VERSION "Vinfast Initial LGC"

NS_ :

BS_:

BU_: CHARGER_S VCU CHARGER_C HMI MCU REFLASH BMS1 BMS0 CLU

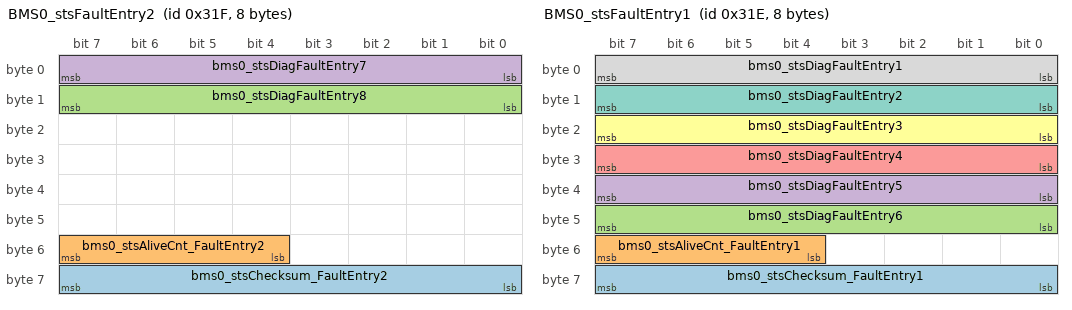
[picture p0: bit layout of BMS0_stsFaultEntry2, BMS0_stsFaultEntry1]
BO_ 799 BMS0_stsFaultEntry2: 8 BMS0
 SG_ bms0_stsChecksum_FaultEntry2 : 56|8@1+ (1,0) [0|255] ""  VCU
 SG_ bms0_stsAliveCnt_FaultEntry2 : 52|4@1+ (1,0) [0|15] ""  VCU
 SG_ bms0_stsDiagFaultEntry8 : 8|8@1+ (1,0) [0|255] ""  VCU
 SG_ bms0_stsDiagFaultEntry7 : 0|8@1+ (1,0) [0|255] ""  VCU

BO_ 798 BMS0_stsFaultEntry1: 8 BMS0
 SG_ bms0_stsChecksum_FaultEntry1 : 56|8@1+ (1,0) [0|255] ""  VCU
 SG_ bms0_stsAliveCnt_FaultEntry1 : 52|4@1+ (1,0) [0|15] ""  VCU
 SG_ bms0_stsDiagFaultEntry6 : 40|8@1+ (1,0) [0|255] ""  VCU
 SG_ bms0_stsDiagFaultEntry5 : 32|8@1+ (1,0) [0|255] ""  VCU
 SG_ bms0_stsDiagFaultEntry4 : 24|8@1+ (1,0) [0|255] ""  VCU
 SG_ bms0_stsDiagFaultEntry3 : 16|8@1+ (1,0) [0|255] ""  VCU
 SG_ bms0_stsDiagFaultEntry2 : 8|8@1+ (1,0) [0|255] ""  VCU
 SG_ bms0_stsDiagFaultEntry1 : 0|8@1+ (1,0) [0|255] ""  VCU

BO_ 780 VCU_TestMessageDiag: 8 VCU
 SG_ vfVCU_TestCmdChecksumOnOff_32F : 63|1@1+ (1,0) [0|1] "-"  BMS1,BMS0
 SG_ vfVCU_TestCmdChecksumOnOff_32E : 62|1@1+ (1,0) [0|1] "-"  BMS1,BMS0
 SG_ vfVCU_TestCmdChecksumOnOff_32A : 61|1@1+ (1,0) [0|1] "-"  BMS1,BMS0
 SG_ vfVCU_TestCmdChecksumOnOff_329 : 60|1@1+ (1,0) [0|1] "-"  BMS1,BMS0
 SG_ vfVCU_TestCmdChecksumOnOff_328 : 59|1@1+ (1,0) [0|1] "-"  BMS1,BMS0
 SG_ vfVCU_TestCmdChecksumOnOff_326 : 58|1@1+ (1,0) [0|1] "-"  BMS1,BMS0
 SG_ vfVCU_TestCmdChecksumOnOff_324 : 57|1@1+ (1,0) [0|1] "-"  BMS1,BMS0
 SG_ vfVCU_TestCmdChecksumOnOff_323 : 56|1@1+ (1,0) [0|1] "-"  BMS1,BMS0
 SG_ vfVCU_TestCmdChecksumOnOff_322 : 55|1@1+ (1,0) [0|1] "-"  BMS1,BMS0
 SG_ vfVCU_TestCmdChecksumOnOff_321 : 54|1@1+ (1,0) [0|1] "-"  BMS1,BMS0
 SG_ vfVCU_TestCmdChecksumOnOff_320 : 53|1@1+ (1,0) [0|1] "-"  BMS1,BMS0
 SG_ vfVCU_TestCmdChecksumOnOff_31F : 52|1@1+ (1,0) [0|1] "-"  BMS1,BMS0
 SG_ vfVCU_TestCmdChecksumOnOff_31E : 51|1@1+ (1,0) [0|1] "-"  BMS1,BMS0
 SG_ vfVCU_TestCmdChecksumOnOff_31A : 50|1@1+ (1,0) [0|1] "-"  BMS1,BMS0
 SG_ vfVCU_TestCmdChecksumOnOff_319 : 49|1@1+ (1,0) [0|1] "-"  BMS1,BMS0
 SG_ vfVCU_TestCmdChecksumOnOff_318 : 48|1@1+ (1,0) [0|1] "-"  BMS1,BMS0
 SG_ vfVCU_TestCmdChecksumOnOff_316 : 47|1@1+ (1,0) [0|1] "-"  BMS1,BMS0
 SG_ vfVCU_TestCmdChecksumOnOff_314 : 46|1@1+ (1,0) [0|1] "-"  BMS1,BMS0
 SG_ vfVCU_TestCmdChecksumOnOff_313 : 45|1@1+ (1,0) [0|1] "-"  BMS1,BMS0
 SG_ vfVCU_TestCmdChecksumOnOff_312 : 44|1@1+ (1,0) [0|1] "-"  BMS1,BMS0
 SG_ vfVCU_TestCmdChecksumOnOff_311 : 43|1@1+ (1,0) [0|1] "-"  BMS1,BMS0
 SG_ vfVCU_TestCmdChecksumOnOff_310 : 42|1@1+ (1,0) [0|1] "-"  BMS1,BMS0
 SG_ vfVCU_TestCmdAliveCntOnOff_32F : 39|1@1+ (1,0) [0|1] "-"  BMS1,BMS0
 SG_ vfVCU_TestCmdAliveCntOnOff_32E : 38|1@1+ (1,0) [0|1] "-"  BMS1,BMS0
 SG_ vfVCU_TestCmdAliveCntOnOff_32A : 37|1@1+ (1,0) [0|1] "-"  BMS1,BMS0
 SG_ vfVCU_TestCmdAliveCntOnOff_329 : 36|1@1+ (1,0) [0|1] "-"  BMS1,BMS0
 SG_ vfVCU_TestCmdAliveCntOnOff_328 : 35|1@1+ (1,0) [0|1] "-"  BMS1,BMS0
 SG_ vfVCU_TestCmdAliveCntOnOff_326 : 34|1@1+ (1,0) [0|1] "-"  BMS1,BMS0
 SG_ vfVCU_TestCmdAliveCntOnOff_324 : 33|1@1+ (1,0) [0|1] "-"  BMS1,BMS0
 SG_ vfVCU_TestCmdAliveCntOnOff_323 : 32|1@1+ (1,0) [0|1] "-"  BMS1,BMS0
 SG_ vfVCU_TestCmdAliveCntOnOff_322 : 31|1@1+ (1,0) [0|1] "-"  BMS1,BMS0
 SG_ vfVCU_TestCmdAliveCntOnOff_321 : 30|1@1+ (1,0) [0|1] "-"  BMS1,BMS0
 SG_ vfVCU_TestCmdAliveCntOnOff_320 : 29|1@1+ (1,0) [0|1] "-"  BMS1,BMS0
 SG_ vfVCU_TestCmdAliveCntOnOff_31F : 28|1@1+ (1,0) [0|1] "-"  BMS1,BMS0
 SG_ vfVCU_TestCmdAliveCntOnOff_31E : 27|1@1+ (1,0) [0|1] "-"  BMS1,BMS0
 SG_ vfVCU_TestCmdAliveCntOnOff_31A : 26|1@1+ (1,0) [0|1] "-"  BMS1,BMS0
 SG_ vfVCU_TestCmdAliveCntOnOff_319 : 25|1@1+ (1,0) [0|1] "-"  BMS1,BMS0
 SG_ vfVCU_TestCmdAliveCntOnOff_318 : 24|1@1+ (1,0) [0|1] "-"  BMS1,BMS0
 SG_ vfVCU_TestCmdAliveCntOnOff_316 : 23|1@1+ (1,0) [0|1] "-"  BMS1,BMS0
 SG_ vfVCU_TestCmdAliveCntOnOff_314 : 22|1@1+ (1,0) [0|1] "-"  BMS1,BMS0
 SG_ vfVCU_TestCmdAliveCntOnOff_313 : 21|1@1+ (1,0) [0|1] "-"  BMS1,BMS0
 SG_ vfVCU_TestCmdAliveCntOnOff_312 : 20|1@1+ (1,0) [0|1] "-"  BMS1,BMS0
 SG_ vfVCU_TestCmdAliveCntOnOff_311 : 19|1@1+ (1,0) [0|1] "-"  BMS1,BMS0
 SG_ vfVCU_TestCmdAliveCntOnOff_310 : 18|1@1+ (1,0) [0|1] "-"  BMS1,BMS0

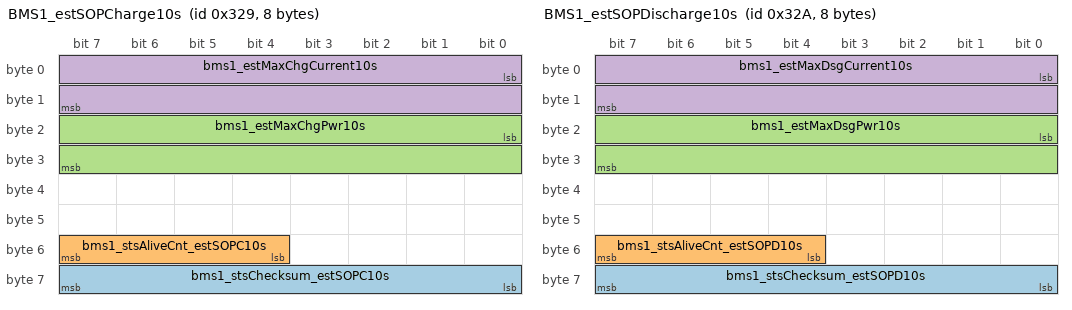
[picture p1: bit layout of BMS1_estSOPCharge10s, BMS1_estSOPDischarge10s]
BO_ 809 BMS1_estSOPCharge10s: 8 BMS1
 SG_ bms1_stsChecksum_estSOPC10s : 56|8@1+ (1,0) [0|255] ""  VCU
 SG_ bms1_stsAliveCnt_estSOPC10s : 52|4@1+ (1,0) [0|15] ""  VCU
 SG_ bms1_estMaxChgPwr10s : 16|16@1- (1,0) [-32767|32767] "W"  VCU
 SG_ bms1_estMaxChgCurrent10s : 0|16@1- (0.02,0) [-655|655] "A"  VCU

BO_ 810 BMS1_estSOPDischarge10s: 8 BMS1
 SG_ bms1_stsChecksum_estSOPD10s : 56|8@1+ (1,0) [0|255] ""  VCU
 SG_ bms1_stsAliveCnt_estSOPD10s : 52|4@1+ (1,0) [0|15] ""  VCU
 SG_ bms1_estMaxDsgPwr10s : 16|16@1- (1,0) [-32767|32767] "W"  VCU
 SG_ bms1_estMaxDsgCurrent10s : 0|16@1- (0.02,0) [-655|655] "A"  VCU

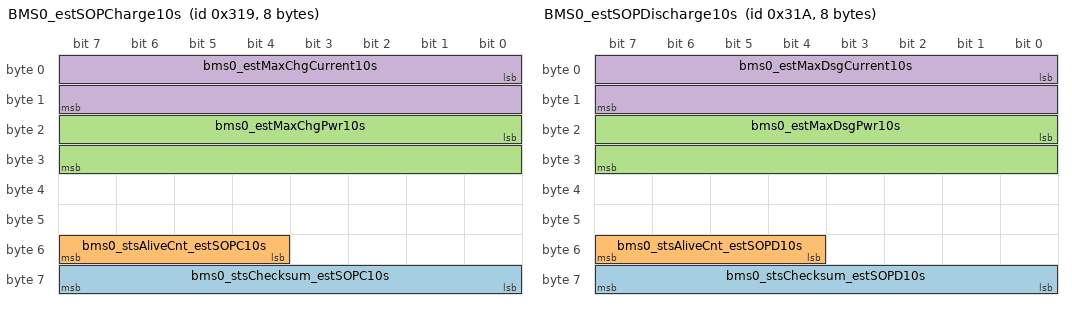
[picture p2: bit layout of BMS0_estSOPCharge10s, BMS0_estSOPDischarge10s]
BO_ 793 BMS0_estSOPCharge10s: 8 BMS0
 SG_ bms0_stsChecksum_estSOPC10s : 56|8@1+ (1,0) [0|255] ""  VCU
 SG_ bms0_stsAliveCnt_estSOPC10s : 52|4@1+ (1,0) [0|15] ""  VCU
 SG_ bms0_estMaxChgPwr10s : 16|16@1- (1,0) [-32767|32767] "W"  VCU
 SG_ bms0_estMaxChgCurrent10s : 0|16@1- (0.02,0) [-655|655] "A"  VCU

BO_ 794 BMS0_estSOPDischarge10s: 8 BMS0
 SG_ bms0_stsChecksum_estSOPD10s : 56|8@1+ (1,0) [0|255] ""  VCU
 SG_ bms0_stsAliveCnt_estSOPD10s : 52|4@1+ (1,0) [0|15] ""  VCU
 SG_ bms0_estMaxDsgPwr10s : 16|16@1- (1,0) [-32767|32767] "W"  VCU
 SG_ bms0_estMaxDsgCurrent10s : 0|16@1- (0.02,0) [-655|655] "A"  VCU

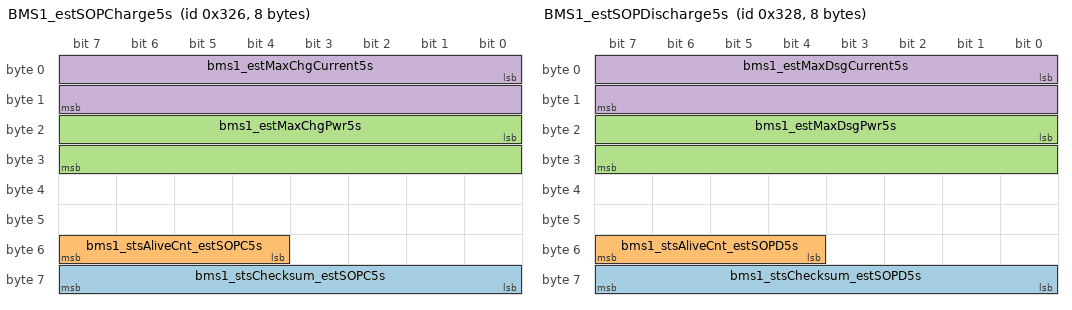
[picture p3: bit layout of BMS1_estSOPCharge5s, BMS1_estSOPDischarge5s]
BO_ 806 BMS1_estSOPCharge5s: 8 BMS1
 SG_ bms1_stsChecksum_estSOPC5s : 56|8@1+ (1,0) [0|255] ""  VCU
 SG_ bms1_stsAliveCnt_estSOPC5s : 52|4@1+ (1,0) [0|15] ""  VCU
 SG_ bms1_estMaxChgPwr5s : 16|16@1- (1,0) [-32767|32767] "W"  VCU
 SG_ bms1_estMaxChgCurrent5s : 0|16@1- (0.02,0) [-655|655] "A"  VCU

BO_ 808 BMS1_estSOPDischarge5s: 8 BMS1
 SG_ bms1_stsChecksum_estSOPD5s : 56|8@1+ (1,0) [0|255] ""  VCU
 SG_ bms1_stsAliveCnt_estSOPD5s : 52|4@1+ (1,0) [0|15] ""  VCU
 SG_ bms1_estMaxDsgPwr5s : 16|16@1- (1,0) [-32767|32767] "W"  VCU
 SG_ bms1_estMaxDsgCurrent5s : 0|16@1- (0.02,0) [-655|655] "A"  VCU

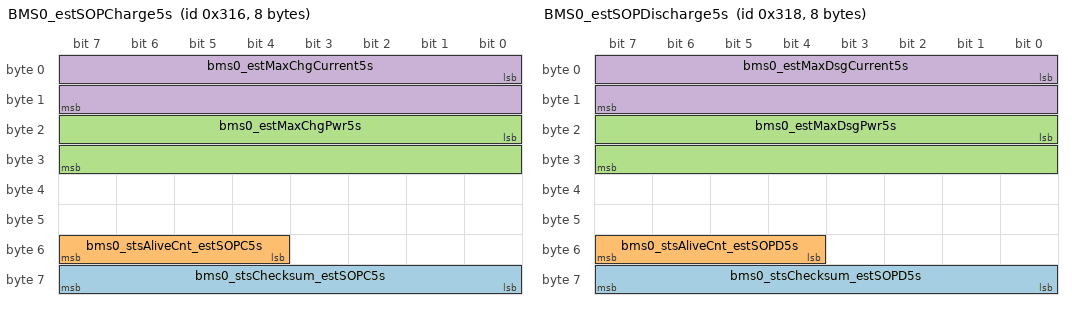
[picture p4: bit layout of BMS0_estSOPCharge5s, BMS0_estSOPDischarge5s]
BO_ 790 BMS0_estSOPCharge5s: 8 BMS0
 SG_ bms0_stsChecksum_estSOPC5s : 56|8@1+ (1,0) [0|255] ""  VCU
 SG_ bms0_stsAliveCnt_estSOPC5s : 52|4@1+ (1,0) [0|15] ""  VCU
 SG_ bms0_estMaxChgPwr5s : 16|16@1- (1,0) [-32767|32767] "W"  VCU
 SG_ bms0_estMaxChgCurrent5s : 0|16@1- (0.02,0) [-655|655] "A"  VCU

BO_ 792 BMS0_estSOPDischarge5s: 8 BMS0
 SG_ bms0_stsChecksum_estSOPD5s : 56|8@1+ (1,0) [0|255] ""  VCU
 SG_ bms0_stsAliveCnt_estSOPD5s : 52|4@1+ (1,0) [0|15] ""  VCU
 SG_ bms0_estMaxDsgPwr5s : 16|16@1- (1,0) [-32767|32767] "W"  VCU
 SG_ bms0_estMaxDsgCurrent5s : 0|16@1- (0.02,0) [-655|655] "A"  VCU

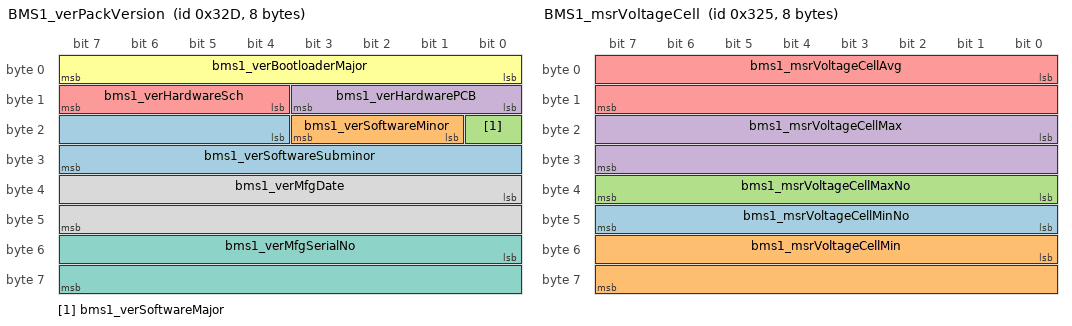
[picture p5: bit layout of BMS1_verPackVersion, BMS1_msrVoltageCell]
BO_ 813 BMS1_verPackVersion: 8 BMS1
 SG_ bms1_verSoftwareSubminor : 20|12@1+ (1,0) [0|4095] ""  BMS0,VCU
 SG_ bms1_verSoftwareMinor : 17|3@1+ (1,0) [0|7] ""  BMS0,VCU
 SG_ bms1_verSoftwareMajor : 16|1@1+ (1,0) [0|1] ""  BMS0,VCU
 SG_ bms1_verHardwarePCB : 8|4@1+ (1,0) [0|15] ""  BMS0,VCU
 SG_ bms1_verHardwareSch : 12|4@1+ (1,0) [0|15] ""  BMS0,VCU
 SG_ bms1_verBootloaderMajor : 0|8@1+ (1,0) [0|15] ""  BMS0,VCU
 SG_ bms1_verMfgSerialNo : 48|16@1+ (1,0) [0|65535] ""  BMS0,VCU
 SG_ bms1_verMfgDate : 32|16@1+ (1,0) [0|65535] ""  BMS0,VCU

BO_ 811 BMS1_stsAccumMileage: 8 BMS1
 SG_ bms1_stsAccumMileage : 0|32@1+ (1,0) [0|4294967295] "km"  VCU

BO_ 805 BMS1_msrVoltageCell: 8 BMS1
 SG_ bms1_msrVoltageCellMinNo : 40|8@1+ (1,0) [0|255] "Bank"  VCU
 SG_ bms1_msrVoltageCellMin : 48|16@1+ (0.0001,0) [0|6.5535] "V"  VCU
 SG_ bms1_msrVoltageCellMaxNo : 32|8@1+ (1,0) [0|255] "Bank"  VCU
 SG_ bms1_msrVoltageCellMax : 16|16@1+ (0.0001,0) [0|6.5535] "V"  VCU
 SG_ bms1_msrVoltageCellAvg : 0|16@1+ (0.0001,0) [0|6.5535] "V"  VCU

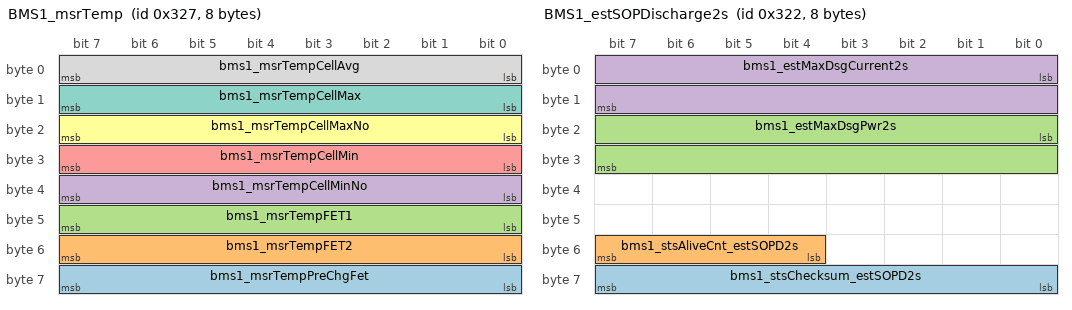
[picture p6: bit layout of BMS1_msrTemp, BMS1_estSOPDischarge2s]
BO_ 807 BMS1_msrTemp: 8 BMS1
 SG_ bms1_msrTempPreChgFet : 56|8@1- (1,0) [-127|127] "℃"  VCU
 SG_ bms1_msrTempFET2 : 48|8@1- (1,0) [-127|127] "℃"  VCU
 SG_ bms1_msrTempFET1 : 40|8@1- (1,0) [-128|127] "℃"  VCU
 SG_ bms1_msrTempCellMinNo : 32|8@1+ (1,0) [0|255] "Th"  VCU
 SG_ bms1_msrTempCellMin : 24|8@1- (1,0) [-127|127] "℃"  VCU
 SG_ bms1_msrTempCellMaxNo : 16|8@1+ (1,0) [0|255] "Th"  VCU
 SG_ bms1_msrTempCellMax : 8|8@1- (1,0) [-127|127] "℃"  VCU
 SG_ bms1_msrTempCellAvg : 0|8@1- (1,0) [-127|127] "℃"  VCU

BO_ 802 BMS1_estSOPDischarge2s: 8 BMS1
 SG_ bms1_stsChecksum_estSOPD2s : 56|8@1+ (1,0) [0|255] ""  VCU
 SG_ bms1_stsAliveCnt_estSOPD2s : 52|4@1+ (1,0) [0|15] ""  VCU
 SG_ bms1_estMaxDsgPwr2s : 16|16@1- (1,0) [-32767|32767] "W"  VCU
 SG_ bms1_estMaxDsgCurrent2s : 0|16@1- (0.02,0) [-655|655] "A"  VCU

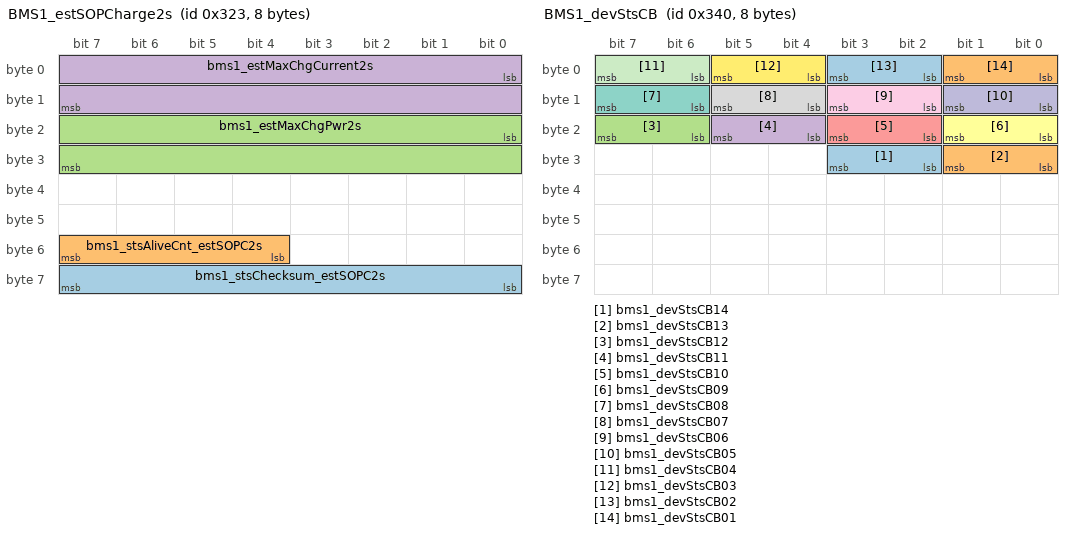
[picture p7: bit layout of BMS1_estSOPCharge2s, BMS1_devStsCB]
BO_ 803 BMS1_estSOPCharge2s: 8 BMS1
 SG_ bms1_stsChecksum_estSOPC2s : 56|8@1+ (1,0) [0|255] ""  VCU
 SG_ bms1_stsAliveCnt_estSOPC2s : 52|4@1+ (1,0) [0|15] ""  VCU
 SG_ bms1_estMaxChgPwr2s : 16|16@1- (1,0) [-32767|32767] "W"  VCU
 SG_ bms1_estMaxChgCurrent2s : 0|16@1- (0.02,0) [-655|655] "A"  VCU

BO_ 832 BMS1_devStsCB: 8 BMS1
 SG_ bms1_devStsCB14 : 26|2@1+ (1,0) [0|3] ""  VCU
 SG_ bms1_devStsCB13 : 24|2@1+ (1,0) [0|3] ""  VCU
 SG_ bms1_devStsCB12 : 22|2@1+ (1,0) [0|3] ""  VCU
 SG_ bms1_devStsCB11 : 20|2@1+ (1,0) [0|3] ""  VCU
 SG_ bms1_devStsCB10 : 18|2@1+ (1,0) [0|3] ""  VCU
 SG_ bms1_devStsCB09 : 16|2@1+ (1,0) [0|3] ""  VCU
 SG_ bms1_devStsCB08 : 14|2@1+ (1,0) [0|3] ""  VCU
 SG_ bms1_devStsCB07 : 12|2@1+ (1,0) [0|3] ""  VCU
 SG_ bms1_devStsCB06 : 10|2@1+ (1,0) [0|3] ""  VCU
 SG_ bms1_devStsCB05 : 8|2@1+ (1,0) [0|3] ""  VCU
 SG_ bms1_devStsCB04 : 6|2@1+ (1,0) [0|3] ""  VCU
 SG_ bms1_devStsCB03 : 4|2@1+ (1,0) [0|3] ""  VCU
 SG_ bms1_devStsCB02 : 2|2@1+ (1,0) [0|3] ""  VCU
 SG_ bms1_devStsCB01 : 0|2@1+ (1,0) [0|3] ""  VCU

BO_ 838 BMS1_devMsrTemp: 8 BMS1
 SG_ bms1_devCbOnCnt : 24|8@1+ (1,0) [0|255] "" Vector__XXX
 SG_ bms1_devTopCellOffset : 16|8@1+ (1,0) [0|255] "mV" Vector__XXX
 SG_ bms1_devVoltageCellDiff : 8|8@1+ (1,0) [0|255] "mV" Vector__XXX
 SG_ bms1_devMsrTempCB1 : 0|8@1- (1,0) [-127|127] "℃"  VCU

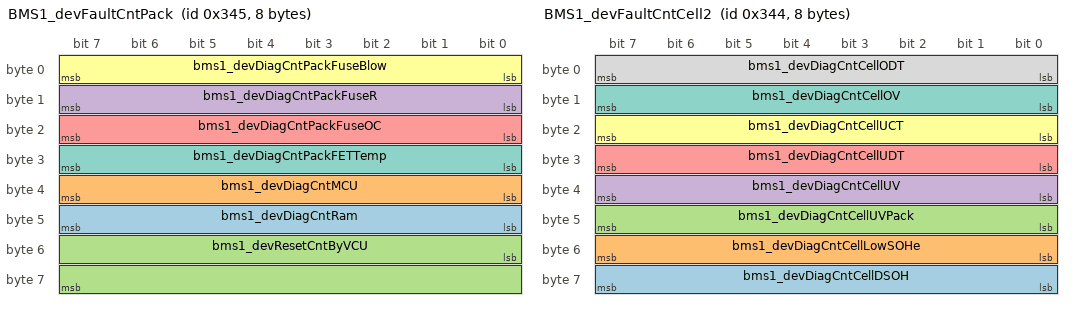
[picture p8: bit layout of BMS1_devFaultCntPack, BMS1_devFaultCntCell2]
BO_ 837 BMS1_devFaultCntPack: 8 BMS1
 SG_ bms1_devDiagCntRam : 40|8@1+ (1,0) [0|255] "" Vector__XXX
 SG_ bms1_devDiagCntMCU : 32|8@1+ (1,0) [0|255] "" Vector__XXX
 SG_ bms1_devResetCntByVCU : 48|16@1+ (1,0) [0|65535] "" Vector__XXX
 SG_ bms1_devDiagCntPackFuseR : 8|8@1+ (1,0) [0|255] ""  VCU
 SG_ bms1_devDiagCntPackFuseOC : 16|8@1+ (1,0) [0|255] ""  VCU
 SG_ bms1_devDiagCntPackFuseBlow : 0|8@1+ (1,0) [0|255] ""  VCU
 SG_ bms1_devDiagCntPackFETTemp : 24|8@1+ (1,0) [0|255] ""  VCU

BO_ 836 BMS1_devFaultCntCell2: 8 BMS1
 SG_ bms1_devDiagCntCellDSOH : 56|8@1+ (1,0) [0|255] "" Vector__XXX
 SG_ bms1_devDiagCntCellLowSOHe : 48|8@1+ (1,0) [0|255] "" Vector__XXX
 SG_ bms1_devDiagCntCellUVPack : 40|8@1+ (1,0) [0|255] ""  VCU
 SG_ bms1_devDiagCntCellUV : 32|8@1+ (1,0) [0|255] ""  VCU
 SG_ bms1_devDiagCntCellUDT : 24|8@1+ (1,0) [0|255] ""  VCU
 SG_ bms1_devDiagCntCellUCT : 16|8@1+ (1,0) [0|255] ""  VCU
 SG_ bms1_devDiagCntCellOV : 8|8@1+ (1,0) [0|255] ""  VCU
 SG_ bms1_devDiagCntCellODT : 0|8@1+ (1,0) [0|255] ""  VCU

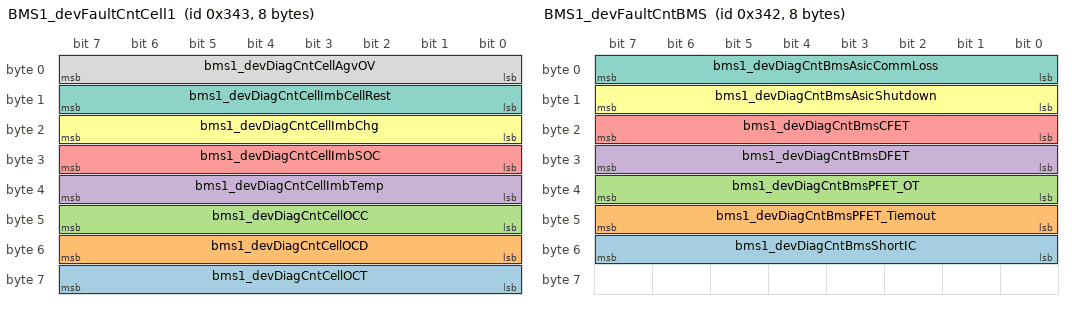
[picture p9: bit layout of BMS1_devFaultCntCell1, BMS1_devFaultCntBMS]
BO_ 835 BMS1_devFaultCntCell1: 8 BMS1
 SG_ bms1_devDiagCntCellOCT : 56|8@1+ (1,0) [0|255] ""  VCU
 SG_ bms1_devDiagCntCellOCD : 48|8@1+ (1,0) [0|255] ""  VCU
 SG_ bms1_devDiagCntCellOCC : 40|8@1+ (1,0) [0|255] ""  VCU
 SG_ bms1_devDiagCntCellImbTemp : 32|8@1+ (1,0) [0|255] ""  VCU
 SG_ bms1_devDiagCntCellImbSOC : 24|8@1+ (1,0) [0|255] ""  VCU
 SG_ bms1_devDiagCntCellImbChg : 16|8@1+ (1,0) [0|255] ""  VCU
 SG_ bms1_devDiagCntCellImbCellRest : 8|8@1+ (1,0) [0|255] ""  VCU
 SG_ bms1_devDiagCntCellAgvOV : 0|8@1+ (1,0) [0|255] ""  VCU

BO_ 834 BMS1_devFaultCntBMS: 8 BMS1
 SG_ bms1_devDiagCntBmsShortIC : 48|8@1+ (1,0) [0|255] "" Vector__XXX
 SG_ bms1_devDiagCntBmsPFET_Tiemout : 40|8@1+ (1,0) [0|255] ""  VCU
 SG_ bms1_devDiagCntBmsPFET_OT : 32|8@1+ (1,0) [0|255] ""  VCU
 SG_ bms1_devDiagCntBmsDFET : 24|8@1+ (1,0) [0|255] ""  VCU
 SG_ bms1_devDiagCntBmsCFET : 16|8@1+ (1,0) [0|255] ""  VCU
 SG_ bms1_devDiagCntBmsAsicShutdown : 8|8@1+ (1,0) [0|255] ""  VCU
 SG_ bms1_devDiagCntBmsAsicCommLoss : 0|8@1+ (1,0) [0|255] ""  VCU

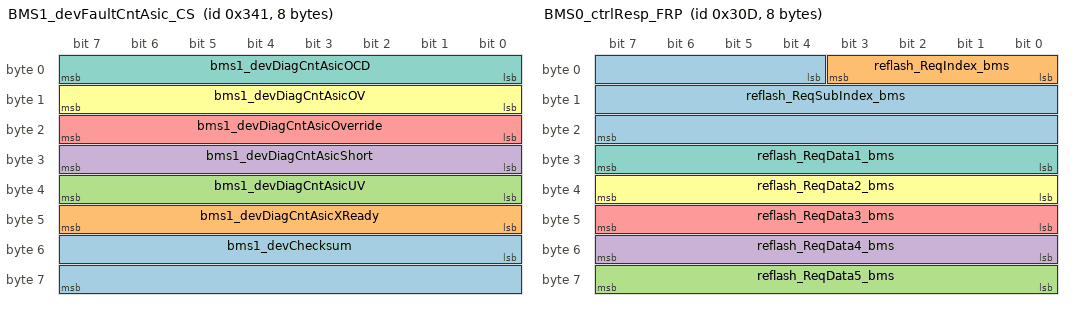
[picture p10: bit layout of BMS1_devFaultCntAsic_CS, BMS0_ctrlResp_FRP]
BO_ 833 BMS1_devFaultCntAsic_CS: 8 BMS1
 SG_ bms1_devChecksum : 48|16@1+ (1,0) [0|65535] "" Vector__XXX
 SG_ bms1_devDiagCntAsicXReady : 40|8@1+ (1,0) [0|255] ""  VCU
 SG_ bms1_devDiagCntAsicUV : 32|8@1+ (1,0) [0|255] ""  VCU
 SG_ bms1_devDiagCntAsicShort : 24|8@1+ (1,0) [0|255] ""  VCU
 SG_ bms1_devDiagCntAsicOverride : 16|8@1+ (1,0) [0|255] ""  VCU
 SG_ bms1_devDiagCntAsicOV : 8|8@1+ (1,0) [0|255] ""  VCU
 SG_ bms1_devDiagCntAsicOCD : 0|8@1+ (1,0) [0|255] ""  VCU

BO_ 843 BMS1_devCellVolt3: 8 BMS1
 SG_ bms1_devVoltageCell14 : 16|16@1+ (0.0001,0) [0|6.5535] "V"  VCU
 SG_ bms1_devVoltageCell13 : 0|16@1+ (0.0001,0) [0|6.5535] "V"  VCU

BO_ 842 BMS1_devCellVolt2: 8 BMS1
 SG_ bms1_devVoltageCell12 : 48|16@1+ (0.0001,0) [0|6.5535] "V"  VCU
 SG_ bms1_devVoltageCell11 : 32|16@1+ (0.0001,0) [0|6.5535] "V"  VCU
 SG_ bms1_devVoltageCell10 : 16|16@1+ (0.0001,0) [0|6.5535] "V"  VCU
 SG_ bms1_devVoltageCell09 : 0|16@1+ (0.0001,0) [0|6.5535] "V"  VCU

BO_ 841 BMS1_devCellVolt1: 8 BMS1
 SG_ bms1_devVoltageCell08 : 48|16@1+ (0.0001,0) [0|6.5535] "V"  VCU
 SG_ bms1_devVoltageCell07 : 32|16@1+ (0.0001,0) [0|6.5535] "V"  VCU
 SG_ bms1_devVoltageCell06 : 16|16@1+ (0.0001,0) [0|6.5535] "V"  VCU
 SG_ bms1_devVoltageCell05 : 0|16@1+ (0.0001,0) [0|6.5535] "V"  VCU

BO_ 840 BMS1_devCellVolt0: 8 BMS1
 SG_ bms1_devVoltageCell04 : 48|16@1+ (0.0001,0) [0|6.5535] "V"  VCU
 SG_ bms1_devVoltageCell03 : 32|16@1+ (0.0001,0) [0|6.5535] "V"  VCU
 SG_ bms1_devVoltageCell02 : 16|16@1+ (0.0001,0) [0|6.5535] "V"  VCU
 SG_ bms1_devVoltageCell01 : 0|16@1+ (0.0001,0) [0|6.5535] "V"  VCU

BO_ 827 BMS0_devCellVolt3: 8 BMS0
 SG_ bms0_devVoltageCell14 : 16|16@1+ (0.0001,0) [0|6.5535] "V"  VCU
 SG_ bms0_devVoltageCell13 : 0|16@1+ (0.0001,0) [0|6.5535] "V"  VCU

BO_ 826 BMS0_devCellVolt2: 8 BMS0
 SG_ bms0_devVoltageCell12 : 48|16@1+ (0.0001,0) [0|6.5535] "V"  VCU
 SG_ bms0_devVoltageCell11 : 32|16@1+ (0.0001,0) [0|6.5535] "V"  VCU
 SG_ bms0_devVoltageCell10 : 16|16@1+ (0.0001,0) [0|6.5535] "V"  VCU
 SG_ bms0_devVoltageCell09 : 0|16@1+ (0.0001,0) [0|6.5535] "V"  VCU

BO_ 824 BMS0_devCellVolt0: 8 BMS0
 SG_ bms0_devVoltageCell04 : 48|16@1+ (0.0001,0) [0|6.5535] "V"  VCU
 SG_ bms0_devVoltageCell03 : 32|16@1+ (0.0001,0) [0|6.5535] "V"  VCU
 SG_ bms0_devVoltageCell02 : 16|16@1+ (0.0001,0) [0|6.5535] "V"  VCU
 SG_ bms0_devVoltageCell01 : 0|16@1+ (0.0001,0) [0|6.5535] "V"  VCU

BO_ 825 BMS0_devCellVolt1: 8 BMS0
 SG_ bms0_devVoltageCell08 : 48|16@1+ (0.0001,0) [0|6.5535] "V"  VCU
 SG_ bms0_devVoltageCell07 : 32|16@1+ (0.0001,0) [0|6.5535] "V"  VCU
 SG_ bms0_devVoltageCell06 : 16|16@1+ (0.0001,0) [0|6.5535] "V"  VCU
 SG_ bms0_devVoltageCell05 : 0|16@1+ (0.0001,0) [0|6.5535] "V" Vector__XXX

BO_ 781 BMS0_ctrlResp_FRP: 8 BMS0
 SG_ reflash_ReqSubIndex_bms : 4|20@1+ (1,0) [0|1048575] ""  REFLASH
 SG_ reflash_ReqIndex_bms : 0|4@1+ (1,0) [0|15] ""  REFLASH
 SG_ reflash_ReqData5_bms : 56|8@1+ (1,0) [0|255] ""  REFLASH
 SG_ reflash_ReqData4_bms : 48|8@1+ (1,0) [0|255] ""  REFLASH
 SG_ reflash_ReqData3_bms : 40|8@1+ (1,0) [0|255] ""  REFLASH
 SG_ reflash_ReqData2_bms : 32|8@1+ (1,0) [0|255] ""  REFLASH
 SG_ reflash_ReqData1_bms : 24|8@1+ (1,0) [0|255] ""  REFLASH

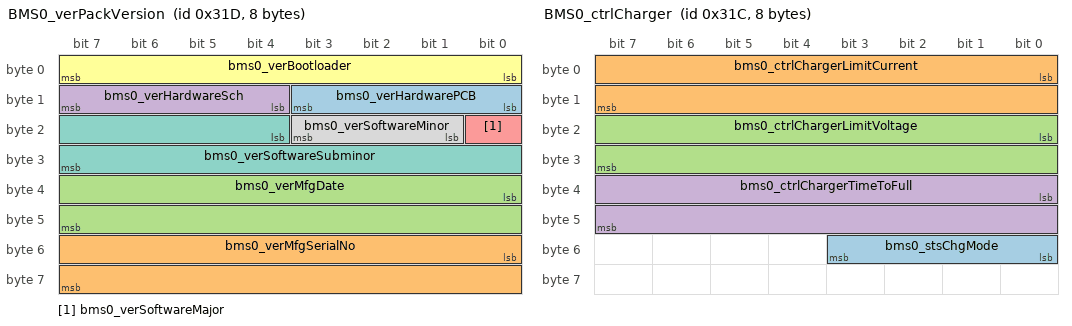
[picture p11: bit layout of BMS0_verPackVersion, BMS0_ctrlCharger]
BO_ 797 BMS0_verPackVersion: 8 BMS0
 SG_ bms0_verHardwarePCB : 8|4@1+ (1,0) [0|15] ""  VCU,BMS1
 SG_ bms0_verMfgSerialNo : 48|16@1+ (1,0) [0|65535] ""  BMS1,VCU
 SG_ bms0_verMfgDate : 32|16@1+ (1,0) [0|65535] ""  BMS1,VCU
 SG_ bms0_verHardwareSch : 12|4@1+ (1,0) [0|15] ""  BMS1,VCU
 SG_ bms0_verSoftwareMajor : 16|1@1+ (1,0) [0|1] ""  BMS1,VCU
 SG_ bms0_verBootloader : 0|8@1+ (1,0) [0|15] ""  BMS1,VCU
 SG_ bms0_verSoftwareSubminor : 20|12@1+ (1,0) [0|4095] ""  BMS1,VCU
 SG_ bms0_verSoftwareMinor : 17|3@1+ (1,0) [0|7] ""  BMS1,VCU

BO_ 796 BMS0_ctrlCharger: 8 BMS0
 SG_ bms0_stsChgMode : 48|4@1+ (1,0) [0|15] "" Vector__XXX
 SG_ bms0_ctrlChargerLimitCurrent : 0|16@1- (0.02,0) [-655|655] "A"  CHARGER_S,CHARGER_C,VCU
 SG_ bms0_ctrlChargerLimitVoltage : 16|16@1+ (0.002,0) [0|131.07] "V"  CHARGER_S,CHARGER_C,VCU
 SG_ bms0_ctrlChargerTimeToFull : 32|16@1+ (1,0) [0|65535] "min"  CHARGER_C,VCU

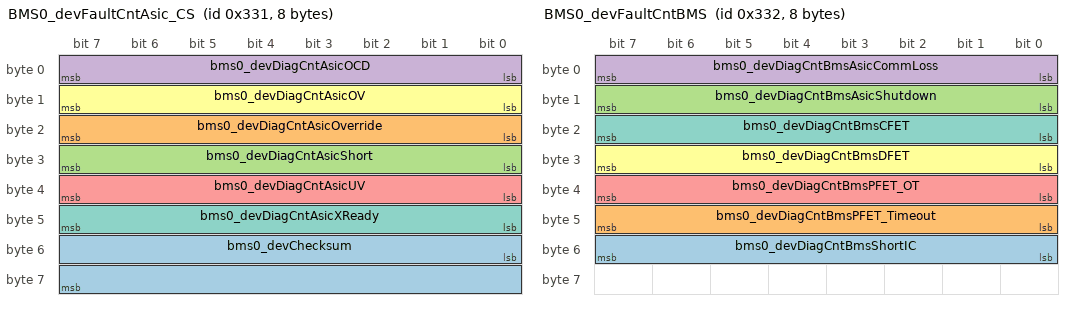
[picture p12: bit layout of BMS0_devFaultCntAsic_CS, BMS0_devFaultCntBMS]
BO_ 817 BMS0_devFaultCntAsic_CS: 8 BMS0
 SG_ bms0_devChecksum : 48|16@1+ (1,0) [0|65535] "" Vector__XXX
 SG_ bms0_devDiagCntAsicOverride : 16|8@1+ (1,0) [0|255] ""  VCU
 SG_ bms0_devDiagCntAsicShort : 24|8@1+ (1,0) [0|255] ""  VCU
 SG_ bms0_devDiagCntAsicOCD : 0|8@1+ (1,0) [0|255] ""  VCU
 SG_ bms0_devDiagCntAsicUV : 32|8@1+ (1,0) [0|255] ""  VCU
 SG_ bms0_devDiagCntAsicOV : 8|8@1+ (1,0) [0|255] ""  VCU
 SG_ bms0_devDiagCntAsicXReady : 40|8@1+ (1,0) [0|255] ""  VCU

BO_ 818 BMS0_devFaultCntBMS: 8 BMS0
 SG_ bms0_devDiagCntBmsShortIC : 48|8@1+ (1,0) [0|255] "" Vector__XXX
 SG_ bms0_devDiagCntBmsPFET_Timeout : 40|8@1+ (1,0) [0|255] ""  VCU
 SG_ bms0_devDiagCntBmsAsicShutdown : 8|8@1+ (1,0) [0|255] ""  VCU
 SG_ bms0_devDiagCntBmsAsicCommLoss : 0|8@1+ (1,0) [0|255] ""  VCU
 SG_ bms0_devDiagCntBmsPFET_OT : 32|8@1+ (1,0) [0|255] ""  VCU
 SG_ bms0_devDiagCntBmsDFET : 24|8@1+ (1,0) [0|255] ""  VCU
 SG_ bms0_devDiagCntBmsCFET : 16|8@1+ (1,0) [0|255] ""  VCU

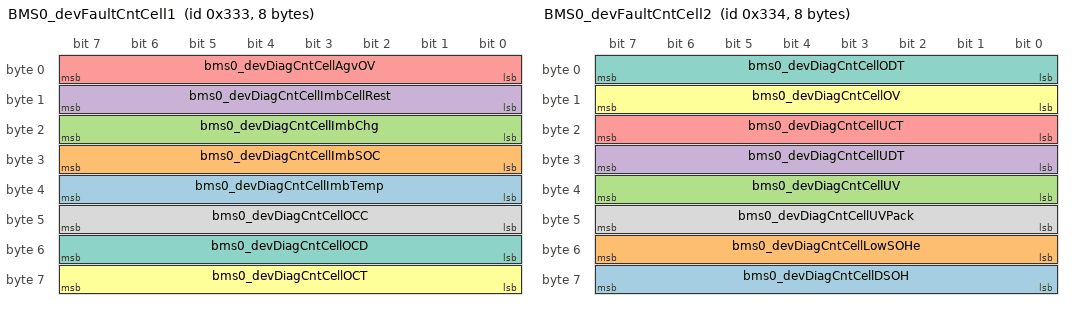
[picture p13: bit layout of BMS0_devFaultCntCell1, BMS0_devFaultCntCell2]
BO_ 819 BMS0_devFaultCntCell1: 8 BMS0
 SG_ bms0_devDiagCntCellImbTemp : 32|8@1+ (1,0) [0|255] ""  VCU
 SG_ bms0_devDiagCntCellImbSOC : 24|8@1+ (1,0) [0|255] ""  VCU
 SG_ bms0_devDiagCntCellImbChg : 16|8@1+ (1,0) [0|255] ""  VCU
 SG_ bms0_devDiagCntCellImbCellRest : 8|8@1+ (1,0) [0|255] ""  VCU
 SG_ bms0_devDiagCntCellAgvOV : 0|8@1+ (1,0) [0|255] ""  VCU
 SG_ bms0_devDiagCntCellOCT : 56|8@1+ (1,0) [0|255] ""  VCU
 SG_ bms0_devDiagCntCellOCD : 48|8@1+ (1,0) [0|255] ""  VCU
 SG_ bms0_devDiagCntCellOCC : 40|8@1+ (1,0) [0|255] ""  VCU

BO_ 820 BMS0_devFaultCntCell2: 8 BMS0
 SG_ bms0_devDiagCntCellDSOH : 56|8@1+ (1,0) [0|255] "" Vector__XXX
 SG_ bms0_devDiagCntCellLowSOHe : 48|8@1+ (1,0) [0|255] "" Vector__XXX
 SG_ bms0_devDiagCntCellUV : 32|8@1+ (1,0) [0|255] ""  VCU
 SG_ bms0_devDiagCntCellUDT : 24|8@1+ (1,0) [0|255] ""  VCU
 SG_ bms0_devDiagCntCellUCT : 16|8@1+ (1,0) [0|255] ""  VCU
 SG_ bms0_devDiagCntCellOV : 8|8@1+ (1,0) [0|255] ""  VCU
 SG_ bms0_devDiagCntCellODT : 0|8@1+ (1,0) [0|255] ""  VCU
 SG_ bms0_devDiagCntCellUVPack : 40|8@1+ (1,0) [0|255] ""  VCU

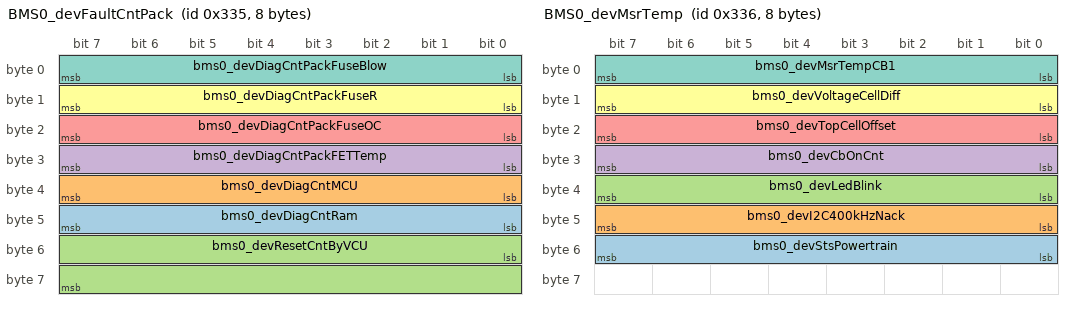
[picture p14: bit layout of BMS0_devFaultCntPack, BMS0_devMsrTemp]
BO_ 821 BMS0_devFaultCntPack: 8 BMS0
 SG_ bms0_devDiagCntRam : 40|8@1+ (1,0) [0|255] "" Vector__XXX
 SG_ bms0_devDiagCntMCU : 32|8@1+ (1,0) [0|255] "" Vector__XXX
 SG_ bms0_devResetCntByVCU : 48|16@1+ (1,0) [0|65535] "" Vector__XXX
 SG_ bms0_devDiagCntPackFETTemp : 24|8@1+ (1,0) [0|255] ""  VCU
 SG_ bms0_devDiagCntPackFuseOC : 16|8@1+ (1,0) [0|255] ""  VCU
 SG_ bms0_devDiagCntPackFuseR : 8|8@1+ (1,0) [0|255] ""  VCU
 SG_ bms0_devDiagCntPackFuseBlow : 0|8@1+ (1,0) [0|255] ""  VCU

BO_ 822 BMS0_devMsrTemp: 8 BMS0
 SG_ bms0_devStsPowertrain : 48|8@1+ (1,0) [0|255] "" Vector__XXX
 SG_ bms0_devI2C400kHzNack : 40|8@1+ (1,0) [0|255] "" Vector__XXX
 SG_ bms0_devLedBlink : 32|8@1+ (1,0) [0|255] "" Vector__XXX
 SG_ bms0_devCbOnCnt : 24|8@1+ (1,0) [0|255] "" Vector__XXX
 SG_ bms0_devTopCellOffset : 16|8@1+ (1,0) [0|255] "mV" Vector__XXX
 SG_ bms0_devVoltageCellDiff : 8|8@1+ (1,0) [0|255] "mV" Vector__XXX
 SG_ bms0_devMsrTempCB1 : 0|8@1- (1,0) [-127|127] "℃"  VCU

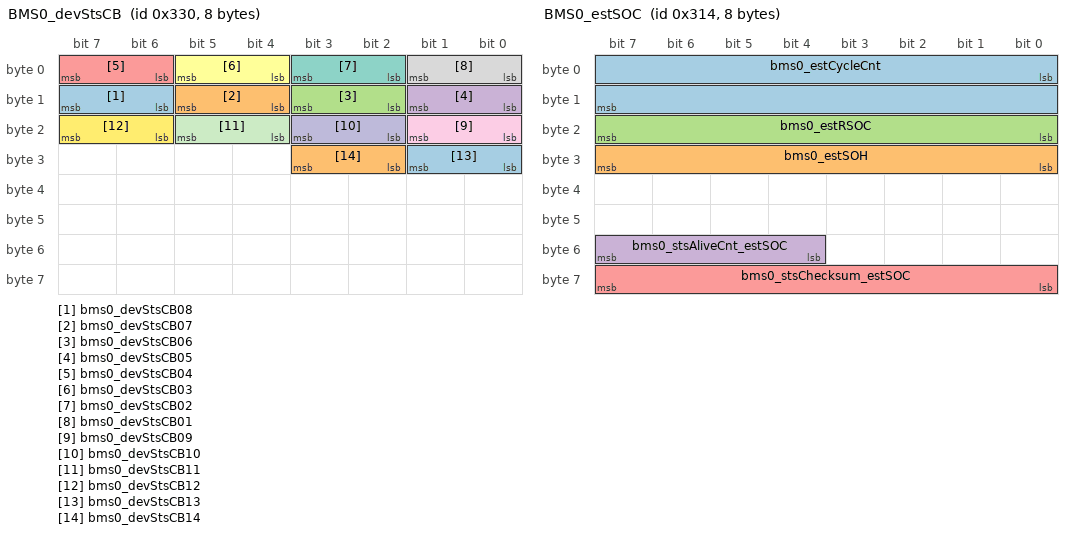
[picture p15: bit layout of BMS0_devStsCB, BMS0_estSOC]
BO_ 816 BMS0_devStsCB: 8 BMS0
 SG_ bms0_devStsCB08 : 14|2@1+ (1,0) [0|3] ""  VCU
 SG_ bms0_devStsCB07 : 12|2@1+ (1,0) [0|3] ""  VCU
 SG_ bms0_devStsCB06 : 10|2@1+ (1,0) [0|3] ""  VCU
 SG_ bms0_devStsCB05 : 8|2@1+ (1,0) [0|3] ""  VCU
 SG_ bms0_devStsCB04 : 6|2@1+ (1,0) [0|3] ""  VCU
 SG_ bms0_devStsCB03 : 4|2@1+ (1,0) [0|3] ""  VCU
 SG_ bms0_devStsCB02 : 2|2@1+ (1,0) [0|3] ""  VCU
 SG_ bms0_devStsCB01 : 0|2@1+ (1,0) [0|3] ""  VCU
 SG_ bms0_devStsCB09 : 16|2@1+ (1,0) [0|3] ""  VCU
 SG_ bms0_devStsCB10 : 18|2@1+ (1,0) [0|3] ""  VCU
 SG_ bms0_devStsCB11 : 20|2@1+ (1,0) [0|3] ""  VCU
 SG_ bms0_devStsCB12 : 22|2@1+ (1,0) [0|3] ""  VCU
 SG_ bms0_devStsCB13 : 24|2@1+ (1,0) [0|3] ""  VCU
 SG_ bms0_devStsCB14 : 26|2@1+ (1,0) [0|3] ""  VCU

BO_ 788 BMS0_estSOC: 8 BMS0
 SG_ bms0_estCycleCnt : 0|16@1+ (1,0) [0|65535] ""  CHARGER_C,VCU
 SG_ bms0_estSOH : 24|8@1+ (1,0) [0|255] "%"  CHARGER_S,CHARGER_C,VCU
 SG_ bms0_estRSOC : 16|8@1+ (1,0) [0|255] "%"  CHARGER_S,CHARGER_C,VCU
 SG_ bms0_stsAliveCnt_estSOC : 52|4@1+ (1,0) [0|15] ""  CHARGER_C,VCU
 SG_ bms0_stsChecksum_estSOC : 56|8@1+ (1,0) [0|255] ""  CHARGER_C,VCU

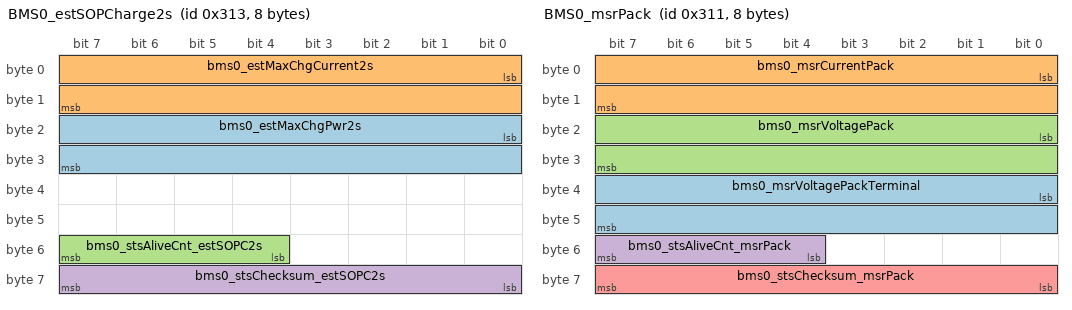
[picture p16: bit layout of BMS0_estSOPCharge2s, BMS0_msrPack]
BO_ 787 BMS0_estSOPCharge2s: 8 BMS0
 SG_ bms0_estMaxChgPwr2s : 16|16@1- (1,0) [-32767|32767] "W"  VCU
 SG_ bms0_estMaxChgCurrent2s : 0|16@1- (0.02,0) [-655|655] "A"  VCU
 SG_ bms0_stsAliveCnt_estSOPC2s : 52|4@1+ (1,0) [0|15] ""  VCU
 SG_ bms0_stsChecksum_estSOPC2s : 56|8@1+ (1,0) [0|255] ""  VCU

BO_ 785 BMS0_msrPack: 8 BMS0
 SG_ bms0_msrVoltagePackTerminal : 32|16@1+ (0.002,0) [0|131.07] "V"  CHARGER_S,CHARGER_C,VCU
 SG_ bms0_msrCurrentPack : 0|16@1- (0.02,0) [-655|655] "A"  CHARGER_S,CHARGER_C,VCU
 SG_ bms0_msrVoltagePack : 16|16@1+ (0.002,0) [0|131.07] "V"  CHARGER_S,CHARGER_C,VCU
 SG_ bms0_stsAliveCnt_msrPack : 52|4@1+ (1,0) [0|15] ""  CHARGER_C,VCU
 SG_ bms0_stsChecksum_msrPack : 56|8@1+ (1,0) [0|255] ""  CHARGER_C,VCU

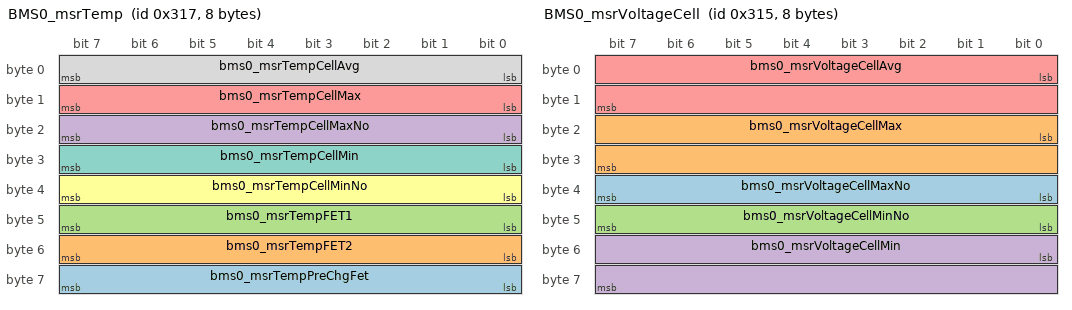
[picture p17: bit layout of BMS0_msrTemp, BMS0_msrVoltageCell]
BO_ 791 BMS0_msrTemp: 8 BMS0
 SG_ bms0_msrTempPreChgFet : 56|8@1- (1,0) [-127|127] "℃"  VCU
 SG_ bms0_msrTempFET2 : 48|8@1- (1,0) [-127|127] "℃"  VCU
 SG_ bms0_msrTempFET1 : 40|8@1- (1,0) [-128|127] "℃"  VCU
 SG_ bms0_msrTempCellMaxNo : 16|8@1+ (1,0) [0|255] "Th"  VCU
 SG_ bms0_msrTempCellMax : 8|8@1- (1,0) [-127|127] "℃"  VCU
 SG_ bms0_msrTempCellMinNo : 32|8@1+ (1,0) [0|255] "Th"  VCU
 SG_ bms0_msrTempCellMin : 24|8@1- (1,0) [-127|127] "℃"  VCU
 SG_ bms0_msrTempCellAvg : 0|8@1- (1,0) [-127|127] "℃"  VCU

BO_ 789 BMS0_msrVoltageCell: 8 BMS0
 SG_ bms0_msrVoltageCellMaxNo : 32|8@1+ (1,0) [0|255] "Bank"  VCU
 SG_ bms0_msrVoltageCellMax : 16|16@1+ (0.0001,0) [0|6.5535] "V"  VCU
 SG_ bms0_msrVoltageCellMinNo : 40|8@1+ (1,0) [0|255] "Bank"  VCU
 SG_ bms0_msrVoltageCellMin : 48|16@1+ (0.0001,0) [0|6.5535] "V"  VCU
 SG_ bms0_msrVoltageCellAvg : 0|16@1+ (0.0001,0) [0|6.5535] "V"  VCU

BO_ 795 BMS0_stsAccumMileage: 8 BMS0
 SG_ bms0_stsAccumMileage : 0|32@1+ (1,0) [0|4294967295] "km"  VCU

BO_ 786 BMS0_estSOPDischarge2s: 8 BMS0
 SG_ bms0_stsChecksum_estSOPD2s : 56|8@1+ (1,0) [0|255] ""  VCU
 SG_ bms0_stsAliveCnt_estSOPD2s : 52|4@1+ (1,0) [0|15] ""  VCU
 SG_ bms0_estMaxDsgCurrent2s : 0|16@1- (0.02,0) [-655|655] "A"  VCU
 SG_ bms0_estMaxDsgPwr2s : 16|16@1- (1,0) [-32767|32767] "W"  VCU

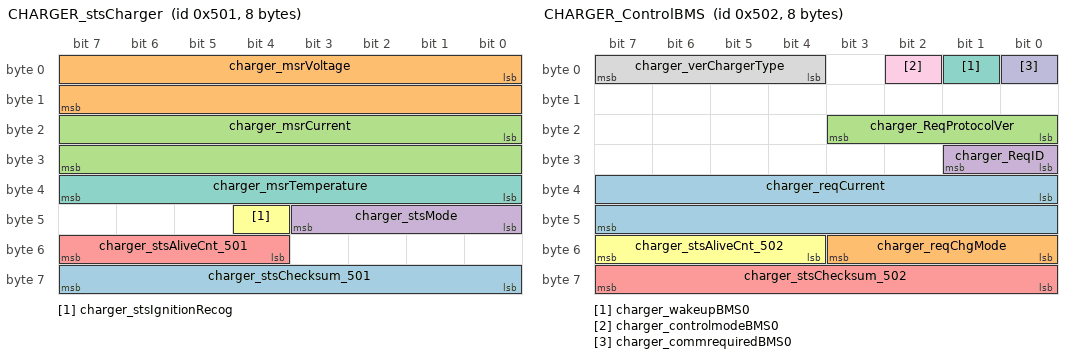
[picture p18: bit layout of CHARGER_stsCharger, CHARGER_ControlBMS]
BO_ 1281 CHARGER_stsCharger: 8 CHARGER_C
 SG_ charger_stsChecksum_501 : 56|8@1+ (1,0) [0|255] ""  BMS1,BMS0,VCU
 SG_ charger_msrVoltage : 0|16@1+ (0.002,0) [0|131.07] "V"  BMS1,BMS0,VCU
 SG_ charger_msrCurrent : 16|16@1- (0.02,0) [-655.36|655.34] "A"  BMS1,VCU,BMS0
 SG_ charger_stsMode : 40|4@1+ (1,0) [0|15] ""  BMS1,VCU,BMS0,HMI
 SG_ charger_stsAliveCnt_501 : 52|4@1+ (1,0) [0|15] ""  BMS1,VCU,BMS0
 SG_ charger_stsIgnitionRecog : 44|1@1+ (1,0) [0|1] ""  BMS1,VCU,BMS0
 SG_ charger_msrTemperature : 32|8@1- (1,0) [-128|127] "℃"  BMS1,VCU,BMS0

BO_ 1282 CHARGER_ControlBMS: 8 CHARGER_C
 SG_ charger_reqCurrent : 32|16@1- (0.02,0) [-655.36|655.34] "A" Vector__XXX
 SG_ charger_reqChgMode : 48|4@1+ (1,0) [0|15] "" Vector__XXX
 SG_ charger_ReqProtocolVer : 16|4@1+ (1,0) [0|15] "" Vector__XXX
 SG_ charger_ReqID : 24|2@1+ (1,0) [0|3] "" Vector__XXX
 SG_ charger_stsChecksum_502 : 56|8@1+ (1,0) [0|255] ""  BMS1,BMS0
 SG_ charger_stsAliveCnt_502 : 52|4@1+ (1,0) [0|15] ""  BMS1,BMS0
 SG_ charger_wakeupBMS0 : 1|1@1+ (1,0) [0|1] "-"  BMS1,BMS0
 SG_ charger_verChargerType : 4|4@1+ (1,0) [0|15] ""  BMS1,BMS0
 SG_ charger_controlmodeBMS0 : 2|1@1+ (1,0) [0|1] ""  BMS1,BMS0,HMI
 SG_ charger_commrequiredBMS0 : 0|1@1+ (1,0) [0|1] ""  BMS1,BMS0

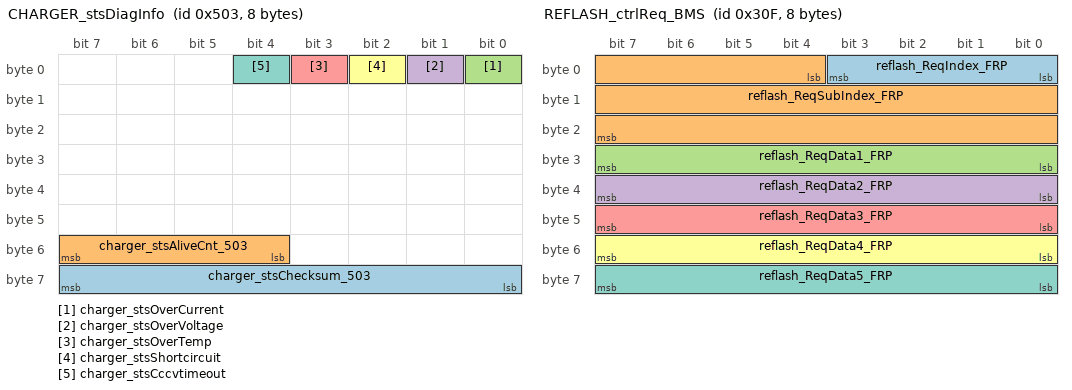
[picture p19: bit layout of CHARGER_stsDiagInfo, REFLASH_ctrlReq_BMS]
BO_ 1283 CHARGER_stsDiagInfo: 8 CHARGER_C
 SG_ charger_stsChecksum_503 : 56|8@1+ (1,0) [0|255] ""  BMS1,BMS0,VCU
 SG_ charger_stsAliveCnt_503 : 52|4@1+ (1,0) [0|15] ""  BMS1,BMS0,VCU
 SG_ charger_stsOverCurrent : 0|1@1+ (1,0) [0|1] ""  BMS1,BMS0,VCU,HMI
 SG_ charger_stsOverVoltage : 1|1@1+ (1,0) [0|1] ""  BMS1,BMS0,VCU,HMI
 SG_ charger_stsOverTemp : 3|1@1+ (1,0) [0|1] ""  BMS1,BMS0,VCU,HMI
 SG_ charger_stsShortcircuit : 2|1@1+ (1,0) [0|1] ""  BMS1,BMS0,VCU,HMI
 SG_ charger_stsCccvtimeout : 4|1@1+ (1,0) [0|1] ""  BMS1,VCU,BMS0,HMI

BO_ 783 REFLASH_ctrlReq_BMS: 8 REFLASH
 SG_ reflash_ReqIndex_FRP : 0|4@1+ (1,0) [0|15] ""  BMS0
 SG_ reflash_ReqSubIndex_FRP : 4|20@1+ (1,0) [0|1048575] ""  BMS0
 SG_ reflash_ReqData1_FRP : 24|8@1+ (1,0) [0|255] ""  BMS0
 SG_ reflash_ReqData2_FRP : 32|8@1+ (1,0) [0|255] ""  BMS0
 SG_ reflash_ReqData3_FRP : 40|8@1+ (1,0) [0|255] ""  BMS0
 SG_ reflash_ReqData4_FRP : 48|8@1+ (1,0) [0|255] ""  BMS0
 SG_ reflash_ReqData5_FRP : 56|8@1+ (1,0) [0|255] ""  BMS0

BO_ 784 BMS0_stsBMS: 8 BMS0
 SG_ bms0_stsAbnormalChargerCtrl : 48|1@1+ (1,0) [0|1] "" Vector__XXX
 SG_ bms0_stsLowSoheAlarm : 49|1@1+ (1,0) [0|1] "" Vector__XXX
 SG_ bms0_stsToogleRunning : 51|1@1+ (1,0) [0|1] "-"  VCU
 SG_ bms0_stsToogleMesaure : 50|1@1+ (1,0) [0|1] "-"  VCU
 SG_ bms0_DiagMsg_VCU_Status : 38|2@1+ (1,0) [0|3] ""  VCU
 SG_ bms0_DiagMsg_VCU_ODO : 36|2@1+ (1,0) [0|3] ""  VCU
 SG_ bms0_DiagMsg_VCU_Control : 34|2@1+ (1,0) [0|3] ""  VCU
 SG_ bms0_DiagMsg_Charger_Status : 32|2@1+ (1,0) [0|3] ""  CHARGER_S,CHARGER_C,VCU
 SG_ bms0_DiagMsg_Charger_Diag : 30|2@1+ (1,0) [0|3] ""  CHARGER_S,CHARGER_C,VCU
 SG_ bms0_DiagMsg_Charger_Control : 28|2@1+ (1,0) [0|3] ""  CHARGER_S,CHARGER_C,VCU
 SG_ bms0_stsBmsState : 4|4@1+ (1,0) [0|15] ""  CHARGER_S,CHARGER_C,BMS1,VCU
 SG_ bms0_stsChecksum_stsBMS : 56|8@1+ (1,0) [0|255] ""  CHARGER_C,VCU,BMS1
 SG_ bms0_stsAliveCnt_stsBMS : 52|4@1+ (1,0) [0|15] ""  CHARGER_C,VCU,BMS1
 SG_ bms0_stsPwrDFET : 12|2@1+ (1,0) [0|3] ""  CHARGER_S,CHARGER_C,VCU,BMS1
 SG_ bms0_stsPwrCFET : 10|2@1+ (1,0) [0|3] ""  CHARGER_S,CHARGER_C,VCU,BMS1
 SG_ bms0_stsPrechargeFET : 8|2@1+ (1,0) [0|3] ""  CHARGER_S,CHARGER_C,VCU,BMS1
 SG_ bms0_stsFullyCharged : 26|2@1+ (1,0) [0|3] ""  CHARGER_S,CHARGER_C,VCU,BMS1
 SG_ bms0_stsDiagInfo : 16|8@1+ (1,0) [0|255] ""  CHARGER_S,CHARGER_C,VCU,BMS1
 SG_ bms0_stsCurrentDirection : 14|2@1+ (1,0) [0|3] ""  CHARGER_S,CHARGER_C,VCU,BMS1
 SG_ bms0_stsIgnitionRecog : 24|2@1+ (1,0) [0|3] ""  CHARGER_S,CHARGER_C,VCU,BMS1
 SG_ bms0_stsBmsMode : 0|4@1+ (1,0) [0|15] ""  CHARGER_S,CHARGER_C,VCU,BMS1

BO_TX_BU_ 1281 : CHARGER_S,CHARGER_C;
BO_TX_BU_ 1283 : CHARGER_S,CHARGER_C;
CM_ BO_ 799 "FaultEntry ( 7~8 / 8 )";
CM_ SG_ 799 bms0_stsChecksum_FaultEntry2 "Checksum value for each message
CS = BITWISEXOR([0],[1])
CS = BITWISEXOR(CS,[2])
CS = BITWISEXOR(CS,[3])
CS = BITWISEXOR(CS,[4])
CS = BITWISEXOR(CS,[5])
CS = BITWISEXOR(CS,[6])
[7] = CS";
CM_ SG_ 799 bms0_stsAliveCnt_FaultEntry2 "Alive count valure to check stuck message
(Value will be increased as like 0->1->2->…->15->0->1->2… every single transmit.)";
CM_ SG_ 799 bms0_stsDiagFaultEntry8 "This signal will be presented diag. list ( 8/8 )";
CM_ SG_ 799 bms0_stsDiagFaultEntry7 "This signal will be presented diag. list ( 7/8 )";
CM_ BO_ 798 "FaultEntry ( 1~6 / 8 )";
CM_ SG_ 798 bms0_stsChecksum_FaultEntry1 "Checksum value for each message
CS = BITWISEXOR([0],[1])
CS = BITWISEXOR(CS,[2])
CS = BITWISEXOR(CS,[3])
CS = BITWISEXOR(CS,[4])
CS = BITWISEXOR(CS,[5])
CS = BITWISEXOR(CS,[6])
[7] = CS";
CM_ SG_ 798 bms0_stsAliveCnt_FaultEntry1 "Alive count valure to check stuck message
(Value will be increased as like 0->1->2->…->15->0->1->2… every single transmit.)";
CM_ SG_ 798 bms0_stsDiagFaultEntry6 "This signal will be presented diag. list ( 6/8 )";
CM_ SG_ 798 bms0_stsDiagFaultEntry5 "This signal will be presented diag. list ( 5/8 )";
CM_ SG_ 798 bms0_stsDiagFaultEntry4 "This signal will be presented diag. list ( 4/8 )";
CM_ SG_ 798 bms0_stsDiagFaultEntry3 "This signal will be presented diag. list ( 3/8 )";
CM_ SG_ 798 bms0_stsDiagFaultEntry2 "This signal will be presented diag. list ( 2/8 )";
CM_ SG_ 798 bms0_stsDiagFaultEntry1 "This signal will be presented diag. list ( 1/8 )";
CM_ BO_ 780 "Test Command";
CM_ SG_ 780 vfVCU_TestCmdChecksumOnOff_32F "Checksum On/Off Control : 0x32F";
CM_ SG_ 780 vfVCU_TestCmdChecksumOnOff_32E "Checksum On/Off Control : 0x32E";
CM_ SG_ 780 vfVCU_TestCmdChecksumOnOff_32A "Checksum On/Off Control : 0x32A";
CM_ SG_ 780 vfVCU_TestCmdChecksumOnOff_329 "Checksum On/Off Control : 0x329";
CM_ SG_ 780 vfVCU_TestCmdChecksumOnOff_328 "Checksum On/Off Control : 0x328";
CM_ SG_ 780 vfVCU_TestCmdChecksumOnOff_326 "Checksum On/Off Control : 0x326";
CM_ SG_ 780 vfVCU_TestCmdChecksumOnOff_324 "Checksum On/Off Control : 0x324";
CM_ SG_ 780 vfVCU_TestCmdChecksumOnOff_323 "Checksum On/Off Control : 0x323";
CM_ SG_ 780 vfVCU_TestCmdChecksumOnOff_322 "Checksum On/Off Control : 0x322";
CM_ SG_ 780 vfVCU_TestCmdChecksumOnOff_321 "Checksum On/Off Control : 0x321";
CM_ SG_ 780 vfVCU_TestCmdChecksumOnOff_320 "Checksum On/Off Control : 0x320";
CM_ SG_ 780 vfVCU_TestCmdChecksumOnOff_31F "Checksum On/Off Control : 0x31F";
CM_ SG_ 780 vfVCU_TestCmdChecksumOnOff_31E "Checksum On/Off Control : 0x31E";
CM_ SG_ 780 vfVCU_TestCmdChecksumOnOff_31A "Checksum On/Off Control : 0x31A";
CM_ SG_ 780 vfVCU_TestCmdChecksumOnOff_319 "Checksum On/Off Control : 0x319";
CM_ SG_ 780 vfVCU_TestCmdChecksumOnOff_318 "Checksum On/Off Control : 0x318";
CM_ SG_ 780 vfVCU_TestCmdChecksumOnOff_316 "Checksum On/Off Control : 0x316";
CM_ SG_ 780 vfVCU_TestCmdChecksumOnOff_314 "Checksum On/Off Control : 0x314";
CM_ SG_ 780 vfVCU_TestCmdChecksumOnOff_313 "Checksum On/Off Control : 0x313";
CM_ SG_ 780 vfVCU_TestCmdChecksumOnOff_312 "Checksum On/Off Control : 0x312";
CM_ SG_ 780 vfVCU_TestCmdChecksumOnOff_311 "Checksum On/Off Control : 0x311";
CM_ SG_ 780 vfVCU_TestCmdChecksumOnOff_310 "Checksum On/Off Control : 0x310";
CM_ SG_ 780 vfVCU_TestCmdAliveCntOnOff_32F "AliveCnt On/Off Control : 0x32F";
CM_ SG_ 780 vfVCU_TestCmdAliveCntOnOff_32E "AliveCnt On/Off Control : 0x32E";
CM_ SG_ 780 vfVCU_TestCmdAliveCntOnOff_32A "AliveCnt On/Off Control : 0x32A";
CM_ SG_ 780 vfVCU_TestCmdAliveCntOnOff_329 "AliveCnt On/Off Control : 0x329";
CM_ SG_ 780 vfVCU_TestCmdAliveCntOnOff_328 "AliveCnt On/Off Control : 0x328";
CM_ SG_ 780 vfVCU_TestCmdAliveCntOnOff_326 "AliveCnt On/Off Control : 0x326";
CM_ SG_ 780 vfVCU_TestCmdAliveCntOnOff_324 "AliveCnt On/Off Control : 0x324";
CM_ SG_ 780 vfVCU_TestCmdAliveCntOnOff_323 "AliveCnt On/Off Control : 0x323";
CM_ SG_ 780 vfVCU_TestCmdAliveCntOnOff_322 "AliveCnt On/Off Control : 0x322";
CM_ SG_ 780 vfVCU_TestCmdAliveCntOnOff_321 "AliveCnt On/Off Control : 0x321";
CM_ SG_ 780 vfVCU_TestCmdAliveCntOnOff_320 "AliveCnt On/Off Control : 0x320";
CM_ SG_ 780 vfVCU_TestCmdAliveCntOnOff_31F "AliveCnt On/Off Control : 0x31F";
CM_ SG_ 780 vfVCU_TestCmdAliveCntOnOff_31E "AliveCnt On/Off Control : 0x31E";
CM_ SG_ 780 vfVCU_TestCmdAliveCntOnOff_31A "AliveCnt On/Off Control : 0x31A";
CM_ SG_ 780 vfVCU_TestCmdAliveCntOnOff_319 "AliveCnt On/Off Control : 0x319";
CM_ SG_ 780 vfVCU_TestCmdAliveCntOnOff_318 "AliveCnt On/Off Control : 0x318";
CM_ SG_ 780 vfVCU_TestCmdAliveCntOnOff_316 "AliveCnt On/Off Control : 0x316";
CM_ SG_ 780 vfVCU_TestCmdAliveCntOnOff_314 "AliveCnt On/Off Control : 0x314";
CM_ SG_ 780 vfVCU_TestCmdAliveCntOnOff_313 "AliveCnt On/Off Control : 0x313";
CM_ SG_ 780 vfVCU_TestCmdAliveCntOnOff_312 "AliveCnt On/Off Control : 0x312";
CM_ SG_ 780 vfVCU_TestCmdAliveCntOnOff_311 "AliveCnt On/Off Control : 0x311";
CM_ SG_ 780 vfVCU_TestCmdAliveCntOnOff_310 "AliveCnt On/Off Control : 0x310";
CM_ BO_ 809 "This message can be used by the VCU to control power.";
CM_ SG_ 809 bms1_stsChecksum_estSOPC10s "Checksum value for each message
CS = BITWISEXOR([0],[1])
CS = BITWISEXOR(CS,[2])
CS = BITWISEXOR(CS,[3])
CS = BITWISEXOR(CS,[4])
CS = BITWISEXOR(CS,[5])
CS = BITWISEXOR(CS,[6])
[7] = CS";
CM_ SG_ 809 bms1_stsAliveCnt_estSOPC10s "Alive count valure to check stuck message
(Value will be increased as like 0->1->2->…->15->0->1->2… every single transmit.)";
CM_ SG_ 809 bms1_estMaxChgPwr10s "System Available max charging power value.";
CM_ SG_ 809 bms1_estMaxChgCurrent10s "System Available max charging current value.";
CM_ BO_ 810 "This message can be used by the VCU to control power.";
CM_ SG_ 810 bms1_stsChecksum_estSOPD10s "Checksum value for each message
CS = BITWISEXOR([0],[1])
CS = BITWISEXOR(CS,[2])
CS = BITWISEXOR(CS,[3])
CS = BITWISEXOR(CS,[4])
CS = BITWISEXOR(CS,[5])
CS = BITWISEXOR(CS,[6])
[7] = CS";
CM_ SG_ 810 bms1_stsAliveCnt_estSOPD10s "Alive count valure to check stuck message
(Value will be increased as like 0->1->2->…->15->0->1->2… every single transmit.)";
CM_ SG_ 810 bms1_estMaxDsgPwr10s "System Available max discharging power value.";
CM_ SG_ 810 bms1_estMaxDsgCurrent10s "System Available max discharging current value.";
CM_ BO_ 793 "This message can be used by the VCU to control power.";
CM_ SG_ 793 bms0_stsChecksum_estSOPC10s "Checksum value for each message
CS = BITWISEXOR([0],[1])
CS = BITWISEXOR(CS,[2])
CS = BITWISEXOR(CS,[3])
CS = BITWISEXOR(CS,[4])
CS = BITWISEXOR(CS,[5])
CS = BITWISEXOR(CS,[6])
[7] = CS";
CM_ SG_ 793 bms0_stsAliveCnt_estSOPC10s "Alive count valure to check stuck message
(Value will be increased as like 0->1->2->…->15->0->1->2… every single transmit.)";
CM_ SG_ 793 bms0_estMaxChgPwr10s "System Available max charging power value.";
CM_ SG_ 793 bms0_estMaxChgCurrent10s "System Available max charging current value.";
CM_ BO_ 794 "This message can be used by the VCU to control power.";
CM_ SG_ 794 bms0_stsChecksum_estSOPD10s "Checksum value for each message
CS = BITWISEXOR([0],[1])
CS = BITWISEXOR(CS,[2])
CS = BITWISEXOR(CS,[3])
CS = BITWISEXOR(CS,[4])
CS = BITWISEXOR(CS,[5])
CS = BITWISEXOR(CS,[6])
[7] = CS";
CM_ SG_ 794 bms0_stsAliveCnt_estSOPD10s "Alive count valure to check stuck message
(Value will be increased as like 0->1->2->…->15->0->1->2… every single transmit.)";
CM_ SG_ 794 bms0_estMaxDsgPwr10s "System Available max discharging power value.";
CM_ SG_ 794 bms0_estMaxDsgCurrent10s "System Available max discharging current value.";
CM_ BO_ 806 "This message can be used by the VCU to control power.";
CM_ SG_ 806 bms1_stsChecksum_estSOPC5s "Checksum value for each message
CS = BITWISEXOR([0],[1])
CS = BITWISEXOR(CS,[2])
CS = BITWISEXOR(CS,[3])
CS = BITWISEXOR(CS,[4])
CS = BITWISEXOR(CS,[5])
CS = BITWISEXOR(CS,[6])
[7] = CS";
CM_ SG_ 806 bms1_stsAliveCnt_estSOPC5s "Alive count valure to check stuck message
(Value will be increased as like 0->1->2->…->15->0->1->2… every single transmit.)";
CM_ SG_ 806 bms1_estMaxChgPwr5s "System Available max charging power value.";
CM_ SG_ 806 bms1_estMaxChgCurrent5s "System Available max charging current value.";
CM_ BO_ 808 "This message can be used by the VCU to control power.";
CM_ SG_ 808 bms1_stsChecksum_estSOPD5s "Checksum value for each message
CS = BITWISEXOR([0],[1])
CS = BITWISEXOR(CS,[2])
CS = BITWISEXOR(CS,[3])
CS = BITWISEXOR(CS,[4])
CS = BITWISEXOR(CS,[5])
CS = BITWISEXOR(CS,[6])
[7] = CS";
CM_ SG_ 808 bms1_stsAliveCnt_estSOPD5s "Alive count valure to check stuck message
(Value will be increased as like 0->1->2->…->15->0->1->2… every single transmit.)";
CM_ SG_ 808 bms1_estMaxDsgPwr5s "System Available max discharging power value.";
CM_ SG_ 808 bms1_estMaxDsgCurrent5s "System Available max discharging current value.";
CM_ BO_ 790 "This message can be used by the VCU to control power.";
CM_ SG_ 790 bms0_stsChecksum_estSOPC5s "Checksum value for each message
CS = BITWISEXOR([0],[1])
CS = BITWISEXOR(CS,[2])
CS = BITWISEXOR(CS,[3])
CS = BITWISEXOR(CS,[4])
CS = BITWISEXOR(CS,[5])
CS = BITWISEXOR(CS,[6])
[7] = CS";
CM_ SG_ 790 bms0_stsAliveCnt_estSOPC5s "Alive count valure to check stuck message
(Value will be increased as like 0->1->2->…->15->0->1->2… every single transmit.)";
CM_ SG_ 790 bms0_estMaxChgPwr5s "System Available max charging power value.";
CM_ SG_ 790 bms0_estMaxChgCurrent5s "System Available max charging current value.";
CM_ BO_ 792 "This message can be used by the VCU to control power.";
CM_ SG_ 792 bms0_stsChecksum_estSOPD5s "Checksum value for each message
CS = BITWISEXOR([0],[1])
CS = BITWISEXOR(CS,[2])
CS = BITWISEXOR(CS,[3])
CS = BITWISEXOR(CS,[4])
CS = BITWISEXOR(CS,[5])
CS = BITWISEXOR(CS,[6])
[7] = CS";
CM_ SG_ 792 bms0_stsAliveCnt_estSOPD5s "Alive count valure to check stuck message
(Value will be increased as like 0->1->2->…->15->0->1->2… every single transmit.)";
CM_ SG_ 792 bms0_estMaxDsgPwr5s "System Available max discharging power value.";
CM_ SG_ 792 bms0_estMaxDsgCurrent5s "System Available max discharging current value.";
CM_ BO_ 813 "Version of battery pack or product information";
CM_ SG_ 813 bms1_verSoftwareSubminor "Version - application_subminor";
CM_ SG_ 813 bms1_verSoftwareMinor "Version - application_minor";
CM_ SG_ 813 bms1_verSoftwareMajor "Version - application_major";
CM_ SG_ 813 bms1_verHardwarePCB "Version - BMS HW";
CM_ SG_ 813 bms1_verHardwareSch "Version - bootloader";
CM_ SG_ 813 bms1_verBootloaderMajor "Version - bootloader";
CM_ SG_ 813 bms1_verMfgSerialNo "manufacturering serial number per day";
CM_ SG_ 813 bms1_verMfgDate "Manufactuering Date";
CM_ BO_ 811 "Pack life time mileage data";
CM_ SG_ 811 bms1_stsAccumMileage "Pack life time mileage data (ODO data)";
CM_ BO_ 805 "Cell voltage.";
CM_ SG_ 805 bms1_msrVoltageCellMinNo "minimum cell voltage number";
CM_ SG_ 805 bms1_msrVoltageCellMin "minimum cell voltage.";
CM_ SG_ 805 bms1_msrVoltageCellMaxNo "maximum cell voltage number";
CM_ SG_ 805 bms1_msrVoltageCellMax "maximum cell voltage.";
CM_ SG_ 805 bms1_msrVoltageCellAvg "Average cell voltage.";
CM_ BO_ 807 "Cell temperature inside the battery pack.";
CM_ SG_ 807 bms1_msrTempPreChgFet "Temperature - Precharge FET";
CM_ SG_ 807 bms1_msrTempFET2 "Temperature - Power FET Temperature";
CM_ SG_ 807 bms1_msrTempFET1 "Temperature - Power FET Temperature";
CM_ SG_ 807 bms1_msrTempCellMinNo "Minimum Temperature Number - cell.";
CM_ SG_ 807 bms1_msrTempCellMin "Minimum Temperature - cell.";
CM_ SG_ 807 bms1_msrTempCellMaxNo "Maximum Temperature Number - cell.";
CM_ SG_ 807 bms1_msrTempCellMax "Maximum Temperature - cell.";
CM_ SG_ 807 bms1_msrTempCellAvg "Average Temperature - cell.";
CM_ BO_ 802 "This message can be used by the VCU to control power.";
CM_ SG_ 802 bms1_stsChecksum_estSOPD2s "Checksum value for each message
CS = BITWISEXOR([0],[1])
CS = BITWISEXOR(CS,[2])
CS = BITWISEXOR(CS,[3])
CS = BITWISEXOR(CS,[4])
CS = BITWISEXOR(CS,[5])
CS = BITWISEXOR(CS,[6])
[7] = CS";
CM_ SG_ 802 bms1_stsAliveCnt_estSOPD2s "Alive count valure to check stuck message
(Value will be increased as like 0->1->2->…->15->0->1->2… every single transmit.)";
CM_ SG_ 802 bms1_estMaxDsgPwr2s "System Available max discharging power value.";
CM_ SG_ 802 bms1_estMaxDsgCurrent2s "System Available max discharging current value.";
CM_ BO_ 803 "This message can be used by the VCU to control power.";
CM_ SG_ 803 bms1_stsChecksum_estSOPC2s "Checksum value for each message
CS = BITWISEXOR([0],[1])
CS = BITWISEXOR(CS,[2])
CS = BITWISEXOR(CS,[3])
CS = BITWISEXOR(CS,[4])
CS = BITWISEXOR(CS,[5])
CS = BITWISEXOR(CS,[6])
[7] = CS";
CM_ SG_ 803 bms1_stsAliveCnt_estSOPC2s "Alive count valure to check stuck message
(Value will be increased as like 0->1->2->…->15->0->1->2… every single transmit.)";
CM_ SG_ 803 bms1_estMaxChgPwr2s "System Available max charging power value.";
CM_ SG_ 803 bms1_estMaxChgCurrent2s "System Available max charging current value.";
CM_ BO_ 832 "Operating state of the cell balancing circuit of the battery pack.";
CM_ SG_ 832 bms1_devStsCB14 "Status of cell balancing circuit.";
CM_ SG_ 832 bms1_devStsCB13 "Status of cell balancing circuit.";
CM_ SG_ 832 bms1_devStsCB12 "Status of cell balancing circuit.";
CM_ SG_ 832 bms1_devStsCB11 "Status of cell balancing circuit.";
CM_ SG_ 832 bms1_devStsCB10 "Status of cell balancing circuit.";
CM_ SG_ 832 bms1_devStsCB09 "Status of cell balancing circuit.";
CM_ SG_ 832 bms1_devStsCB08 "Status of cell balancing circuit.";
CM_ SG_ 832 bms1_devStsCB07 "Status of cell balancing circuit.";
CM_ SG_ 832 bms1_devStsCB06 "Status of cell balancing circuit.";
CM_ SG_ 832 bms1_devStsCB05 "Status of cell balancing circuit.";
CM_ SG_ 832 bms1_devStsCB04 "Status of cell balancing circuit.";
CM_ SG_ 832 bms1_devStsCB03 "Status of cell balancing circuit.";
CM_ SG_ 832 bms1_devStsCB02 "Status of cell balancing circuit.";
CM_ SG_ 832 bms1_devStsCB01 "Status of cell balancing circuit.";
CM_ BO_ 838 "Temperature of the components in the battery pack.";
CM_ SG_ 838 bms1_devCbOnCnt "cell voltage.";
CM_ SG_ 838 bms1_devTopCellOffset "cell voltage.";
CM_ SG_ 838 bms1_devVoltageCellDiff "cell voltage.";
CM_ SG_ 838 bms1_devMsrTempCB1 "Temperature - cell balancing circuit.";
CM_ BO_ 837 "Diagnostic information of the Pack.";
CM_ SG_ 837 bms1_devDiagCntRam "DiagRamCnt";
CM_ SG_ 837 bms1_devDiagCntMCU "DiagMcu Cnt";
CM_ SG_ 837 bms1_devResetCntByVCU "ResetCntByVCU - VCU_Status(vfVCU_ResetBMS1)";
CM_ SG_ 837 bms1_devDiagCntPackFuseR "Diagnosis - Pack Fuse Resistance Current Occurred Count";
CM_ SG_ 837 bms1_devDiagCntPackFuseOC "Diagnosis - Pack Fuse Over Current Occurred Count. If count reach to maximum value, it is sustained, no overflow.";
CM_ SG_ 837 bms1_devDiagCntPackFuseBlow "Diagnosis - Pack Fuse Blow Occurred Count. If count reach to maximum value, it is sustained, no overflow.";
CM_ SG_ 837 bms1_devDiagCntPackFETTemp "Diagnosis - Pack FET Temperature(Over) Occurred Count. If count reach to maximum value, it is sustained, no overflow.";
CM_ BO_ 836 "Diagnostic information of the Cell.";
CM_ SG_ 836 bms1_devDiagCntCellUVPack "Diagnosis - Under voltage Pack Fault Count. If count reach to maximum value, it is sustained, no overflow.";
CM_ SG_ 836 bms1_devDiagCntCellUV "Diagnosis - Under voltage Cell Fault Count. If count reach to maximum value, it is sustained, no overflow.";
CM_ SG_ 836 bms1_devDiagCntCellUDT "Diagnosis - Under temperature in discharging Fault Count. If count reach to maximum value, it is sustained, no overflow.";
CM_ SG_ 836 bms1_devDiagCntCellUCT "Diagnosis - Under temperature in charging Fault Count. If count reach to maximum value, it is sustained, no overflow.";
CM_ SG_ 836 bms1_devDiagCntCellOV "Diagnosis - Over voltage Cell Fault Count. If count reach to maximum value, it is sustained, no overflow.";
CM_ SG_ 836 bms1_devDiagCntCellODT "Diagnosis - Over temperature in discharging Fault Count. If count reach to maximum value, it is sustained, no overflow.";
CM_ BO_ 835 "Diagnostic information of the Cell.";
CM_ SG_ 835 bms1_devDiagCntCellOCT "Diagnosis - Over temperature in charging Fault Count. If count reaches maximum value, it is sustained, no overflow.";
CM_ SG_ 835 bms1_devDiagCntCellOCD "Diagnosis - Over discharge current Fault Count. If count reach to maximum value, it is sustained, no overflow.";
CM_ SG_ 835 bms1_devDiagCntCellOCC "Diagnosis - Over charge current Fault Count. If count reach to maximum value, it is sustained, no overflow.";
CM_ SG_ 835 bms1_devDiagCntCellImbTemp "Diagnosis - Cell Temperature imbalance Fault Count. If count reach to maximum value, it is sustained, no overflow.";
CM_ SG_ 835 bms1_devDiagCntCellImbSOC "Diagnosis - Cell SOC imbalance Fault Count. If count reach to maximum value, it is sustained, no overflow. ";
CM_ SG_ 835 bms1_devDiagCntCellImbChg "Diagnosis - Cell voltage imbalance in Charging Fault Count. If count reach to maximum value, it is sustained, no overflow.";
CM_ SG_ 835 bms1_devDiagCntCellImbCellRest "Diagnosis - Cell voltage imbalance in Rest Fault Count. If count reach to maximum value, it is sustained, no overflow.";
CM_ SG_ 835 bms1_devDiagCntCellAgvOV "Diagnosis - Over voltage Pack Fault Count. If count reach to maximum value, it is sustained, no overflow.";
CM_ BO_ 834 "Diagnostic information of the BMS.";
CM_ SG_ 834 bms1_devDiagCntBmsShortIC "Diagnosis - BMS ShortIC Occurred Count. If count reach to maximum value, it is sustained, no overflow.";
CM_ SG_ 834 bms1_devDiagCntBmsPFET_Tiemout "Diagnosis - BMS PFET2 Occurred Count. If count reach to maximum value, it is sustained, no overflow.";
CM_ SG_ 834 bms1_devDiagCntBmsPFET_OT "Diagnosis - BMS PFET Occurred Count. If count reach to maximum value, it is sustained, no overflow.";
CM_ SG_ 834 bms1_devDiagCntBmsDFET "Diagnosis - BMS DFET Occurred Count. If count reach to maximum value, it is sustained, no overflow.";
CM_ SG_ 834 bms1_devDiagCntBmsCFET "Diagnosis - BMS CFET  Occurred Count. If count reach to maximum value, it is sustained, no overflow.";
CM_ SG_ 834 bms1_devDiagCntBmsAsicShutdown "Diagnosis - BMS ASIC Shutdown Occurred Count. If count reach to maximum value, it is sustained, no overflow.";
CM_ SG_ 834 bms1_devDiagCntBmsAsicCommLoss "Diagnosis - BMS ASIC Comm Occurred Count. If count reach to maximum value, it is sustained, no overflow.
(otherwise, this counter will be clear when BMS communicate with Asic well.)";
CM_ BO_ 833 "Diagnostic information of the Aisc.";
CM_ SG_ 833 bms1_devChecksum "File Checksum";
CM_ SG_ 833 bms1_devDiagCntAsicXReady "Diagnosis - Asic Device X Ready Occurred Count";
CM_ SG_ 833 bms1_devDiagCntAsicUV "Diagnosis - Asic Under Voltage Occurred Count. If count reach to maximum value, it is sustained, no overflow.";
CM_ SG_ 833 bms1_devDiagCntAsicShort "Diagnosis - Asic Short Current Occured Count. If count reach to maximum value, it is sustained, no overflow.";
CM_ SG_ 833 bms1_devDiagCntAsicOverride "Diagnosis - Asic Over Ride Occurred Count. If count reach to maximum value, it is sustained, no overflow.";
CM_ SG_ 833 bms1_devDiagCntAsicOV "Diagnosis - Asic Over Voltage Occurred Count. If count reach to maximum value, it is sustained, no overflow.";
CM_ SG_ 833 bms1_devDiagCntAsicOCD "Diagnosis - Asic Discharge Over Current Occurred Count. If count reach to maximum value, it is sustained, no overflow.";
CM_ BO_ 843 "Cell voltage inside the battery pack.";
CM_ SG_ 843 bms1_devVoltageCell14 "maximum cell voltage.";
CM_ SG_ 843 bms1_devVoltageCell13 "maximum cell voltage.";
CM_ BO_ 842 "Cell voltage inside the battery pack.";
CM_ SG_ 842 bms1_devVoltageCell12 "maximum cell voltage.";
CM_ SG_ 842 bms1_devVoltageCell11 "maximum cell voltage.";
CM_ SG_ 842 bms1_devVoltageCell10 "maximum cell voltage.";
CM_ SG_ 842 bms1_devVoltageCell09 "maximum cell voltage.";
CM_ BO_ 841 "Cell voltage inside the battery pack.";
CM_ SG_ 841 bms1_devVoltageCell08 "maximum cell voltage.";
CM_ SG_ 841 bms1_devVoltageCell07 "maximum cell voltage.";
CM_ SG_ 841 bms1_devVoltageCell06 "maximum cell voltage.";
CM_ SG_ 841 bms1_devVoltageCell05 "maximum cell voltage.";
CM_ BO_ 840 "Cell temperature inside the battery pack.";
CM_ SG_ 840 bms1_devVoltageCell04 "maximum cell voltage.";
CM_ SG_ 840 bms1_devVoltageCell03 "maximum cell voltage.";
CM_ SG_ 840 bms1_devVoltageCell02 "maximum cell voltage.";
CM_ SG_ 840 bms1_devVoltageCell01 "maximum cell voltage.";
CM_ BO_ 827 "Cell temperature inside the battery pack.";
CM_ SG_ 827 bms0_devVoltageCell14 "cell voltage.";
CM_ SG_ 827 bms0_devVoltageCell13 "cell voltage.";
CM_ BO_ 826 "Cell temperature inside the battery pack.";
CM_ SG_ 826 bms0_devVoltageCell12 "cell voltage.";
CM_ SG_ 826 bms0_devVoltageCell11 "cell voltage.";
CM_ SG_ 826 bms0_devVoltageCell10 "cell voltage.";
CM_ SG_ 826 bms0_devVoltageCell09 "cell voltage.";
CM_ BO_ 824 "Cell voltage inside the battery pack.";
CM_ SG_ 824 bms0_devVoltageCell04 "cell voltage.";
CM_ SG_ 824 bms0_devVoltageCell03 "cell voltage.";
CM_ SG_ 824 bms0_devVoltageCell02 "cell voltage.";
CM_ SG_ 824 bms0_devVoltageCell01 "cell voltage.";
CM_ BO_ 825 "Cell voltage inside the battery pack.";
CM_ SG_ 825 bms0_devVoltageCell08 "cell voltage.";
CM_ SG_ 825 bms0_devVoltageCell07 "cell voltage.";
CM_ SG_ 825 bms0_devVoltageCell06 "cell voltage.";
CM_ SG_ 825 bms0_devVoltageCell05 "cell voltage.";
CM_ BO_ 781 "This tool can be communicated with BMS0 only.";
CM_ SG_ 781 reflash_ReqSubIndex_bms "Boot and Manufactuer Signal of LGC BMS";
CM_ SG_ 781 reflash_ReqIndex_bms "Boot and Manufactuer Signal of LGC BMS";
CM_ SG_ 781 reflash_ReqData5_bms "Boot and Manufactuer Signal of LGC BMS";
CM_ SG_ 781 reflash_ReqData4_bms "Boot and Manufactuer Signal of LGC BMS";
CM_ SG_ 781 reflash_ReqData3_bms "Boot and Manufactuer Signal of LGC BMS";
CM_ SG_ 781 reflash_ReqData2_bms "Boot and Manufactuer Signal of LGC BMS";
CM_ SG_ 781 reflash_ReqData1_bms "Boot and Manufactuer Signal of LGC BMS";
CM_ BO_ 797 "Version of battery pack or product information";
CM_ SG_ 797 bms0_verHardwarePCB "Version - bootloader";
CM_ SG_ 797 bms0_verMfgSerialNo "manufacturering serial number per day";
CM_ SG_ 797 bms0_verMfgDate "Manufactuering Date";
CM_ SG_ 797 bms0_verHardwareSch "Version - BMS HW";
CM_ SG_ 797 bms0_verSoftwareMajor "Version - application_major";
CM_ SG_ 797 bms0_verBootloader "Version - bootloader";
CM_ SG_ 797 bms0_verSoftwareSubminor "Version - application_subminor";
CM_ SG_ 797 bms0_verSoftwareMinor "Version - application_minor";
CM_ BO_ 796 "Status of Chariging status";
CM_ SG_ 796 bms0_ctrlChargerLimitCurrent "Current limitation value for charging (in case of fault, this value will be zero)";
CM_ SG_ 796 bms0_ctrlChargerLimitVoltage "Voltage limitation value for charging (in case of fault, this value will be zero)";
CM_ SG_ 796 bms0_ctrlChargerTimeToFull "Remaining Charging Time";
CM_ BO_ 817 "Diagnostic information of the Aisc.";
CM_ SG_ 817 bms0_devChecksum "File Checksum";
CM_ SG_ 817 bms0_devDiagCntAsicOverride "Diagnosis - Asic Over Ride Occurred Count. If count reach to maximum value, it is sustained, no overflow.";
CM_ SG_ 817 bms0_devDiagCntAsicShort "Diagnosis - Asic Short Current Occured Count. If count reach to maximum value, it is sustained, no overflow.";
CM_ SG_ 817 bms0_devDiagCntAsicOCD "Diagnosis - Asic Discharge Over Current Occurred Count. If count reach to maximum value, it is sustained, no overflow.";
CM_ SG_ 817 bms0_devDiagCntAsicUV "Diagnosis - Asic Under Voltage Occurred Count. If count reach to maximum value, it is sustained, no overflow.";
CM_ SG_ 817 bms0_devDiagCntAsicOV "Diagnosis - Asic Over Voltage Occurred Count. If count reach to maximum value, it is sustained, no overflow.";
CM_ SG_ 817 bms0_devDiagCntAsicXReady "Diagnosis - Asic Device X Ready Occurred Count";
CM_ BO_ 818 "Diagnostic information of the BMS.";
CM_ SG_ 818 bms0_devDiagCntBmsShortIC "Diagnosis - BMS ShortIC Occurred Count. If count reach to maximum value, it is sustained, no overflow.";
CM_ SG_ 818 bms0_devDiagCntBmsPFET_Timeout "Diagnosis - BMS PFET2 Occurred Count. If count reach to maximum value, it is sustained, no overflow.";
CM_ SG_ 818 bms0_devDiagCntBmsAsicShutdown "Diagnosis - BMS ASIC Shutdown Occurred Count. If count reach to maximum value, it is sustained, no overflow.";
CM_ SG_ 818 bms0_devDiagCntBmsAsicCommLoss "Diagnosis - BMS ASIC Comm Occurred Count. If count reach to maximum value, it is sustained, no overflow.
(otherwise, this counter will be clear when BMS communicate with Asic well.)";
CM_ SG_ 818 bms0_devDiagCntBmsPFET_OT "Diagnosis - BMS PFET Occurred Count. If count reach to maximum value, it is sustained, no overflow.";
CM_ SG_ 818 bms0_devDiagCntBmsDFET "Diagnosis - BMS DFET Occurred Count. If count reach to maximum value, it is sustained, no overflow.";
CM_ SG_ 818 bms0_devDiagCntBmsCFET "Diagnosis - BMS CFET  Occurred Count. If count reach to maximum value, it is sustained, no overflow.";
CM_ BO_ 819 "Diagnostic information of the Cell.";
CM_ SG_ 819 bms0_devDiagCntCellImbTemp "Diagnosis - Cell Temperature imbalance Fault Count. If count reach to maximum value, it is sustained, no overflow.";
CM_ SG_ 819 bms0_devDiagCntCellImbSOC "Diagnosis - Cell SOC imbalance Fault Count. If count reach to maximum value, it is sustained, no overflow. ";
CM_ SG_ 819 bms0_devDiagCntCellImbChg "Diagnosis - Cell voltage imbalance in Charging Fault Count. If count reach to maximum value, it is sustained, no overflow.";
CM_ SG_ 819 bms0_devDiagCntCellImbCellRest "Diagnosis - Cell voltage imbalance in Rest Fault Count. If count reach to maximum value, it is sustained, no overflow.";
CM_ SG_ 819 bms0_devDiagCntCellAgvOV "Diagnosis - Over voltage Pack Fault Count. If count reach to maximum value, it is sustained, no overflow.";
CM_ SG_ 819 bms0_devDiagCntCellOCT "Diagnosis - Over temperature in charging Fault Count. If count reaches maximum value, it is sustained, no overflow.";
CM_ SG_ 819 bms0_devDiagCntCellOCD "Diagnosis - Over discharge current Fault Count. If count reach to maximum value, it is sustained, no overflow.";
CM_ SG_ 819 bms0_devDiagCntCellOCC "Diagnosis - Over charge current Fault Count. If count reach to maximum value, it is sustained, no overflow.";
CM_ BO_ 820 "Diagnostic information of the Cell.";
CM_ SG_ 820 bms0_devDiagCntCellUV "Diagnosis - Under voltage Cell Fault Count. If count reach to maximum value, it is sustained, no overflow.";
CM_ SG_ 820 bms0_devDiagCntCellUDT "Diagnosis - Under temperature in discharging Fault Count. If count reach to maximum value, it is sustained, no overflow.";
CM_ SG_ 820 bms0_devDiagCntCellUCT "Diagnosis - Under temperature in charging Fault Count. If count reach to maximum value, it is sustained, no overflow.";
CM_ SG_ 820 bms0_devDiagCntCellOV "Diagnosis - Over voltage Cell Fault Count. If count reach to maximum value, it is sustained, no overflow.";
CM_ SG_ 820 bms0_devDiagCntCellODT "Diagnosis - Over temperature in discharging Fault Count. If count reach to maximum value, it is sustained, no overflow.";
CM_ SG_ 820 bms0_devDiagCntCellUVPack "Diagnosis - Under voltage Pack Fault Count. If count reach to maximum value, it is sustained, no overflow.";
CM_ BO_ 821 "Diagnostic information of the Pack.";
CM_ SG_ 821 bms0_devDiagCntRam "DiagRamCnt";
CM_ SG_ 821 bms0_devDiagCntMCU "DiagMcu Cnt";
CM_ SG_ 821 bms0_devResetCntByVCU "ResetCntByVCU - VCU_Status(vfVCU_ResetBMS0)";
CM_ SG_ 821 bms0_devDiagCntPackFETTemp "Diagnosis - Pack FET Temperature(Over) Occurred Count. If count reach to maximum value, it is sustained, no overflow.";
CM_ SG_ 821 bms0_devDiagCntPackFuseOC "Diagnosis - Pack Fuse Over Current Occurred Count. If count reach to maximum value, it is sustained, no overflow.";
CM_ SG_ 821 bms0_devDiagCntPackFuseR "Diagnosis - Pack Fuse Resistance Current Occurred Count";
CM_ SG_ 821 bms0_devDiagCntPackFuseBlow "Diagnosis - Pack Fuse Blow Occurred Count. If count reach to maximum value, it is sustained, no overflow.";
CM_ BO_ 822 "Temperature of the components in the battery pack.";
CM_ SG_ 822 bms0_devStsPowertrain "cell voltage.";
CM_ SG_ 822 bms0_devI2C400kHzNack "Status of cell balancing circuit.";
CM_ SG_ 822 bms0_devLedBlink "LED status";
CM_ SG_ 822 bms0_devCbOnCnt "cell voltage.";
CM_ SG_ 822 bms0_devTopCellOffset "cell voltage.";
CM_ SG_ 822 bms0_devVoltageCellDiff "cell voltage.";
CM_ SG_ 822 bms0_devMsrTempCB1 "Temperature - cell balancing circuit.";
CM_ BO_ 816 "Operating state of the cell balancing circuit of the battery pack.";
CM_ SG_ 816 bms0_devStsCB08 "Status of cell balancing circuit.";
CM_ SG_ 816 bms0_devStsCB07 "Status of cell balancing circuit.";
CM_ SG_ 816 bms0_devStsCB06 "Status of cell balancing circuit.";
CM_ SG_ 816 bms0_devStsCB05 "Status of cell balancing circuit.";
CM_ SG_ 816 bms0_devStsCB04 "Status of cell balancing circuit.";
CM_ SG_ 816 bms0_devStsCB03 "Status of cell balancing circuit.";
CM_ SG_ 816 bms0_devStsCB02 "Status of cell balancing circuit.";
CM_ SG_ 816 bms0_devStsCB01 "Status of cell balancing circuit.";
CM_ SG_ 816 bms0_devStsCB09 "Status of cell balancing circuit.";
CM_ SG_ 816 bms0_devStsCB10 "Status of cell balancing circuit.";
CM_ SG_ 816 bms0_devStsCB11 "Status of cell balancing circuit.";
CM_ SG_ 816 bms0_devStsCB12 "Status of cell balancing circuit.";
CM_ SG_ 816 bms0_devStsCB13 "Status of cell balancing circuit.";
CM_ SG_ 816 bms0_devStsCB14 "Status of cell balancing circuit.";
CM_ BO_ 788 "SOH, RSOC, Cycle count, ... of battery pack.";
CM_ SG_ 788 bms0_estCycleCnt "Cycle Count";
CM_ SG_ 788 bms0_estSOH "State of health.";
CM_ SG_ 788 bms0_estRSOC "Relative State Of Charge.";
CM_ SG_ 788 bms0_stsAliveCnt_estSOC "Alive count valure to check stuck message";
CM_ SG_ 788 bms0_stsChecksum_estSOC "Checksum value for each message
CS = BITWISEXOR([0],[1])
CS = BITWISEXOR(CS,[2])
CS = BITWISEXOR(CS,[3])
CS = BITWISEXOR(CS,[4])
CS = BITWISEXOR(CS,[5])
CS = BITWISEXOR(CS,[6])
[7] = CS";
CM_ BO_ 787 "This message can be used by the VCU to control power.";
CM_ SG_ 787 bms0_estMaxChgPwr2s "System Available max charging power value.";
CM_ SG_ 787 bms0_estMaxChgCurrent2s "System Available max charging current value.";
CM_ SG_ 787 bms0_stsAliveCnt_estSOPC2s "Alive count valure to check stuck message
(Value will be increased as like 0->1->2->…->15->0->1->2… every single transmit.)";
CM_ SG_ 787 bms0_stsChecksum_estSOPC2s "Checksum value for each message
CS = BITWISEXOR([0],[1])
CS = BITWISEXOR(CS,[2])
CS = BITWISEXOR(CS,[3])
CS = BITWISEXOR(CS,[4])
CS = BITWISEXOR(CS,[5])
CS = BITWISEXOR(CS,[6])
[7] = CS";
CM_ BO_ 785 "Status of battery pack.";
CM_ SG_ 785 bms0_msrVoltagePackTerminal "voltage of battery terminal (p+,p-)";
CM_ SG_ 785 bms0_msrCurrentPack "Measuring pack current,  charging is positive, discharging is negative.";
CM_ SG_ 785 bms0_msrVoltagePack "Sum of all series cell voltage.";
CM_ SG_ 785 bms0_stsAliveCnt_msrPack "Alive count valure to check stuck message
(Value will be increased as like 0->1->2->…->15->0->1->2… every single transmit.)";
CM_ SG_ 785 bms0_stsChecksum_msrPack "Checksum value for each message
CS = BITWISEXOR([0],[1])
CS = BITWISEXOR(CS,[2])
CS = BITWISEXOR(CS,[3])
CS = BITWISEXOR(CS,[4])
CS = BITWISEXOR(CS,[5])
CS = BITWISEXOR(CS,[6])
[7] = CS";
CM_ BO_ 791 "Cell temperature inside the battery pack.";
CM_ SG_ 791 bms0_msrTempPreChgFet "Temperature - Precharge FET";
CM_ SG_ 791 bms0_msrTempFET2 "Temperature - Power FET Temperature";
CM_ SG_ 791 bms0_msrTempFET1 "Temperature - Power FET Temperature";
CM_ SG_ 791 bms0_msrTempCellMaxNo "Maximum Temperature Number - cell.";
CM_ SG_ 791 bms0_msrTempCellMax "Maximum Temperature - cell.";
CM_ SG_ 791 bms0_msrTempCellMinNo "Minimum Temperature Number - cell.";
CM_ SG_ 791 bms0_msrTempCellMin "Minimum Temperature - cell.";
CM_ SG_ 791 bms0_msrTempCellAvg "Average Temperature - cell.";
CM_ BO_ 789 "Cell voltage.";
CM_ SG_ 789 bms0_msrVoltageCellMaxNo "maximum cell voltage number";
CM_ SG_ 789 bms0_msrVoltageCellMax "maximum cell voltage.";
CM_ SG_ 789 bms0_msrVoltageCellMinNo "minimum cell voltage number";
CM_ SG_ 789 bms0_msrVoltageCellMin "minimum cell voltage.";
CM_ SG_ 789 bms0_msrVoltageCellAvg "Average cell voltage.";
CM_ BO_ 795 "Pack life time mileage data";
CM_ SG_ 795 bms0_stsAccumMileage "Pack life time mileage data (ODO data)";
CM_ BO_ 786 "This message can be used by the VCU to control power.";
CM_ SG_ 786 bms0_stsChecksum_estSOPD2s "Checksum value for each message
CS = BITWISEXOR([0],[1])
CS = BITWISEXOR(CS,[2])
CS = BITWISEXOR(CS,[3])
CS = BITWISEXOR(CS,[4])
CS = BITWISEXOR(CS,[5])
CS = BITWISEXOR(CS,[6])
[7] = CS";
CM_ SG_ 786 bms0_stsAliveCnt_estSOPD2s "Alive count valure to check stuck message
(Value will be increased as like 0->1->2->…->15->0->1->2… every single transmit.)";
CM_ SG_ 786 bms0_estMaxDsgCurrent2s "System Available max discharging current value.";
CM_ SG_ 786 bms0_estMaxDsgPwr2s "System Available max discharging power value.";
CM_ BO_ 1281 "This message can be used to dock type charger. (NOT for the vehicle charger)";
CM_ SG_ 1281 charger_stsChecksum_501 "Checksum value for each message
CS = BITWISEXOR([0],[1])
CS = BITWISEXOR(CS,[2])
CS = BITWISEXOR(CS,[3])
CS = BITWISEXOR(CS,[4])
CS = BITWISEXOR(CS,[5])
CS = BITWISEXOR(CS,[6])
[7] = CS";
CM_ SG_ 1281 charger_stsAliveCnt_501 "Alive count valure to check stuck message
(Value will be increased as like 0->1->2->…->15->0->1->2… every single transmit.)";
CM_ BO_ 1282 "This message can be used to dock type charger. (NOT for the vehicle charger)";
CM_ SG_ 1282 charger_stsChecksum_502 "Checksum value for each message
CS = BITWISEXOR([0],[1])
CS = BITWISEXOR(CS,[2])
CS = BITWISEXOR(CS,[3])
CS = BITWISEXOR(CS,[4])
CS = BITWISEXOR(CS,[5])
CS = BITWISEXOR(CS,[6])
[7] = CS";
CM_ SG_ 1282 charger_stsAliveCnt_502 "Alive count valure to check stuck message
(Value will be increased as like 0->1->2->…->15->0->1->2… every single transmit.)";
CM_ SG_ 1282 charger_wakeupBMS0 "BMS0 wake up";
CM_ SG_ 1282 charger_verChargerType "Define charger type:";
CM_ SG_ 1282 charger_commrequiredBMS0 "This signal will be used chaging dock. (NOT for the vehicle charger)";
CM_ BO_ 1283 "This message can be used to dock type charger. (NOT for the vehicle charger)";
CM_ SG_ 1283 charger_stsChecksum_503 "Checksum value for each message
CS = BITWISEXOR([0],[1])
CS = BITWISEXOR(CS,[2])
CS = BITWISEXOR(CS,[3])
CS = BITWISEXOR(CS,[4])
CS = BITWISEXOR(CS,[5])
CS = BITWISEXOR(CS,[6])
[7] = CS";
CM_ SG_ 1283 charger_stsAliveCnt_503 "Alive count valure to check stuck message
(Value will be increased as like 0->1->2->…->15->0->1->2… every single transmit.)";
CM_ BO_ 783 "This tool can be communicated with BMS0 only.";
CM_ SG_ 783 reflash_ReqIndex_FRP "Boot and Manufactuer Signal of LGC BMS";
CM_ SG_ 783 reflash_ReqSubIndex_FRP "Boot and Manufactuer Signal of LGC BMS";
CM_ SG_ 783 reflash_ReqData1_FRP "Boot and Manufactuer Signal of LGC BMS";
CM_ SG_ 783 reflash_ReqData2_FRP "Boot and Manufactuer Signal of LGC BMS";
CM_ SG_ 783 reflash_ReqData3_FRP "Boot and Manufactuer Signal of LGC BMS";
CM_ SG_ 783 reflash_ReqData4_FRP "Boot and Manufactuer Signal of LGC BMS";
CM_ SG_ 783 reflash_ReqData5_FRP "Boot and Manufactuer Signal of LGC BMS";
CM_ BO_ 784 "Status of BMS.";
CM_ SG_ 784 bms0_stsAbnormalChargerCtrl "abnormal Charger current. > (limitcurrent * 1.1)";
CM_ SG_ 784 bms0_stsLowSoheAlarm "low SOH Alarm";
CM_ SG_ 784 bms0_stsToogleRunning "BMS Running toggle";
CM_ SG_ 784 bms0_stsToogleMesaure "BMS Running toggle";
CM_ SG_ 784 bms0_DiagMsg_VCU_Status "Message Diag.";
CM_ SG_ 784 bms0_DiagMsg_VCU_ODO "Message Diag.";
CM_ SG_ 784 bms0_DiagMsg_VCU_Control "Message Diag.";
CM_ SG_ 784 bms0_DiagMsg_Charger_Status "Message Diag.";
CM_ SG_ 784 bms0_DiagMsg_Charger_Diag "Message Diag.";
CM_ SG_ 784 bms0_DiagMsg_Charger_Control "Message Diag.";
CM_ SG_ 784 bms0_stsBmsState "Present state of the battery pack";
CM_ SG_ 784 bms0_stsChecksum_stsBMS "Checksum value for each message
CS = BITWISEXOR([0],[1])
CS = BITWISEXOR(CS,[2])
CS = BITWISEXOR(CS,[3])
CS = BITWISEXOR(CS,[4])
CS = BITWISEXOR(CS,[5])
CS = BITWISEXOR(CS,[6])
[7] = CS";
CM_ SG_ 784 bms0_stsAliveCnt_stsBMS "Alive count valure to check stuck message
(Value will be increased as like 0->1->2->…->15->0->1->2… every single transmit.)";
CM_ SG_ 784 bms0_stsPwrDFET "control status of D-FET";
CM_ SG_ 784 bms0_stsPwrCFET "control status of C-FET";
CM_ SG_ 784 bms0_stsPrechargeFET "control status of Precharge-FET";
CM_ SG_ 784 bms0_stsFullyCharged "Fully charged status. ";
CM_ SG_ 784 bms0_stsDiagInfo "This signal will be presented all diag. items status.";
CM_ SG_ 784 bms0_stsCurrentDirection "Current(Amps) Direction";
CM_ SG_ 784 bms0_stsIgnitionRecog "Status that BMS recognizes ignition pin";
CM_ SG_ 784 bms0_stsBmsMode "Present mode of the battery pack";
BA_DEF_ BO_  "cycleMilliSecs100" INT 0 100;
BA_DEF_ BO_  "GenMsgCycleTime" INT 0 65000;
BA_DEF_ BO_  "GenMsgSendType" ENUM  "Fixed Periodic","Enabled Periodic","NoMsgSendType","Event";
BA_DEF_ BO_  "targetGw" ENUM  "BPG","BGW","IVI","SDCM","ALL";
BA_DEF_ BO_  "transmitMsgRateEthernetMs" ENUM  "10","100","1000";
BA_DEF_ SG_  "GenSigStartValue" INT 0 0;
BA_DEF_ SG_  "SNARequired" ENUM  "Required","NotRequired";
BA_DEF_DEF_  "cycleMilliSecs100" 100;
BA_DEF_DEF_  "GenMsgCycleTime" 0;
BA_DEF_DEF_  "GenMsgSendType" "NoMsgSendType";
BA_DEF_DEF_  "targetGw" "ALL";
BA_DEF_DEF_  "transmitMsgRateEthernetMs" "1000";
BA_DEF_DEF_  "GenSigStartValue" 0;
BA_DEF_DEF_  "SNARequired" "Required";
BA_ "GenMsgCycleTime" BO_ 799 100;
BA_ "GenMsgSendType" BO_ 799 0;
BA_ "GenMsgCycleTime" BO_ 798 100;
BA_ "GenMsgSendType" BO_ 798 0;
BA_ "GenMsgSendType" BO_ 780 0;
BA_ "GenMsgCycleTime" BO_ 780 100;
BA_ "GenMsgSendType" BO_ 809 0;
BA_ "GenMsgCycleTime" BO_ 809 150;
BA_ "GenMsgSendType" BO_ 810 0;
BA_ "GenMsgCycleTime" BO_ 810 150;
BA_ "GenMsgSendType" BO_ 793 0;
BA_ "GenMsgCycleTime" BO_ 793 150;
BA_ "GenMsgSendType" BO_ 794 0;
BA_ "GenMsgCycleTime" BO_ 794 150;
BA_ "GenMsgSendType" BO_ 806 0;
BA_ "GenMsgCycleTime" BO_ 806 150;
BA_ "GenMsgSendType" BO_ 808 0;
BA_ "GenMsgCycleTime" BO_ 808 150;
BA_ "GenMsgSendType" BO_ 790 0;
BA_ "GenMsgCycleTime" BO_ 790 150;
BA_ "GenMsgSendType" BO_ 792 0;
BA_ "GenMsgCycleTime" BO_ 792 150;
BA_ "GenMsgCycleTime" BO_ 813 1000;
BA_ "GenMsgSendType" BO_ 813 0;
BA_ "GenMsgCycleTime" BO_ 811 5000;
BA_ "GenMsgSendType" BO_ 811 0;
BA_ "GenMsgCycleTime" BO_ 805 500;
BA_ "GenMsgSendType" BO_ 805 0;
BA_ "GenMsgCycleTime" BO_ 807 1000;
BA_ "GenMsgSendType" BO_ 807 0;
BA_ "GenMsgCycleTime" BO_ 802 150;
BA_ "GenMsgSendType" BO_ 802 0;
BA_ "GenMsgCycleTime" BO_ 803 150;
BA_ "GenMsgSendType" BO_ 803 0;
BA_ "GenMsgCycleTime" BO_ 832 1000;
BA_ "GenMsgSendType" BO_ 832 0;
BA_ "GenMsgCycleTime" BO_ 838 1000;
BA_ "GenMsgSendType" BO_ 838 0;
BA_ "GenMsgCycleTime" BO_ 837 1000;
BA_ "GenMsgSendType" BO_ 837 0;
BA_ "GenMsgCycleTime" BO_ 836 1000;
BA_ "GenMsgSendType" BO_ 836 0;
BA_ "GenMsgCycleTime" BO_ 835 1000;
BA_ "GenMsgSendType" BO_ 835 0;
BA_ "GenMsgCycleTime" BO_ 834 1000;
BA_ "GenMsgSendType" BO_ 834 0;
BA_ "GenMsgCycleTime" BO_ 833 1000;
BA_ "GenMsgSendType" BO_ 833 0;
BA_ "GenMsgCycleTime" BO_ 843 1000;
BA_ "GenMsgSendType" BO_ 843 0;
BA_ "GenMsgCycleTime" BO_ 842 1000;
BA_ "GenMsgSendType" BO_ 842 0;
BA_ "GenMsgCycleTime" BO_ 841 1000;
BA_ "GenMsgSendType" BO_ 841 0;
BA_ "GenMsgCycleTime" BO_ 840 1000;
BA_ "GenMsgSendType" BO_ 840 0;
BA_ "GenMsgSendType" BO_ 827 0;
BA_ "GenMsgCycleTime" BO_ 827 1000;
BA_ "GenMsgSendType" BO_ 826 0;
BA_ "GenMsgCycleTime" BO_ 826 1000;
BA_ "GenMsgSendType" BO_ 824 0;
BA_ "GenMsgCycleTime" BO_ 824 1000;
BA_ "GenMsgSendType" BO_ 825 0;
BA_ "GenMsgCycleTime" BO_ 825 1000;
BA_ "GenMsgSendType" BO_ 781 3;
BA_ "GenMsgSendType" BO_ 797 0;
BA_ "GenMsgCycleTime" BO_ 797 1000;
BA_ "GenMsgSendType" BO_ 796 0;
BA_ "GenMsgCycleTime" BO_ 796 1000;
BA_ "GenMsgSendType" BO_ 817 0;
BA_ "GenMsgCycleTime" BO_ 817 1000;
BA_ "GenMsgSendType" BO_ 818 0;
BA_ "GenMsgCycleTime" BO_ 818 1000;
BA_ "GenMsgSendType" BO_ 819 0;
BA_ "GenMsgCycleTime" BO_ 819 1000;
BA_ "GenMsgSendType" BO_ 820 0;
BA_ "GenMsgCycleTime" BO_ 820 1000;
BA_ "GenMsgSendType" BO_ 821 0;
BA_ "GenMsgCycleTime" BO_ 821 1000;
BA_ "GenMsgSendType" BO_ 822 0;
BA_ "GenMsgCycleTime" BO_ 822 1000;
BA_ "GenMsgSendType" BO_ 816 0;
BA_ "GenMsgCycleTime" BO_ 816 1000;
BA_ "GenMsgSendType" BO_ 788 0;
BA_ "GenMsgCycleTime" BO_ 788 100;
BA_ "GenMsgSendType" BO_ 787 0;
BA_ "GenMsgCycleTime" BO_ 787 150;
BA_ "GenMsgSendType" BO_ 785 0;
BA_ "GenMsgCycleTime" BO_ 785 150;
BA_ "GenMsgSendType" BO_ 791 0;
BA_ "GenMsgCycleTime" BO_ 791 1000;
BA_ "GenMsgSendType" BO_ 789 0;
BA_ "GenMsgCycleTime" BO_ 789 500;
BA_ "GenMsgSendType" BO_ 795 0;
BA_ "GenMsgCycleTime" BO_ 795 5000;
BA_ "GenMsgCycleTime" BO_ 786 150;
BA_ "GenMsgSendType" BO_ 786 0;
BA_ "GenMsgSendType" BO_ 1281 0;
BA_ "GenMsgCycleTime" BO_ 1281 500;
BA_ "GenMsgSendType" BO_ 1282 0;
BA_ "GenMsgCycleTime" BO_ 1282 150;
BA_ "GenMsgSendType" BO_ 1283 0;
BA_ "GenMsgCycleTime" BO_ 1283 500;
BA_ "GenMsgSendType" BO_ 783 3;
BA_ "GenMsgSendType" BO_ 784 0;
BA_ "GenMsgCycleTime" BO_ 784 10;
VAL_ 799 bms0_stsDiagFaultEntry8 136 "Diag Cell - Low SOHe_FAILURE" 135 "Diag Cell - Low SOHe_FAULT" 134 "Diag Cell - Low SOHe_WARN2" 133 "Diag Cell - Low SOHe_WARN1" 132 "Diag ASIC - OVERRIDE_FAILURE" 131 "Diag ASIC - OVERRIDE_FAULT" 130 "Diag ASIC - OVERRIDE_WARN2" 129 "Diag ASIC - OVERRIDE_WARN1" 128 "Diag ASIC - XREADY_FAILURE" 127 "Diag ASIC - XREADY_FAULT" 126 "Diag ASIC - XREADY_WARN2" 125 "Diag ASIC - XREADY_WARN1" 124 "SNA" 123 "SNA" 122 "SNA" 121 "SNA" 120 "Diag ASIC - SCD_FAILURE" 119 "Diag ASIC - SCD_FAULT" 118 "Diag ASIC - SCD_WARN2" 117 "Diag ASIC - SCD_WARN1" 116 "SNA" 115 "SNA" 114 "SNA" 113 "SNA" 112 "Diag ASIC - ODC_FAILURE" 111 "Diag ASIC - ODC_FAULT" 110 "Diag ASIC - ODC_WARN2" 109 "Diag ASIC - ODC_WARN1" 108 "Diag ASIC - UV_FAILURE" 107 "Diag ASIC - UV_FAULT" 106 "Diag ASIC - UV_WARN2" 105 "Diag ASIC - UV_WARN1" 104 "Diag ASIC - OV_FAILURE" 103 "Diag ASIC - OV_FAULT" 102 "Diag ASIC - OV_WARN2" 101 "Diag ASIC - OV_WARN1" 100 "Diag Pack - FETsOT_FAILURE" 99 "Diag Pack - FETsOT_FAULT" 98 "Diag Pack - FETsOT_WARN2" 97 "Diag Pack - FETsOT_WARN1" 96 "Diag Pack - FUSEOC_FAILURE" 95 "Diag Pack - FUSEOC_FAULT" 94 "Diag Pack - FUSEOC_WARN2" 93 "Diag Pack - FUSEOC_WARN1" 92 "Diag Pack - FUSEBLOW_FAILURE" 91 "Diag Pack - FUSEBLOW_FAULT" 90 "Diag Pack - FUSEBLOW_WARN2" 89 "Diag Pack - FUSEBLOW_WARN1" 88 "Diag Pack - FUSEROHM_FAILURE" 87 "Diag Pack - FUSEROHM_FAULT" 86 "Diag Pack - FUSEROHM_WARN2" 85 "Diag Pack - FUSEROHM_WARN1" 84 "Diag BMS- ASIC_LOC_FAILURE" 83 "Diag BMS- ASIC_LOC_FAULT" 82 "Diag BMS- ASIC_LOC_WARN2" 81 "Diag BMS- ASIC_LOC_WARN1" 80 "Diag BMS- ASIC_SHUTDOWN_FAILURE" 79 "Diag BMS- ASIC_SHUTDOWN_FAULT" 78 "Diag BMS- ASIC_SHUTDOWN_WARN2" 77 "Diag BMS- ASIC_SHUTDOWN_WARN1" 76 "Diag BMS- PFET_TIMEOUT_FAILURE" 75 "Diag BMS- PFET_TIMEOUT_FAULT" 74 "Diag BMS- PFET_TIMEOUT_WARN2" 73 "Diag BMS- PFET_TIMEOUT_WARN1" 72 "Diag BMS- PFET_OT_FAILURE" 71 "Diag BMS- PFET_OT_FAULT" 70 "Diag BMS- PFET_OT_WARN2" 69 "Diag BMS- PFET_OT_WARN1" 68 "Diag BMS- CFET_FAILURE" 67 "Diag BMS- CFET_FAULT" 66 "Diag BMS- CFET_WARN2" 65 "Diag BMS- CFET_WARN1" 64 "Diag BMS- DFET_FAILURE" 63 "Diag BMS- DFET_FAULT" 62 "Diag BMS- DFET_WARN2" 61 "Diag BMS- DFET_WARN1" 60 "Diag BMS- SHORT IC" 59 "Diag BMS- OVIC_FAULT" 58 "Diag BMS- OVIC_WARN2" 57 "Diag BMS- OVIC_WARN1" 56 "Diag Cell - SOC-IM_FAILURE" 55 "Diag Cell - SOC-IM_FAULT" 54 "Diag Cell - SOC-IM_WARN2" 53 "Diag Cell - SOC-IM_WARN1" 52 "Diag Cell - TIM_FAILURE" 51 "Diag Cell - TIM_FAULT" 50 "Diag Cell - TIM_WARN2" 49 "Diag Cell - TIM_WARN1" 48 "Diag Cell - CIM-REST_FAILURE" 47 "Diag Cell - CIM-REST_FAULT" 46 "Diag Cell - CIM-REST_WARN2" 45 "Diag Cell - CIM-REST_WARN1" 44 "Diag Cell - CIM-CHG_FAILURE" 43 "Diag Cell - CIM-CHG_FAULT" 42 "Diag Cell - CIM-CHG_WARN2" 41 "Diag Cell - CIM-CHG_WARN1" 40 "Diag Cell - UDTP_FAILURE" 39 "Diag Cell - UDTP_FAULT" 38 "Diag Cell - UDTP_WARN2" 37 "Diag Cell - UDTP_WARN1" 36 "Diag Cell - UCTP_FAILURE" 35 "Diag Cell - UCTP_FAULT" 34 "Diag Cell - UCTP_WARN2" 33 "Diag Cell - UCTP_WARN1" 32 "Diag Cell - ODTP_FAILURE" 31 "Diag Cell - ODTP_FAULT" 30 "Diag Cell - ODTP_WARN2" 29 "Diag Cell - ODTP_WARN1" 28 "Diag Cell - OCTP_FAILURE" 27 "Diag Cell - OCTP_FAULT" 26 "Diag Cell - OCTP_WARN2" 25 "Diag Cell - OCTP_WARN1" 24 "Diag Cell - ODCP_FAILURE" 23 "Diag Cell - ODCP_FAULT" 22 "Diag Cell - ODCP_WARN2" 21 "Diag Cell - ODCP_WARN1" 20 "Diag Cell - OCCP_FAILURE" 19 "Diag Cell - OCCP_FAULT" 18 "Diag Cell - OCCP_WARN2" 17 "Diag Cell - OCCP_WARN1" 16 "Diag Cell - UVP_PACK_FAILURE" 15 "Diag Cell - UVP_PACK_FAULT" 14 "Diag Cell - UVP_PACK_WARN2" 13 "Diag Cell - UVP_PACK_WARN1" 12 "Diag Cell - OVP_PACK_FAILURE" 11 "Diag Cell - OVP_PACK_FAULT" 10 "Diag Cell - OVP_PACK_WARN2" 9 "Diag Cell - OVP_PACK_WARN1" 8 "Diag Cell - UVP_FAILURE" 7 "Diag Cell - UVP_FAULT" 6 "Diag Cell - UVP_WARN2" 5 "Diag Cell - UVP_WARN1" 4 "Diag Cell - OVP_FAILURE" 3 "Diag Cell - OVP_FAULT" 2 "Diag Cell - OVP_WARN2" 1 "Diag Cell - OVP_WARN1" 0 "NORMAL" ;
VAL_ 799 bms0_stsDiagFaultEntry7 136 "Diag Cell - Low SOHe_FAILURE" 135 "Diag Cell - Low SOHe_FAULT" 134 "Diag Cell - Low SOHe_WARN2" 133 "Diag Cell - Low SOHe_WARN1" 132 "Diag ASIC - OVERRIDE_FAILURE" 131 "Diag ASIC - OVERRIDE_FAULT" 130 "Diag ASIC - OVERRIDE_WARN2" 129 "Diag ASIC - OVERRIDE_WARN1" 128 "Diag ASIC - XREADY_FAILURE" 127 "Diag ASIC - XREADY_FAULT" 126 "Diag ASIC - XREADY_WARN2" 125 "Diag ASIC - XREADY_WARN1" 124 "SNA" 123 "SNA" 122 "SNA" 121 "SNA" 120 "Diag ASIC - SCD_FAILURE" 119 "Diag ASIC - SCD_FAULT" 118 "Diag ASIC - SCD_WARN2" 117 "Diag ASIC - SCD_WARN1" 116 "SNA" 115 "SNA" 114 "SNA" 113 "SNA" 112 "Diag ASIC - ODC_FAILURE" 111 "Diag ASIC - ODC_FAULT" 110 "Diag ASIC - ODC_WARN2" 109 "Diag ASIC - ODC_WARN1" 108 "Diag ASIC - UV_FAILURE" 107 "Diag ASIC - UV_FAULT" 106 "Diag ASIC - UV_WARN2" 105 "Diag ASIC - UV_WARN1" 104 "Diag ASIC - OV_FAILURE" 103 "Diag ASIC - OV_FAULT" 102 "Diag ASIC - OV_WARN2" 101 "Diag ASIC - OV_WARN1" 100 "Diag Pack - FETsOT_FAILURE" 99 "Diag Pack - FETsOT_FAULT" 98 "Diag Pack - FETsOT_WARN2" 97 "Diag Pack - FETsOT_WARN1" 96 "Diag Pack - FUSEOC_FAILURE" 95 "Diag Pack - FUSEOC_FAULT" 94 "Diag Pack - FUSEOC_WARN2" 93 "Diag Pack - FUSEOC_WARN1" 92 "Diag Pack - FUSEBLOW_FAILURE" 91 "Diag Pack - FUSEBLOW_FAULT" 90 "Diag Pack - FUSEBLOW_WARN2" 89 "Diag Pack - FUSEBLOW_WARN1" 88 "Diag Pack - FUSEROHM_FAILURE" 87 "Diag Pack - FUSEROHM_FAULT" 86 "Diag Pack - FUSEROHM_WARN2" 85 "Diag Pack - FUSEROHM_WARN1" 84 "Diag BMS- ASIC_LOC_FAILURE" 83 "Diag BMS- ASIC_LOC_FAULT" 82 "Diag BMS- ASIC_LOC_WARN2" 81 "Diag BMS- ASIC_LOC_WARN1" 80 "Diag BMS- ASIC_SHUTDOWN_FAILURE" 79 "Diag BMS- ASIC_SHUTDOWN_FAULT" 78 "Diag BMS- ASIC_SHUTDOWN_WARN2" 77 "Diag BMS- ASIC_SHUTDOWN_WARN1" 76 "Diag BMS- PFET_TIMEOUT_FAILURE" 75 "Diag BMS- PFET_TIMEOUT_FAULT" 74 "Diag BMS- PFET_TIMEOUT_WARN2" 73 "Diag BMS- PFET_TIMEOUT_WARN1" 72 "Diag BMS- PFET_OT_FAILURE" 71 "Diag BMS- PFET_OT_FAULT" 70 "Diag BMS- PFET_OT_WARN2" 69 "Diag BMS- PFET_OT_WARN1" 68 "Diag BMS- CFET_FAILURE" 67 "Diag BMS- CFET_FAULT" 66 "Diag BMS- CFET_WARN2" 65 "Diag BMS- CFET_WARN1" 64 "Diag BMS- DFET_FAILURE" 63 "Diag BMS- DFET_FAULT" 62 "Diag BMS- DFET_WARN2" 61 "Diag BMS- DFET_WARN1" 60 "Diag BMS- SHORT IC" 59 "Diag BMS- OVIC_FAULT" 58 "Diag BMS- OVIC_WARN2" 57 "Diag BMS- OVIC_WARN1" 56 "Diag Cell - SOC-IM_FAILURE" 55 "Diag Cell - SOC-IM_FAULT" 54 "Diag Cell - SOC-IM_WARN2" 53 "Diag Cell - SOC-IM_WARN1" 52 "Diag Cell - TIM_FAILURE" 51 "Diag Cell - TIM_FAULT" 50 "Diag Cell - TIM_WARN2" 49 "Diag Cell - TIM_WARN1" 48 "Diag Cell - CIM-REST_FAILURE" 47 "Diag Cell - CIM-REST_FAULT" 46 "Diag Cell - CIM-REST_WARN2" 45 "Diag Cell - CIM-REST_WARN1" 44 "Diag Cell - CIM-CHG_FAILURE" 43 "Diag Cell - CIM-CHG_FAULT" 42 "Diag Cell - CIM-CHG_WARN2" 41 "Diag Cell - CIM-CHG_WARN1" 40 "Diag Cell - UDTP_FAILURE" 39 "Diag Cell - UDTP_FAULT" 38 "Diag Cell - UDTP_WARN2" 37 "Diag Cell - UDTP_WARN1" 36 "Diag Cell - UCTP_FAILURE" 35 "Diag Cell - UCTP_FAULT" 34 "Diag Cell - UCTP_WARN2" 33 "Diag Cell - UCTP_WARN1" 32 "Diag Cell - ODTP_FAILURE" 31 "Diag Cell - ODTP_FAULT" 30 "Diag Cell - ODTP_WARN2" 29 "Diag Cell - ODTP_WARN1" 28 "Diag Cell - OCTP_FAILURE" 27 "Diag Cell - OCTP_FAULT" 26 "Diag Cell - OCTP_WARN2" 25 "Diag Cell - OCTP_WARN1" 24 "Diag Cell - ODCP_FAILURE" 23 "Diag Cell - ODCP_FAULT" 22 "Diag Cell - ODCP_WARN2" 21 "Diag Cell - ODCP_WARN1" 20 "Diag Cell - OCCP_FAILURE" 19 "Diag Cell - OCCP_FAULT" 18 "Diag Cell - OCCP_WARN2" 17 "Diag Cell - OCCP_WARN1" 16 "Diag Cell - UVP_PACK_FAILURE" 15 "Diag Cell - UVP_PACK_FAULT" 14 "Diag Cell - UVP_PACK_WARN2" 13 "Diag Cell - UVP_PACK_WARN1" 12 "Diag Cell - OVP_PACK_FAILURE" 11 "Diag Cell - OVP_PACK_FAULT" 10 "Diag Cell - OVP_PACK_WARN2" 9 "Diag Cell - OVP_PACK_WARN1" 8 "Diag Cell - UVP_FAILURE" 7 "Diag Cell - UVP_FAULT" 6 "Diag Cell - UVP_WARN2" 5 "Diag Cell - UVP_WARN1" 4 "Diag Cell - OVP_FAILURE" 3 "Diag Cell - OVP_FAULT" 2 "Diag Cell - OVP_WARN2" 1 "Diag Cell - OVP_WARN1" 0 "NORMAL" ;
VAL_ 798 bms0_stsDiagFaultEntry6 136 "Diag Cell - Low SOHe_FAILURE" 135 "Diag Cell - Low SOHe_FAULT" 134 "Diag Cell - Low SOHe_WARN2" 133 "Diag Cell - Low SOHe_WARN1" 132 "Diag ASIC - OVERRIDE_FAILURE" 131 "Diag ASIC - OVERRIDE_FAULT" 130 "Diag ASIC - OVERRIDE_WARN2" 129 "Diag ASIC - OVERRIDE_WARN1" 128 "Diag ASIC - XREADY_FAILURE" 127 "Diag ASIC - XREADY_FAULT" 126 "Diag ASIC - XREADY_WARN2" 125 "Diag ASIC - XREADY_WARN1" 124 "SNA" 123 "SNA" 122 "SNA" 121 "SNA" 120 "Diag ASIC - SCD_FAILURE" 119 "Diag ASIC - SCD_FAULT" 118 "Diag ASIC - SCD_WARN2" 117 "Diag ASIC - SCD_WARN1" 116 "SNA" 115 "SNA" 114 "SNA" 113 "SNA" 112 "Diag ASIC - ODC_FAILURE" 111 "Diag ASIC - ODC_FAULT" 110 "Diag ASIC - ODC_WARN2" 109 "Diag ASIC - ODC_WARN1" 108 "Diag ASIC - UV_FAILURE" 107 "Diag ASIC - UV_FAULT" 106 "Diag ASIC - UV_WARN2" 105 "Diag ASIC - UV_WARN1" 104 "Diag ASIC - OV_FAILURE" 103 "Diag ASIC - OV_FAULT" 102 "Diag ASIC - OV_WARN2" 101 "Diag ASIC - OV_WARN1" 100 "Diag Pack - FETsOT_FAILURE" 99 "Diag Pack - FETsOT_FAULT" 98 "Diag Pack - FETsOT_WARN2" 97 "Diag Pack - FETsOT_WARN1" 96 "Diag Pack - FUSEOC_FAILURE" 95 "Diag Pack - FUSEOC_FAULT" 94 "Diag Pack - FUSEOC_WARN2" 93 "Diag Pack - FUSEOC_WARN1" 92 "Diag Pack - FUSEBLOW_FAILURE" 91 "Diag Pack - FUSEBLOW_FAULT" 90 "Diag Pack - FUSEBLOW_WARN2" 89 "Diag Pack - FUSEBLOW_WARN1" 88 "Diag Pack - FUSEROHM_FAILURE" 87 "Diag Pack - FUSEROHM_FAULT" 86 "Diag Pack - FUSEROHM_WARN2" 85 "Diag Pack - FUSEROHM_WARN1" 84 "Diag BMS- ASIC_LOC_FAILURE" 83 "Diag BMS- ASIC_LOC_FAULT" 82 "Diag BMS- ASIC_LOC_WARN2" 81 "Diag BMS- ASIC_LOC_WARN1" 80 "Diag BMS- ASIC_SHUTDOWN_FAILURE" 79 "Diag BMS- ASIC_SHUTDOWN_FAULT" 78 "Diag BMS- ASIC_SHUTDOWN_WARN2" 77 "Diag BMS- ASIC_SHUTDOWN_WARN1" 76 "Diag BMS- PFET_TIMEOUT_FAILURE" 75 "Diag BMS- PFET_TIMEOUT_FAULT" 74 "Diag BMS- PFET_TIMEOUT_WARN2" 73 "Diag BMS- PFET_TIMEOUT_WARN1" 72 "Diag BMS- PFET_OT_FAILURE" 71 "Diag BMS- PFET_OT_FAULT" 70 "Diag BMS- PFET_OT_WARN2" 69 "Diag BMS- PFET_OT_WARN1" 68 "Diag BMS- CFET_FAILURE" 67 "Diag BMS- CFET_FAULT" 66 "Diag BMS- CFET_WARN2" 65 "Diag BMS- CFET_WARN1" 64 "Diag BMS- DFET_FAILURE" 63 "Diag BMS- DFET_FAULT" 62 "Diag BMS- DFET_WARN2" 61 "Diag BMS- DFET_WARN1" 60 "Diag BMS- SHORT IC" 59 "Diag BMS- OVIC_FAULT" 58 "Diag BMS- OVIC_WARN2" 57 "Diag BMS- OVIC_WARN1" 56 "Diag Cell - SOC-IM_FAILURE" 55 "Diag Cell - SOC-IM_FAULT" 54 "Diag Cell - SOC-IM_WARN2" 53 "Diag Cell - SOC-IM_WARN1" 52 "Diag Cell - TIM_FAILURE" 51 "Diag Cell - TIM_FAULT" 50 "Diag Cell - TIM_WARN2" 49 "Diag Cell - TIM_WARN1" 48 "Diag Cell - CIM-REST_FAILURE" 47 "Diag Cell - CIM-REST_FAULT" 46 "Diag Cell - CIM-REST_WARN2" 45 "Diag Cell - CIM-REST_WARN1" 44 "Diag Cell - CIM-CHG_FAILURE" 43 "Diag Cell - CIM-CHG_FAULT" 42 "Diag Cell - CIM-CHG_WARN2" 41 "Diag Cell - CIM-CHG_WARN1" 40 "Diag Cell - UDTP_FAILURE" 39 "Diag Cell - UDTP_FAULT" 38 "Diag Cell - UDTP_WARN2" 37 "Diag Cell - UDTP_WARN1" 36 "Diag Cell - UCTP_FAILURE" 35 "Diag Cell - UCTP_FAULT" 34 "Diag Cell - UCTP_WARN2" 33 "Diag Cell - UCTP_WARN1" 32 "Diag Cell - ODTP_FAILURE" 31 "Diag Cell - ODTP_FAULT" 30 "Diag Cell - ODTP_WARN2" 29 "Diag Cell - ODTP_WARN1" 28 "Diag Cell - OCTP_FAILURE" 27 "Diag Cell - OCTP_FAULT" 26 "Diag Cell - OCTP_WARN2" 25 "Diag Cell - OCTP_WARN1" 24 "Diag Cell - ODCP_FAILURE" 23 "Diag Cell - ODCP_FAULT" 22 "Diag Cell - ODCP_WARN2" 21 "Diag Cell - ODCP_WARN1" 20 "Diag Cell - OCCP_FAILURE" 19 "Diag Cell - OCCP_FAULT" 18 "Diag Cell - OCCP_WARN2" 17 "Diag Cell - OCCP_WARN1" 16 "Diag Cell - UVP_PACK_FAILURE" 15 "Diag Cell - UVP_PACK_FAULT" 14 "Diag Cell - UVP_PACK_WARN2" 13 "Diag Cell - UVP_PACK_WARN1" 12 "Diag Cell - OVP_PACK_FAILURE" 11 "Diag Cell - OVP_PACK_FAULT" 10 "Diag Cell - OVP_PACK_WARN2" 9 "Diag Cell - OVP_PACK_WARN1" 8 "Diag Cell - UVP_FAILURE" 7 "Diag Cell - UVP_FAULT" 6 "Diag Cell - UVP_WARN2" 5 "Diag Cell - UVP_WARN1" 4 "Diag Cell - OVP_FAILURE" 3 "Diag Cell - OVP_FAULT" 2 "Diag Cell - OVP_WARN2" 1 "Diag Cell - OVP_WARN1" 0 "NORMAL" ;
VAL_ 798 bms0_stsDiagFaultEntry5 136 "Diag Cell - Low SOHe_FAILURE" 135 "Diag Cell - Low SOHe_FAULT" 134 "Diag Cell - Low SOHe_WARN2" 133 "Diag Cell - Low SOHe_WARN1" 132 "Diag ASIC - OVERRIDE_FAILURE" 131 "Diag ASIC - OVERRIDE_FAULT" 130 "Diag ASIC - OVERRIDE_WARN2" 129 "Diag ASIC - OVERRIDE_WARN1" 128 "Diag ASIC - XREADY_FAILURE" 127 "Diag ASIC - XREADY_FAULT" 126 "Diag ASIC - XREADY_WARN2" 125 "Diag ASIC - XREADY_WARN1" 124 "SNA" 123 "SNA" 122 "SNA" 121 "SNA" 120 "Diag ASIC - SCD_FAILURE" 119 "Diag ASIC - SCD_FAULT" 118 "Diag ASIC - SCD_WARN2" 117 "Diag ASIC - SCD_WARN1" 116 "SNA" 115 "SNA" 114 "SNA" 113 "SNA" 112 "Diag ASIC - ODC_FAILURE" 111 "Diag ASIC - ODC_FAULT" 110 "Diag ASIC - ODC_WARN2" 109 "Diag ASIC - ODC_WARN1" 108 "Diag ASIC - UV_FAILURE" 107 "Diag ASIC - UV_FAULT" 106 "Diag ASIC - UV_WARN2" 105 "Diag ASIC - UV_WARN1" 104 "Diag ASIC - OV_FAILURE" 103 "Diag ASIC - OV_FAULT" 102 "Diag ASIC - OV_WARN2" 101 "Diag ASIC - OV_WARN1" 100 "Diag Pack - FETsOT_FAILURE" 99 "Diag Pack - FETsOT_FAULT" 98 "Diag Pack - FETsOT_WARN2" 97 "Diag Pack - FETsOT_WARN1" 96 "Diag Pack - FUSEOC_FAILURE" 95 "Diag Pack - FUSEOC_FAULT" 94 "Diag Pack - FUSEOC_WARN2" 93 "Diag Pack - FUSEOC_WARN1" 92 "Diag Pack - FUSEBLOW_FAILURE" 91 "Diag Pack - FUSEBLOW_FAULT" 90 "Diag Pack - FUSEBLOW_WARN2" 89 "Diag Pack - FUSEBLOW_WARN1" 88 "Diag Pack - FUSEROHM_FAILURE" 87 "Diag Pack - FUSEROHM_FAULT" 86 "Diag Pack - FUSEROHM_WARN2" 85 "Diag Pack - FUSEROHM_WARN1" 84 "Diag BMS- ASIC_LOC_FAILURE" 83 "Diag BMS- ASIC_LOC_FAULT" 82 "Diag BMS- ASIC_LOC_WARN2" 81 "Diag BMS- ASIC_LOC_WARN1" 80 "Diag BMS- ASIC_SHUTDOWN_FAILURE" 79 "Diag BMS- ASIC_SHUTDOWN_FAULT" 78 "Diag BMS- ASIC_SHUTDOWN_WARN2" 77 "Diag BMS- ASIC_SHUTDOWN_WARN1" 76 "Diag BMS- PFET_TIMEOUT_FAILURE" 75 "Diag BMS- PFET_TIMEOUT_FAULT" 74 "Diag BMS- PFET_TIMEOUT_WARN2" 73 "Diag BMS- PFET_TIMEOUT_WARN1" 72 "Diag BMS- PFET_OT_FAILURE" 71 "Diag BMS- PFET_OT_FAULT" 70 "Diag BMS- PFET_OT_WARN2" 69 "Diag BMS- PFET_OT_WARN1" 68 "Diag BMS- CFET_FAILURE" 67 "Diag BMS- CFET_FAULT" 66 "Diag BMS- CFET_WARN2" 65 "Diag BMS- CFET_WARN1" 64 "Diag BMS- DFET_FAILURE" 63 "Diag BMS- DFET_FAULT" 62 "Diag BMS- DFET_WARN2" 61 "Diag BMS- DFET_WARN1" 60 "Diag BMS- SHORT IC" 59 "Diag BMS- OVIC_FAULT" 58 "Diag BMS- OVIC_WARN2" 57 "Diag BMS- OVIC_WARN1" 56 "Diag Cell - SOC-IM_FAILURE" 55 "Diag Cell - SOC-IM_FAULT" 54 "Diag Cell - SOC-IM_WARN2" 53 "Diag Cell - SOC-IM_WARN1" 52 "Diag Cell - TIM_FAILURE" 51 "Diag Cell - TIM_FAULT" 50 "Diag Cell - TIM_WARN2" 49 "Diag Cell - TIM_WARN1" 48 "Diag Cell - CIM-REST_FAILURE" 47 "Diag Cell - CIM-REST_FAULT" 46 "Diag Cell - CIM-REST_WARN2" 45 "Diag Cell - CIM-REST_WARN1" 44 "Diag Cell - CIM-CHG_FAILURE" 43 "Diag Cell - CIM-CHG_FAULT" 42 "Diag Cell - CIM-CHG_WARN2" 41 "Diag Cell - CIM-CHG_WARN1" 40 "Diag Cell - UDTP_FAILURE" 39 "Diag Cell - UDTP_FAULT" 38 "Diag Cell - UDTP_WARN2" 37 "Diag Cell - UDTP_WARN1" 36 "Diag Cell - UCTP_FAILURE" 35 "Diag Cell - UCTP_FAULT" 34 "Diag Cell - UCTP_WARN2" 33 "Diag Cell - UCTP_WARN1" 32 "Diag Cell - ODTP_FAILURE" 31 "Diag Cell - ODTP_FAULT" 30 "Diag Cell - ODTP_WARN2" 29 "Diag Cell - ODTP_WARN1" 28 "Diag Cell - OCTP_FAILURE" 27 "Diag Cell - OCTP_FAULT" 26 "Diag Cell - OCTP_WARN2" 25 "Diag Cell - OCTP_WARN1" 24 "Diag Cell - ODCP_FAILURE" 23 "Diag Cell - ODCP_FAULT" 22 "Diag Cell - ODCP_WARN2" 21 "Diag Cell - ODCP_WARN1" 20 "Diag Cell - OCCP_FAILURE" 19 "Diag Cell - OCCP_FAULT" 18 "Diag Cell - OCCP_WARN2" 17 "Diag Cell - OCCP_WARN1" 16 "Diag Cell - UVP_PACK_FAILURE" 15 "Diag Cell - UVP_PACK_FAULT" 14 "Diag Cell - UVP_PACK_WARN2" 13 "Diag Cell - UVP_PACK_WARN1" 12 "Diag Cell - OVP_PACK_FAILURE" 11 "Diag Cell - OVP_PACK_FAULT" 10 "Diag Cell - OVP_PACK_WARN2" 9 "Diag Cell - OVP_PACK_WARN1" 8 "Diag Cell - UVP_FAILURE" 7 "Diag Cell - UVP_FAULT" 6 "Diag Cell - UVP_WARN2" 5 "Diag Cell - UVP_WARN1" 4 "Diag Cell - OVP_FAILURE" 3 "Diag Cell - OVP_FAULT" 2 "Diag Cell - OVP_WARN2" 1 "Diag Cell - OVP_WARN1" 0 "NORMAL" ;
VAL_ 798 bms0_stsDiagFaultEntry4 136 "Diag Cell - Low SOHe_FAILURE" 135 "Diag Cell - Low SOHe_FAULT" 134 "Diag Cell - Low SOHe_WARN2" 133 "Diag Cell - Low SOHe_WARN1" 132 "Diag ASIC - OVERRIDE_FAILURE" 131 "Diag ASIC - OVERRIDE_FAULT" 130 "Diag ASIC - OVERRIDE_WARN2" 129 "Diag ASIC - OVERRIDE_WARN1" 128 "Diag ASIC - XREADY_FAILURE" 127 "Diag ASIC - XREADY_FAULT" 126 "Diag ASIC - XREADY_WARN2" 125 "Diag ASIC - XREADY_WARN1" 124 "SNA" 123 "SNA" 122 "SNA" 121 "SNA" 120 "Diag ASIC - SCD_FAILURE" 119 "Diag ASIC - SCD_FAULT" 118 "Diag ASIC - SCD_WARN2" 117 "Diag ASIC - SCD_WARN1" 116 "SNA" 115 "SNA" 114 "SNA" 113 "SNA" 112 "Diag ASIC - ODC_FAILURE" 111 "Diag ASIC - ODC_FAULT" 110 "Diag ASIC - ODC_WARN2" 109 "Diag ASIC - ODC_WARN1" 108 "Diag ASIC - UV_FAILURE" 107 "Diag ASIC - UV_FAULT" 106 "Diag ASIC - UV_WARN2" 105 "Diag ASIC - UV_WARN1" 104 "Diag ASIC - OV_FAILURE" 103 "Diag ASIC - OV_FAULT" 102 "Diag ASIC - OV_WARN2" 101 "Diag ASIC - OV_WARN1" 100 "Diag Pack - FETsOT_FAILURE" 99 "Diag Pack - FETsOT_FAULT" 98 "Diag Pack - FETsOT_WARN2" 97 "Diag Pack - FETsOT_WARN1" 96 "Diag Pack - FUSEOC_FAILURE" 95 "Diag Pack - FUSEOC_FAULT" 94 "Diag Pack - FUSEOC_WARN2" 93 "Diag Pack - FUSEOC_WARN1" 92 "Diag Pack - FUSEBLOW_FAILURE" 91 "Diag Pack - FUSEBLOW_FAULT" 90 "Diag Pack - FUSEBLOW_WARN2" 89 "Diag Pack - FUSEBLOW_WARN1" 88 "Diag Pack - FUSEROHM_FAILURE" 87 "Diag Pack - FUSEROHM_FAULT" 86 "Diag Pack - FUSEROHM_WARN2" 85 "Diag Pack - FUSEROHM_WARN1" 84 "Diag BMS- ASIC_LOC_FAILURE" 83 "Diag BMS- ASIC_LOC_FAULT" 82 "Diag BMS- ASIC_LOC_WARN2" 81 "Diag BMS- ASIC_LOC_WARN1" 80 "Diag BMS- ASIC_SHUTDOWN_FAILURE" 79 "Diag BMS- ASIC_SHUTDOWN_FAULT" 78 "Diag BMS- ASIC_SHUTDOWN_WARN2" 77 "Diag BMS- ASIC_SHUTDOWN_WARN1" 76 "Diag BMS- PFET_TIMEOUT_FAILURE" 75 "Diag BMS- PFET_TIMEOUT_FAULT" 74 "Diag BMS- PFET_TIMEOUT_WARN2" 73 "Diag BMS- PFET_TIMEOUT_WARN1" 72 "Diag BMS- PFET_OT_FAILURE" 71 "Diag BMS- PFET_OT_FAULT" 70 "Diag BMS- PFET_OT_WARN2" 69 "Diag BMS- PFET_OT_WARN1" 68 "Diag BMS- CFET_FAILURE" 67 "Diag BMS- CFET_FAULT" 66 "Diag BMS- CFET_WARN2" 65 "Diag BMS- CFET_WARN1" 64 "Diag BMS- DFET_FAILURE" 63 "Diag BMS- DFET_FAULT" 62 "Diag BMS- DFET_WARN2" 61 "Diag BMS- DFET_WARN1" 60 "Diag BMS- SHORT IC" 59 "Diag BMS- OVIC_FAULT" 58 "Diag BMS- OVIC_WARN2" 57 "Diag BMS- OVIC_WARN1" 56 "Diag Cell - SOC-IM_FAILURE" 55 "Diag Cell - SOC-IM_FAULT" 54 "Diag Cell - SOC-IM_WARN2" 53 "Diag Cell - SOC-IM_WARN1" 52 "Diag Cell - TIM_FAILURE" 51 "Diag Cell - TIM_FAULT" 50 "Diag Cell - TIM_WARN2" 49 "Diag Cell - TIM_WARN1" 48 "Diag Cell - CIM-REST_FAILURE" 47 "Diag Cell - CIM-REST_FAULT" 46 "Diag Cell - CIM-REST_WARN2" 45 "Diag Cell - CIM-REST_WARN1" 44 "Diag Cell - CIM-CHG_FAILURE" 43 "Diag Cell - CIM-CHG_FAULT" 42 "Diag Cell - CIM-CHG_WARN2" 41 "Diag Cell - CIM-CHG_WARN1" 40 "Diag Cell - UDTP_FAILURE" 39 "Diag Cell - UDTP_FAULT" 38 "Diag Cell - UDTP_WARN2" 37 "Diag Cell - UDTP_WARN1" 36 "Diag Cell - UCTP_FAILURE" 35 "Diag Cell - UCTP_FAULT" 34 "Diag Cell - UCTP_WARN2" 33 "Diag Cell - UCTP_WARN1" 32 "Diag Cell - ODTP_FAILURE" 31 "Diag Cell - ODTP_FAULT" 30 "Diag Cell - ODTP_WARN2" 29 "Diag Cell - ODTP_WARN1" 28 "Diag Cell - OCTP_FAILURE" 27 "Diag Cell - OCTP_FAULT" 26 "Diag Cell - OCTP_WARN2" 25 "Diag Cell - OCTP_WARN1" 24 "Diag Cell - ODCP_FAILURE" 23 "Diag Cell - ODCP_FAULT" 22 "Diag Cell - ODCP_WARN2" 21 "Diag Cell - ODCP_WARN1" 20 "Diag Cell - OCCP_FAILURE" 19 "Diag Cell - OCCP_FAULT" 18 "Diag Cell - OCCP_WARN2" 17 "Diag Cell - OCCP_WARN1" 16 "Diag Cell - UVP_PACK_FAILURE" 15 "Diag Cell - UVP_PACK_FAULT" 14 "Diag Cell - UVP_PACK_WARN2" 13 "Diag Cell - UVP_PACK_WARN1" 12 "Diag Cell - OVP_PACK_FAILURE" 11 "Diag Cell - OVP_PACK_FAULT" 10 "Diag Cell - OVP_PACK_WARN2" 9 "Diag Cell - OVP_PACK_WARN1" 8 "Diag Cell - UVP_FAILURE" 7 "Diag Cell - UVP_FAULT" 6 "Diag Cell - UVP_WARN2" 5 "Diag Cell - UVP_WARN1" 4 "Diag Cell - OVP_FAILURE" 3 "Diag Cell - OVP_FAULT" 2 "Diag Cell - OVP_WARN2" 1 "Diag Cell - OVP_WARN1" 0 "NORMAL" ;
VAL_ 798 bms0_stsDiagFaultEntry3 136 "Diag Cell - Low SOHe_FAILURE" 135 "Diag Cell - Low SOHe_FAULT" 134 "Diag Cell - Low SOHe_WARN2" 133 "Diag Cell - Low SOHe_WARN1" 132 "Diag ASIC - OVERRIDE_FAILURE" 131 "Diag ASIC - OVERRIDE_FAULT" 130 "Diag ASIC - OVERRIDE_WARN2" 129 "Diag ASIC - OVERRIDE_WARN1" 128 "Diag ASIC - XREADY_FAILURE" 127 "Diag ASIC - XREADY_FAULT" 126 "Diag ASIC - XREADY_WARN2" 125 "Diag ASIC - XREADY_WARN1" 124 "SNA" 123 "SNA" 122 "SNA" 121 "SNA" 120 "Diag ASIC - SCD_FAILURE" 119 "Diag ASIC - SCD_FAULT" 118 "Diag ASIC - SCD_WARN2" 117 "Diag ASIC - SCD_WARN1" 116 "SNA" 115 "SNA" 114 "SNA" 113 "SNA" 112 "Diag ASIC - ODC_FAILURE" 111 "Diag ASIC - ODC_FAULT" 110 "Diag ASIC - ODC_WARN2" 109 "Diag ASIC - ODC_WARN1" 108 "Diag ASIC - UV_FAILURE" 107 "Diag ASIC - UV_FAULT" 106 "Diag ASIC - UV_WARN2" 105 "Diag ASIC - UV_WARN1" 104 "Diag ASIC - OV_FAILURE" 103 "Diag ASIC - OV_FAULT" 102 "Diag ASIC - OV_WARN2" 101 "Diag ASIC - OV_WARN1" 100 "Diag Pack - FETsOT_FAILURE" 99 "Diag Pack - FETsOT_FAULT" 98 "Diag Pack - FETsOT_WARN2" 97 "Diag Pack - FETsOT_WARN1" 96 "Diag Pack - FUSEOC_FAILURE" 95 "Diag Pack - FUSEOC_FAULT" 94 "Diag Pack - FUSEOC_WARN2" 93 "Diag Pack - FUSEOC_WARN1" 92 "Diag Pack - FUSEBLOW_FAILURE" 91 "Diag Pack - FUSEBLOW_FAULT" 90 "Diag Pack - FUSEBLOW_WARN2" 89 "Diag Pack - FUSEBLOW_WARN1" 88 "Diag Pack - FUSEROHM_FAILURE" 87 "Diag Pack - FUSEROHM_FAULT" 86 "Diag Pack - FUSEROHM_WARN2" 85 "Diag Pack - FUSEROHM_WARN1" 84 "Diag BMS- ASIC_LOC_FAILURE" 83 "Diag BMS- ASIC_LOC_FAULT" 82 "Diag BMS- ASIC_LOC_WARN2" 81 "Diag BMS- ASIC_LOC_WARN1" 80 "Diag BMS- ASIC_SHUTDOWN_FAILURE" 79 "Diag BMS- ASIC_SHUTDOWN_FAULT" 78 "Diag BMS- ASIC_SHUTDOWN_WARN2" 77 "Diag BMS- ASIC_SHUTDOWN_WARN1" 76 "Diag BMS- PFET_TIMEOUT_FAILURE" 75 "Diag BMS- PFET_TIMEOUT_FAULT" 74 "Diag BMS- PFET_TIMEOUT_WARN2" 73 "Diag BMS- PFET_TIMEOUT_WARN1" 72 "Diag BMS- PFET_OT_FAILURE" 71 "Diag BMS- PFET_OT_FAULT" 70 "Diag BMS- PFET_OT_WARN2" 69 "Diag BMS- PFET_OT_WARN1" 68 "Diag BMS- CFET_FAILURE" 67 "Diag BMS- CFET_FAULT" 66 "Diag BMS- CFET_WARN2" 65 "Diag BMS- CFET_WARN1" 64 "Diag BMS- DFET_FAILURE" 63 "Diag BMS- DFET_FAULT" 62 "Diag BMS- DFET_WARN2" 61 "Diag BMS- DFET_WARN1" 60 "Diag BMS- SHORT IC" 59 "Diag BMS- OVIC_FAULT" 58 "Diag BMS- OVIC_WARN2" 57 "Diag BMS- OVIC_WARN1" 56 "Diag Cell - SOC-IM_FAILURE" 55 "Diag Cell - SOC-IM_FAULT" 54 "Diag Cell - SOC-IM_WARN2" 53 "Diag Cell - SOC-IM_WARN1" 52 "Diag Cell - TIM_FAILURE" 51 "Diag Cell - TIM_FAULT" 50 "Diag Cell - TIM_WARN2" 49 "Diag Cell - TIM_WARN1" 48 "Diag Cell - CIM-REST_FAILURE" 47 "Diag Cell - CIM-REST_FAULT" 46 "Diag Cell - CIM-REST_WARN2" 45 "Diag Cell - CIM-REST_WARN1" 44 "Diag Cell - CIM-CHG_FAILURE" 43 "Diag Cell - CIM-CHG_FAULT" 42 "Diag Cell - CIM-CHG_WARN2" 41 "Diag Cell - CIM-CHG_WARN1" 40 "Diag Cell - UDTP_FAILURE" 39 "Diag Cell - UDTP_FAULT" 38 "Diag Cell - UDTP_WARN2" 37 "Diag Cell - UDTP_WARN1" 36 "Diag Cell - UCTP_FAILURE" 35 "Diag Cell - UCTP_FAULT" 34 "Diag Cell - UCTP_WARN2" 33 "Diag Cell - UCTP_WARN1" 32 "Diag Cell - ODTP_FAILURE" 31 "Diag Cell - ODTP_FAULT" 30 "Diag Cell - ODTP_WARN2" 29 "Diag Cell - ODTP_WARN1" 28 "Diag Cell - OCTP_FAILURE" 27 "Diag Cell - OCTP_FAULT" 26 "Diag Cell - OCTP_WARN2" 25 "Diag Cell - OCTP_WARN1" 24 "Diag Cell - ODCP_FAILURE" 23 "Diag Cell - ODCP_FAULT" 22 "Diag Cell - ODCP_WARN2" 21 "Diag Cell - ODCP_WARN1" 20 "Diag Cell - OCCP_FAILURE" 19 "Diag Cell - OCCP_FAULT" 18 "Diag Cell - OCCP_WARN2" 17 "Diag Cell - OCCP_WARN1" 16 "Diag Cell - UVP_PACK_FAILURE" 15 "Diag Cell - UVP_PACK_FAULT" 14 "Diag Cell - UVP_PACK_WARN2" 13 "Diag Cell - UVP_PACK_WARN1" 12 "Diag Cell - OVP_PACK_FAILURE" 11 "Diag Cell - OVP_PACK_FAULT" 10 "Diag Cell - OVP_PACK_WARN2" 9 "Diag Cell - OVP_PACK_WARN1" 8 "Diag Cell - UVP_FAILURE" 7 "Diag Cell - UVP_FAULT" 6 "Diag Cell - UVP_WARN2" 5 "Diag Cell - UVP_WARN1" 4 "Diag Cell - OVP_FAILURE" 3 "Diag Cell - OVP_FAULT" 2 "Diag Cell - OVP_WARN2" 1 "Diag Cell - OVP_WARN1" 0 "NORMAL" ;
VAL_ 798 bms0_stsDiagFaultEntry2 136 "Diag Cell - Low SOHe_FAILURE" 135 "Diag Cell - Low SOHe_FAULT" 134 "Diag Cell - Low SOHe_WARN2" 133 "Diag Cell - Low SOHe_WARN1" 132 "Diag ASIC - OVERRIDE_FAILURE" 131 "Diag ASIC - OVERRIDE_FAULT" 130 "Diag ASIC - OVERRIDE_WARN2" 129 "Diag ASIC - OVERRIDE_WARN1" 128 "Diag ASIC - XREADY_FAILURE" 127 "Diag ASIC - XREADY_FAULT" 126 "Diag ASIC - XREADY_WARN2" 125 "Diag ASIC - XREADY_WARN1" 124 "SNA" 123 "SNA" 122 "SNA" 121 "SNA" 120 "Diag ASIC - SCD_FAILURE" 119 "Diag ASIC - SCD_FAULT" 118 "Diag ASIC - SCD_WARN2" 117 "Diag ASIC - SCD_WARN1" 116 "SNA" 115 "SNA" 114 "SNA" 113 "SNA" 112 "Diag ASIC - ODC_FAILURE" 111 "Diag ASIC - ODC_FAULT" 110 "Diag ASIC - ODC_WARN2" 109 "Diag ASIC - ODC_WARN1" 108 "Diag ASIC - UV_FAILURE" 107 "Diag ASIC - UV_FAULT" 106 "Diag ASIC - UV_WARN2" 105 "Diag ASIC - UV_WARN1" 104 "Diag ASIC - OV_FAILURE" 103 "Diag ASIC - OV_FAULT" 102 "Diag ASIC - OV_WARN2" 101 "Diag ASIC - OV_WARN1" 100 "Diag Pack - FETsOT_FAILURE" 99 "Diag Pack - FETsOT_FAULT" 98 "Diag Pack - FETsOT_WARN2" 97 "Diag Pack - FETsOT_WARN1" 96 "Diag Pack - FUSEOC_FAILURE" 95 "Diag Pack - FUSEOC_FAULT" 94 "Diag Pack - FUSEOC_WARN2" 93 "Diag Pack - FUSEOC_WARN1" 92 "Diag Pack - FUSEBLOW_FAILURE" 91 "Diag Pack - FUSEBLOW_FAULT" 90 "Diag Pack - FUSEBLOW_WARN2" 89 "Diag Pack - FUSEBLOW_WARN1" 88 "Diag Pack - FUSEROHM_FAILURE" 87 "Diag Pack - FUSEROHM_FAULT" 86 "Diag Pack - FUSEROHM_WARN2" 85 "Diag Pack - FUSEROHM_WARN1" 84 "Diag BMS- ASIC_LOC_FAILURE" 83 "Diag BMS- ASIC_LOC_FAULT" 82 "Diag BMS- ASIC_LOC_WARN2" 81 "Diag BMS- ASIC_LOC_WARN1" 80 "Diag BMS- ASIC_SHUTDOWN_FAILURE" 79 "Diag BMS- ASIC_SHUTDOWN_FAULT" 78 "Diag BMS- ASIC_SHUTDOWN_WARN2" 77 "Diag BMS- ASIC_SHUTDOWN_WARN1" 76 "Diag BMS- PFET_TIMEOUT_FAILURE" 75 "Diag BMS- PFET_TIMEOUT_FAULT" 74 "Diag BMS- PFET_TIMEOUT_WARN2" 73 "Diag BMS- PFET_TIMEOUT_WARN1" 72 "Diag BMS- PFET_OT_FAILURE" 71 "Diag BMS- PFET_OT_FAULT" 70 "Diag BMS- PFET_OT_WARN2" 69 "Diag BMS- PFET_OT_WARN1" 68 "Diag BMS- CFET_FAILURE" 67 "Diag BMS- CFET_FAULT" 66 "Diag BMS- CFET_WARN2" 65 "Diag BMS- CFET_WARN1" 64 "Diag BMS- DFET_FAILURE" 63 "Diag BMS- DFET_FAULT" 62 "Diag BMS- DFET_WARN2" 61 "Diag BMS- DFET_WARN1" 60 "Diag BMS- SHORT IC" 59 "Diag BMS- OVIC_FAULT" 58 "Diag BMS- OVIC_WARN2" 57 "Diag BMS- OVIC_WARN1" 56 "Diag Cell - SOC-IM_FAILURE" 55 "Diag Cell - SOC-IM_FAULT" 54 "Diag Cell - SOC-IM_WARN2" 53 "Diag Cell - SOC-IM_WARN1" 52 "Diag Cell - TIM_FAILURE" 51 "Diag Cell - TIM_FAULT" 50 "Diag Cell - TIM_WARN2" 49 "Diag Cell - TIM_WARN1" 48 "Diag Cell - CIM-REST_FAILURE" 47 "Diag Cell - CIM-REST_FAULT" 46 "Diag Cell - CIM-REST_WARN2" 45 "Diag Cell - CIM-REST_WARN1" 44 "Diag Cell - CIM-CHG_FAILURE" 43 "Diag Cell - CIM-CHG_FAULT" 42 "Diag Cell - CIM-CHG_WARN2" 41 "Diag Cell - CIM-CHG_WARN1" 40 "Diag Cell - UDTP_FAILURE" 39 "Diag Cell - UDTP_FAULT" 38 "Diag Cell - UDTP_WARN2" 37 "Diag Cell - UDTP_WARN1" 36 "Diag Cell - UCTP_FAILURE" 35 "Diag Cell - UCTP_FAULT" 34 "Diag Cell - UCTP_WARN2" 33 "Diag Cell - UCTP_WARN1" 32 "Diag Cell - ODTP_FAILURE" 31 "Diag Cell - ODTP_FAULT" 30 "Diag Cell - ODTP_WARN2" 29 "Diag Cell - ODTP_WARN1" 28 "Diag Cell - OCTP_FAILURE" 27 "Diag Cell - OCTP_FAULT" 26 "Diag Cell - OCTP_WARN2" 25 "Diag Cell - OCTP_WARN1" 24 "Diag Cell - ODCP_FAILURE" 23 "Diag Cell - ODCP_FAULT" 22 "Diag Cell - ODCP_WARN2" 21 "Diag Cell - ODCP_WARN1" 20 "Diag Cell - OCCP_FAILURE" 19 "Diag Cell - OCCP_FAULT" 18 "Diag Cell - OCCP_WARN2" 17 "Diag Cell - OCCP_WARN1" 16 "Diag Cell - UVP_PACK_FAILURE" 15 "Diag Cell - UVP_PACK_FAULT" 14 "Diag Cell - UVP_PACK_WARN2" 13 "Diag Cell - UVP_PACK_WARN1" 12 "Diag Cell - OVP_PACK_FAILURE" 11 "Diag Cell - OVP_PACK_FAULT" 10 "Diag Cell - OVP_PACK_WARN2" 9 "Diag Cell - OVP_PACK_WARN1" 8 "Diag Cell - UVP_FAILURE" 7 "Diag Cell - UVP_FAULT" 6 "Diag Cell - UVP_WARN2" 5 "Diag Cell - UVP_WARN1" 4 "Diag Cell - OVP_FAILURE" 3 "Diag Cell - OVP_FAULT" 2 "Diag Cell - OVP_WARN2" 1 "Diag Cell - OVP_WARN1" 0 "NORMAL" ;
VAL_ 798 bms0_stsDiagFaultEntry1 136 "Diag Cell - Low SOHe_FAILURE" 135 "Diag Cell - Low SOHe_FAULT" 134 "Diag Cell - Low SOHe_WARN2" 133 "Diag Cell - Low SOHe_WARN1" 132 "Diag ASIC - OVERRIDE_FAILURE" 131 "Diag ASIC - OVERRIDE_FAULT" 130 "Diag ASIC - OVERRIDE_WARN2" 129 "Diag ASIC - OVERRIDE_WARN1" 128 "Diag ASIC - XREADY_FAILURE" 127 "Diag ASIC - XREADY_FAULT" 126 "Diag ASIC - XREADY_WARN2" 125 "Diag ASIC - XREADY_WARN1" 124 "SNA" 123 "SNA" 122 "SNA" 121 "SNA" 120 "Diag ASIC - SCD_FAILURE" 119 "Diag ASIC - SCD_FAULT" 118 "Diag ASIC - SCD_WARN2" 117 "Diag ASIC - SCD_WARN1" 116 "SNA" 115 "SNA" 114 "SNA" 113 "SNA" 112 "Diag ASIC - ODC_FAILURE" 111 "Diag ASIC - ODC_FAULT" 110 "Diag ASIC - ODC_WARN2" 109 "Diag ASIC - ODC_WARN1" 108 "Diag ASIC - UV_FAILURE" 107 "Diag ASIC - UV_FAULT" 106 "Diag ASIC - UV_WARN2" 105 "Diag ASIC - UV_WARN1" 104 "Diag ASIC - OV_FAILURE" 103 "Diag ASIC - OV_FAULT" 102 "Diag ASIC - OV_WARN2" 101 "Diag ASIC - OV_WARN1" 100 "Diag Pack - FETsOT_FAILURE" 99 "Diag Pack - FETsOT_FAULT" 98 "Diag Pack - FETsOT_WARN2" 97 "Diag Pack - FETsOT_WARN1" 96 "Diag Pack - FUSEOC_FAILURE" 95 "Diag Pack - FUSEOC_FAULT" 94 "Diag Pack - FUSEOC_WARN2" 93 "Diag Pack - FUSEOC_WARN1" 92 "Diag Pack - FUSEBLOW_FAILURE" 91 "Diag Pack - FUSEBLOW_FAULT" 90 "Diag Pack - FUSEBLOW_WARN2" 89 "Diag Pack - FUSEBLOW_WARN1" 88 "Diag Pack - FUSEROHM_FAILURE" 87 "Diag Pack - FUSEROHM_FAULT" 86 "Diag Pack - FUSEROHM_WARN2" 85 "Diag Pack - FUSEROHM_WARN1" 84 "Diag BMS- ASIC_LOC_FAILURE" 83 "Diag BMS- ASIC_LOC_FAULT" 82 "Diag BMS- ASIC_LOC_WARN2" 81 "Diag BMS- ASIC_LOC_WARN1" 80 "Diag BMS- ASIC_SHUTDOWN_FAILURE" 79 "Diag BMS- ASIC_SHUTDOWN_FAULT" 78 "Diag BMS- ASIC_SHUTDOWN_WARN2" 77 "Diag BMS- ASIC_SHUTDOWN_WARN1" 76 "Diag BMS- PFET_TIMEOUT_FAILURE" 75 "Diag BMS- PFET_TIMEOUT_FAULT" 74 "Diag BMS- PFET_TIMEOUT_WARN2" 73 "Diag BMS- PFET_TIMEOUT_WARN1" 72 "Diag BMS- PFET_OT_FAILURE" 71 "Diag BMS- PFET_OT_FAULT" 70 "Diag BMS- PFET_OT_WARN2" 69 "Diag BMS- PFET_OT_WARN1" 68 "Diag BMS- CFET_FAILURE" 67 "Diag BMS- CFET_FAULT" 66 "Diag BMS- CFET_WARN2" 65 "Diag BMS- CFET_WARN1" 64 "Diag BMS- DFET_FAILURE" 63 "Diag BMS- DFET_FAULT" 62 "Diag BMS- DFET_WARN2" 61 "Diag BMS- DFET_WARN1" 60 "Diag BMS- SHORT IC" 59 "Diag BMS- OVIC_FAULT" 58 "Diag BMS- OVIC_WARN2" 57 "Diag BMS- OVIC_WARN1" 56 "Diag Cell - SOC-IM_FAILURE" 55 "Diag Cell - SOC-IM_FAULT" 54 "Diag Cell - SOC-IM_WARN2" 53 "Diag Cell - SOC-IM_WARN1" 52 "Diag Cell - TIM_FAILURE" 51 "Diag Cell - TIM_FAULT" 50 "Diag Cell - TIM_WARN2" 49 "Diag Cell - TIM_WARN1" 48 "Diag Cell - CIM-REST_FAILURE" 47 "Diag Cell - CIM-REST_FAULT" 46 "Diag Cell - CIM-REST_WARN2" 45 "Diag Cell - CIM-REST_WARN1" 44 "Diag Cell - CIM-CHG_FAILURE" 43 "Diag Cell - CIM-CHG_FAULT" 42 "Diag Cell - CIM-CHG_WARN2" 41 "Diag Cell - CIM-CHG_WARN1" 40 "Diag Cell - UDTP_FAILURE" 39 "Diag Cell - UDTP_FAULT" 38 "Diag Cell - UDTP_WARN2" 37 "Diag Cell - UDTP_WARN1" 36 "Diag Cell - UCTP_FAILURE" 35 "Diag Cell - UCTP_FAULT" 34 "Diag Cell - UCTP_WARN2" 33 "Diag Cell - UCTP_WARN1" 32 "Diag Cell - ODTP_FAILURE" 31 "Diag Cell - ODTP_FAULT" 30 "Diag Cell - ODTP_WARN2" 29 "Diag Cell - ODTP_WARN1" 28 "Diag Cell - OCTP_FAILURE" 27 "Diag Cell - OCTP_FAULT" 26 "Diag Cell - OCTP_WARN2" 25 "Diag Cell - OCTP_WARN1" 24 "Diag Cell - ODCP_FAILURE" 23 "Diag Cell - ODCP_FAULT" 22 "Diag Cell - ODCP_WARN2" 21 "Diag Cell - ODCP_WARN1" 20 "Diag Cell - OCCP_FAILURE" 19 "Diag Cell - OCCP_FAULT" 18 "Diag Cell - OCCP_WARN2" 17 "Diag Cell - OCCP_WARN1" 16 "Diag Cell - UVP_PACK_FAILURE" 15 "Diag Cell - UVP_PACK_FAULT" 14 "Diag Cell - UVP_PACK_WARN2" 13 "Diag Cell - UVP_PACK_WARN1" 12 "Diag Cell - OVP_PACK_FAILURE" 11 "Diag Cell - OVP_PACK_FAULT" 10 "Diag Cell - OVP_PACK_WARN2" 9 "Diag Cell - OVP_PACK_WARN1" 8 "Diag Cell - UVP_FAILURE" 7 "Diag Cell - UVP_FAULT" 6 "Diag Cell - UVP_WARN2" 5 "Diag Cell - UVP_WARN1" 4 "Diag Cell - OVP_FAILURE" 3 "Diag Cell - OVP_FAULT" 2 "Diag Cell - OVP_WARN2" 1 "Diag Cell - OVP_WARN1" 0 "NORMAL" ;
VAL_ 780 vfVCU_TestCmdChecksumOnOff_32F 0 "OFF" 1 "ON" ;
VAL_ 780 vfVCU_TestCmdChecksumOnOff_32E 0 "OFF" 1 "ON" ;
VAL_ 780 vfVCU_TestCmdChecksumOnOff_32A 0 "OFF" 1 "ON" ;
VAL_ 780 vfVCU_TestCmdChecksumOnOff_329 0 "OFF" 1 "ON" ;
VAL_ 780 vfVCU_TestCmdChecksumOnOff_328 0 "OFF" 1 "ON" ;
VAL_ 780 vfVCU_TestCmdChecksumOnOff_326 0 "OFF" 1 "ON" ;
VAL_ 780 vfVCU_TestCmdChecksumOnOff_324 0 "OFF" 1 "ON" ;
VAL_ 780 vfVCU_TestCmdChecksumOnOff_323 0 "OFF" 1 "ON" ;
VAL_ 780 vfVCU_TestCmdChecksumOnOff_322 0 "OFF" 1 "ON" ;
VAL_ 780 vfVCU_TestCmdChecksumOnOff_321 0 "OFF" 1 "ON" ;
VAL_ 780 vfVCU_TestCmdChecksumOnOff_320 0 "OFF" 1 "ON" ;
VAL_ 780 vfVCU_TestCmdChecksumOnOff_31F 0 "OFF" 1 "ON" ;
VAL_ 780 vfVCU_TestCmdChecksumOnOff_31E 0 "OFF" 1 "ON" ;
VAL_ 780 vfVCU_TestCmdChecksumOnOff_31A 0 "OFF" 1 "ON" ;
VAL_ 780 vfVCU_TestCmdChecksumOnOff_319 0 "OFF" 1 "ON" ;
VAL_ 780 vfVCU_TestCmdChecksumOnOff_318 0 "OFF" 1 "ON" ;
VAL_ 780 vfVCU_TestCmdChecksumOnOff_316 0 "OFF" 1 "ON" ;
VAL_ 780 vfVCU_TestCmdChecksumOnOff_314 0 "OFF" 1 "ON" ;
VAL_ 780 vfVCU_TestCmdChecksumOnOff_313 0 "OFF" 1 "ON" ;
VAL_ 780 vfVCU_TestCmdChecksumOnOff_312 0 "OFF" 1 "ON" ;
VAL_ 780 vfVCU_TestCmdChecksumOnOff_311 0 "OFF" 1 "ON" ;
VAL_ 780 vfVCU_TestCmdChecksumOnOff_310 0 "OFF" 1 "ON" ;
VAL_ 780 vfVCU_TestCmdAliveCntOnOff_32F 0 "OFF" 1 "ON" ;
VAL_ 780 vfVCU_TestCmdAliveCntOnOff_32E 0 "OFF" 1 "ON" ;
VAL_ 780 vfVCU_TestCmdAliveCntOnOff_32A 0 "OFF" 1 "ON" ;
VAL_ 780 vfVCU_TestCmdAliveCntOnOff_329 0 "OFF" 1 "ON" ;
VAL_ 780 vfVCU_TestCmdAliveCntOnOff_328 0 "OFF" 1 "ON" ;
VAL_ 780 vfVCU_TestCmdAliveCntOnOff_326 0 "OFF" 1 "ON" ;
VAL_ 780 vfVCU_TestCmdAliveCntOnOff_324 0 "OFF" 1 "ON" ;
VAL_ 780 vfVCU_TestCmdAliveCntOnOff_323 0 "OFF" 1 "ON" ;
VAL_ 780 vfVCU_TestCmdAliveCntOnOff_322 0 "OFF" 1 "ON" ;
VAL_ 780 vfVCU_TestCmdAliveCntOnOff_321 0 "OFF" 1 "ON" ;
VAL_ 780 vfVCU_TestCmdAliveCntOnOff_320 0 "OFF" 1 "ON" ;
VAL_ 780 vfVCU_TestCmdAliveCntOnOff_31F 0 "OFF" 1 "ON" ;
VAL_ 780 vfVCU_TestCmdAliveCntOnOff_31E 0 "OFF" 1 "ON" ;
VAL_ 780 vfVCU_TestCmdAliveCntOnOff_31A 0 "OFF" 1 "ON" ;
VAL_ 780 vfVCU_TestCmdAliveCntOnOff_319 0 "OFF" 1 "ON" ;
VAL_ 780 vfVCU_TestCmdAliveCntOnOff_318 0 "OFF" 1 "ON" ;
VAL_ 780 vfVCU_TestCmdAliveCntOnOff_316 0 "OFF" 1 "ON" ;
VAL_ 780 vfVCU_TestCmdAliveCntOnOff_314 0 "OFF" 1 "ON" ;
VAL_ 780 vfVCU_TestCmdAliveCntOnOff_313 0 "OFF" 1 "ON" ;
VAL_ 780 vfVCU_TestCmdAliveCntOnOff_312 0 "OFF" 1 "ON" ;
VAL_ 780 vfVCU_TestCmdAliveCntOnOff_311 0 "OFF" 1 "ON" ;
VAL_ 780 vfVCU_TestCmdAliveCntOnOff_310 0 "OFF" 1 "ON" ;
VAL_ 832 bms1_devStsCB14 3 "Ctrl - ON, Sts - ON" 2 "Ctrl - ON, Sts - OFF" 0 "Ctrl - OFF, Sts - OFF" 1 "Ctrl - OFF, Sts - ON" ;
VAL_ 832 bms1_devStsCB13 3 "Ctrl - ON, Sts - ON" 2 "Ctrl - ON, Sts - OFF" 0 "Ctrl - OFF, Sts - OFF" 1 "Ctrl - OFF, Sts - ON" ;
VAL_ 832 bms1_devStsCB12 3 "Ctrl - ON, Sts - ON" 2 "Ctrl - ON, Sts - OFF" 0 "Ctrl - OFF, Sts - OFF" 1 "Ctrl - OFF, Sts - ON" ;
VAL_ 832 bms1_devStsCB11 3 "Ctrl - ON, Sts - ON" 2 "Ctrl - ON, Sts - OFF" 0 "Ctrl - OFF, Sts - OFF" 1 "Ctrl - OFF, Sts - ON" ;
VAL_ 832 bms1_devStsCB10 3 "Ctrl - ON, Sts - ON" 2 "Ctrl - ON, Sts - OFF" 0 "Ctrl - OFF, Sts - OFF" 1 "Ctrl - OFF, Sts - ON" ;
VAL_ 832 bms1_devStsCB09 3 "Ctrl - ON, Sts - ON" 2 "Ctrl - ON, Sts - OFF" 0 "Ctrl - OFF, Sts - OFF" 1 "Ctrl - OFF, Sts - ON" ;
VAL_ 832 bms1_devStsCB08 3 "Ctrl - ON, Sts - ON" 2 "Ctrl - ON, Sts - OFF" 0 "Ctrl - OFF, Sts - OFF" 1 "Ctrl - OFF, Sts - ON" ;
VAL_ 832 bms1_devStsCB07 3 "Ctrl - ON, Sts - ON" 2 "Ctrl - ON, Sts - OFF" 0 "Ctrl - OFF, Sts - OFF" 1 "Ctrl - OFF, Sts - ON" ;
VAL_ 832 bms1_devStsCB06 3 "Ctrl - ON, Sts - ON" 2 "Ctrl - ON, Sts - OFF" 0 "Ctrl - OFF, Sts - OFF" 1 "Ctrl - OFF, Sts - ON" ;
VAL_ 832 bms1_devStsCB05 3 "Ctrl - ON, Sts - ON" 2 "Ctrl - ON, Sts - OFF" 0 "Ctrl - OFF, Sts - OFF" 1 "Ctrl - OFF, Sts - ON" ;
VAL_ 832 bms1_devStsCB04 3 "Ctrl - ON, Sts - ON" 2 "Ctrl - ON, Sts - OFF" 0 "Ctrl - OFF, Sts - OFF" 1 "Ctrl - OFF, Sts - ON" ;
VAL_ 832 bms1_devStsCB03 3 "Ctrl - ON, Sts - ON" 2 "Ctrl - ON, Sts - OFF" 0 "Ctrl - OFF, Sts - OFF" 1 "Ctrl - OFF, Sts - ON" ;
VAL_ 832 bms1_devStsCB02 3 "Ctrl - ON, Sts - ON" 2 "Ctrl - ON, Sts - OFF" 0 "Ctrl - OFF, Sts - OFF" 1 "Ctrl - OFF, Sts - ON" ;
VAL_ 832 bms1_devStsCB01 3 "Ctrl - ON, Sts - ON" 2 "Ctrl - ON, Sts - OFF" 0 "Ctrl - OFF, Sts - OFF" 1 "Ctrl - OFF, Sts - ON" ;
VAL_ 822 bms0_devStsPowertrain 254 "KEFICO" 2 "WACCO" 1 "SYM" 0 "UNDEFINED" ;
VAL_ 816 bms0_devStsCB08 3 "Ctrl - ON, Sts - ON" 2 "Ctrl - ON, Sts - OFF" 0 "Ctrl - OFF, Sts - OFF" 1 "Ctrl - OFF, Sts - ON" ;
VAL_ 816 bms0_devStsCB07 3 "Ctrl - ON, Sts - ON" 2 "Ctrl - ON, Sts - OFF" 0 "Ctrl - OFF, Sts - OFF" 1 "Ctrl - OFF, Sts - ON" ;
VAL_ 816 bms0_devStsCB06 3 "Ctrl - ON, Sts - ON" 2 "Ctrl - ON, Sts - OFF" 0 "Ctrl - OFF, Sts - OFF" 1 "Ctrl - OFF, Sts - ON" ;
VAL_ 816 bms0_devStsCB05 3 "Ctrl - ON, Sts - ON" 2 "Ctrl - ON, Sts - OFF" 0 "Ctrl - OFF, Sts - OFF" 1 "Ctrl - OFF, Sts - ON" ;
VAL_ 816 bms0_devStsCB04 3 "Ctrl - ON, Sts - ON" 2 "Ctrl - ON, Sts - OFF" 0 "Ctrl - OFF, Sts - OFF" 1 "Ctrl - OFF, Sts - ON" ;
VAL_ 816 bms0_devStsCB03 3 "Ctrl - ON, Sts - ON" 2 "Ctrl - ON, Sts - OFF" 0 "Ctrl - OFF, Sts - OFF" 1 "Ctrl - OFF, Sts - ON" ;
VAL_ 816 bms0_devStsCB02 3 "Ctrl - ON, Sts - ON" 2 "Ctrl - ON, Sts - OFF" 0 "Ctrl - OFF, Sts - OFF" 1 "Ctrl - OFF, Sts - ON" ;
VAL_ 816 bms0_devStsCB01 3 "Ctrl - ON, Sts - ON" 2 "Ctrl - ON, Sts - OFF" 0 "Ctrl - OFF, Sts - OFF" 1 "Ctrl - OFF, Sts - ON" ;
VAL_ 816 bms0_devStsCB09 3 "Ctrl - ON, Sts - ON" 2 "Ctrl - ON, Sts - OFF" 0 "Ctrl - OFF, Sts - OFF" 1 "Ctrl - OFF, Sts - ON" ;
VAL_ 816 bms0_devStsCB10 3 "Ctrl - ON, Sts - ON" 2 "Ctrl - ON, Sts - OFF" 0 "Ctrl - OFF, Sts - OFF" 1 "Ctrl - OFF, Sts - ON" ;
VAL_ 816 bms0_devStsCB11 3 "Ctrl - ON, Sts - ON" 2 "Ctrl - ON, Sts - OFF" 0 "Ctrl - OFF, Sts - OFF" 1 "Ctrl - OFF, Sts - ON" ;
VAL_ 816 bms0_devStsCB12 3 "Ctrl - ON, Sts - ON" 2 "Ctrl - ON, Sts - OFF" 0 "Ctrl - OFF, Sts - OFF" 1 "Ctrl - OFF, Sts - ON" ;
VAL_ 816 bms0_devStsCB13 3 "Ctrl - ON, Sts - ON" 2 "Ctrl - ON, Sts - OFF" 0 "Ctrl - OFF, Sts - OFF" 1 "Ctrl - OFF, Sts - ON" ;
VAL_ 816 bms0_devStsCB14 3 "Ctrl - ON, Sts - ON" 2 "Ctrl - ON, Sts - OFF" 0 "Ctrl - OFF, Sts - OFF" 1 "Ctrl - OFF, Sts - ON" ;
VAL_ 1281 charger_stsMode 0 "Reserver1" 1 "Precharge mode" 2 "Constant current mode" 3 "Constant voltage mode" 4 "Protectected" ;
VAL_ 1282 charger_reqChgMode 0 "CHGMODE_NORMAL" 1 "CHGMODE_FAST" 2 "CHGMODE_SLOW" 3 "CHGMODE_MAX" ;
VAL_ 1282 charger_ReqProtocolVer 14 "RSVD" 13 "RSVD" 12 "RSVD" 11 "RSVD" 10 "RSVD" 9 "RSVD" 8 "RSVD" 7 "RSVD" 6 "RSVD" 5 "RSVD" 4 "RSVD" 3 "RSVD" 2 "WACCO" 1 "SYM" 0 "KEFICO" ;
VAL_ 1282 charger_ReqID 3 "RSVD" 2 "2nd Pack upper 1st Pack" 1 "1st Pack nearby GND" 0 "RSVD" ;
VAL_ 1282 charger_wakeupBMS0 0 "OFF" 1 "ON" ;
VAL_ 1282 charger_verChargerType 0 "RVSD" 1 "OBC (Portable charger)" 2 "Charging station" 3 "Battery station" ;
VAL_ 1282 charger_controlmodeBMS0 0 "OFF" 1 "ON" ;
VAL_ 1282 charger_commrequiredBMS0 0 "OFF" 1 "ON" ;
VAL_ 784 bms0_DiagMsg_VCU_Status 3 "Message Timeout Error" 2 "CheckSum Error" 0 "Normal" 1 "Alive Count Error" ;
VAL_ 784 bms0_DiagMsg_VCU_ODO 3 "Message Timeout Error" 2 "CheckSum Error" 0 "Normal" 1 "Alive Count Error" ;
VAL_ 784 bms0_DiagMsg_VCU_Control 3 "Message Timeout Error" 2 "CheckSum Error" 0 "Normal" 1 "Alive Count Error" ;
VAL_ 784 bms0_DiagMsg_Charger_Status 3 "Message Timeout Error" 2 "CheckSum Error" 0 "Normal" 1 "Alive Count Error" ;
VAL_ 784 bms0_DiagMsg_Charger_Diag 3 "Message Timeout Error" 2 "CheckSum Error" 0 "Normal" 1 "Alive Count Error" ;
VAL_ 784 bms0_DiagMsg_Charger_Control 3 "Message Timeout Error" 2 "CheckSum Error" 0 "Normal" 1 "Alive Count Error" ;
VAL_ 784 bms0_stsBmsState 0 "NORAML State" 1 "SLEEP State" 2 "SHUTDOWN State" 3 "MAINTENANCE State" ;
VAL_ 784 bms0_stsPwrDFET 0 "OFF" 1 "ON" 2 "RSVD1" 3 "RSVD2" ;
VAL_ 784 bms0_stsPwrCFET 0 "OFF" 1 "ON" 2 "RSVD1" 3 "RSVD2" ;
VAL_ 784 bms0_stsPrechargeFET 0 "OFF" 1 "ON" 2 "RSVD1" 3 "RSVD2" ;
VAL_ 784 bms0_stsFullyCharged 0 "N/A" 1 "CHARGING" 2 "FULLY CHARGED" ;
VAL_ 784 bms0_stsDiagInfo 140 "Diag Cell - Diff SOHe_FAILURE" 139 "Diag Cell - Diff SOHe_FAULT" 138 "Diag Cell - Diff SOHe_WARN2" 137 "Diag Cell - Diff SOHe_WARN1" 136 "Diag Cell - Low SOHe_FAILURE" 135 "Diag Cell - Low SOHe_FAULT" 134 "Diag Cell - Low SOHe_WARN2" 133 "Diag Cell - Low SOHe_WARN1" 132 "Diag ASIC - OVERRIDE_FAILURE" 131 "Diag ASIC - OVERRIDE_FAULT" 130 "Diag ASIC - OVERRIDE_WARN2" 129 "Diag ASIC - OVERRIDE_WARN1" 128 "Diag ASIC - XREADY_FAILURE" 127 "Diag ASIC - XREADY_FAULT" 126 "Diag ASIC - XREADY_WARN2" 125 "Diag ASIC - XREADY_WARN1" 124 "SNA" 123 "SNA" 122 "SNA" 121 "SNA" 120 "Diag ASIC - SCD_FAILURE" 119 "Diag ASIC - SCD_FAULT" 118 "Diag ASIC - SCD_WARN2" 117 "Diag ASIC - SCD_WARN1" 116 "SNA" 115 "SNA" 114 "SNA" 113 "SNA" 112 "Diag ASIC - ODC_FAILURE" 111 "Diag ASIC - ODC_FAULT" 110 "Diag ASIC - ODC_WARN2" 109 "Diag ASIC - ODC_WARN1" 108 "Diag ASIC - UV_FAILURE" 107 "Diag ASIC - UV_FAULT" 106 "Diag ASIC - UV_WARN2" 105 "Diag ASIC - UV_WARN1" 104 "Diag ASIC - OV_FAILURE" 103 "Diag ASIC - OV_FAULT" 102 "Diag ASIC - OV_WARN2" 101 "Diag ASIC - OV_WARN1" 100 "Diag Pack - FETsOT_FAILURE" 99 "Diag Pack - FETsOT_FAULT" 98 "Diag Pack - FETsOT_WARN2" 97 "Diag Pack - FETsOT_WARN1" 96 "Diag Pack - FUSEOC_FAILURE" 95 "Diag Pack - FUSEOC_FAULT" 94 "Diag Pack - FUSEOC_WARN2" 93 "Diag Pack - FUSEOC_WARN1" 92 "Diag Pack - FUSEBLOW_FAILURE" 91 "Diag Pack - FUSEBLOW_FAULT" 90 "Diag Pack - FUSEBLOW_WARN2" 89 "Diag Pack - FUSEBLOW_WARN1" 88 "Diag Pack - FUSEROHM_FAILURE" 87 "Diag Pack - FUSEROHM_FAULT" 86 "Diag Pack - FUSEROHM_WARN2" 85 "Diag Pack - FUSEROHM_WARN1" 84 "Diag BMS- ASIC_LOC_FAILURE" 83 "Diag BMS- ASIC_LOC_FAULT" 82 "Diag BMS- ASIC_LOC_WARN2" 81 "Diag BMS- ASIC_LOC_WARN1" 80 "Diag BMS- ASIC_SHUTDOWN_FAILURE" 79 "Diag BMS- ASIC_SHUTDOWN_FAULT" 78 "Diag BMS- ASIC_SHUTDOWN_WARN2" 77 "Diag BMS- ASIC_SHUTDOWN_WARN1" 76 "Diag BMS- PFET_TIMEOUT_FAILURE" 75 "Diag BMS- PFET_TIMEOUT_FAULT" 74 "Diag BMS- PFET_TIMEOUT_WARN2" 73 "Diag BMS- PFET_TIMEOUT_WARN1" 72 "Diag BMS- PFET_OT_FAILURE" 71 "Diag BMS- PFET_OT_FAULT" 70 "Diag BMS- PFET_OT_WARN2" 69 "Diag BMS- PFET_OT_WARN1" 68 "Diag BMS- CFET_FAILURE" 67 "Diag BMS- CFET_FAULT" 66 "Diag BMS- CFET_WARN2" 65 "Diag BMS- CFET_WARN1" 64 "Diag BMS- DFET_FAILURE" 63 "Diag BMS- DFET_FAULT" 62 "Diag BMS- DFET_WARN2" 61 "Diag BMS- DFET_WARN1" 60 "Diag BMS- SHORT IC" 59 "Diag BMS- OVIC_FAULT" 58 "Diag BMS- OVIC_WARN2" 57 "Diag BMS- OVIC_WARN1" 56 "Diag Cell - SOC-IM_FAILURE" 55 "Diag Cell - SOC-IM_FAULT" 54 "Diag Cell - SOC-IM_WARN2" 53 "Diag Cell - SOC-IM_WARN1" 52 "Diag Cell - TIM_FAILURE" 51 "Diag Cell - TIM_FAULT" 50 "Diag Cell - TIM_WARN2" 49 "Diag Cell - TIM_WARN1" 48 "Diag Cell - CIM-REST_FAILURE" 47 "Diag Cell - CIM-REST_FAULT" 46 "Diag Cell - CIM-REST_WARN2" 45 "Diag Cell - CIM-REST_WARN1" 44 "Diag Cell - CIM-CHG_FAILURE" 43 "Diag Cell - CIM-CHG_FAULT" 42 "Diag Cell - CIM-CHG_WARN2" 41 "Diag Cell - CIM-CHG_WARN1" 40 "Diag Cell - UDTP_FAILURE" 39 "Diag Cell - UDTP_FAULT" 38 "Diag Cell - UDTP_WARN2" 37 "Diag Cell - UDTP_WARN1" 36 "Diag Cell - UCTP_FAILURE" 35 "Diag Cell - UCTP_FAULT" 34 "Diag Cell - UCTP_WARN2" 33 "Diag Cell - UCTP_WARN1" 32 "Diag Cell - ODTP_FAILURE" 31 "Diag Cell - ODTP_FAULT" 30 "Diag Cell - ODTP_WARN2" 29 "Diag Cell - ODTP_WARN1" 28 "Diag Cell - OCTP_FAILURE" 27 "Diag Cell - OCTP_FAULT" 26 "Diag Cell - OCTP_WARN2" 25 "Diag Cell - OCTP_WARN1" 24 "Diag Cell - ODCP_FAILURE" 23 "Diag Cell - ODCP_FAULT" 22 "Diag Cell - ODCP_WARN2" 21 "Diag Cell - ODCP_WARN1" 20 "Diag Cell - OCCP_FAILURE" 19 "Diag Cell - OCCP_FAULT" 18 "Diag Cell - OCCP_WARN2" 17 "Diag Cell - OCCP_WARN1" 16 "Diag Cell - UVP_PACK_FAILURE" 15 "Diag Cell - UVP_PACK_FAULT" 14 "Diag Cell - UVP_PACK_WARN2" 13 "Diag Cell - UVP_PACK_WARN1" 12 "Diag Cell - OVP_PACK_FAILURE" 11 "Diag Cell - OVP_PACK_FAULT" 10 "Diag Cell - OVP_PACK_WARN2" 9 "Diag Cell - OVP_PACK_WARN1" 8 "Diag Cell - UVP_FAILURE" 7 "Diag Cell - UVP_FAULT" 6 "Diag Cell - UVP_WARN2" 5 "Diag Cell - UVP_WARN1" 4 "Diag Cell - OVP_FAILURE" 3 "Diag Cell - OVP_FAULT" 2 "Diag Cell - OVP_WARN2" 1 "Diag Cell - OVP_WARN1" 0 "NORMAL" ;
VAL_ 784 bms0_stsCurrentDirection 0 "REST" 1 "CHARGING" 2 "DISCHARGING" ;
VAL_ 784 bms0_stsIgnitionRecog 0 "DISABLE" 1 "ENABLE" ;
VAL_ 784 bms0_stsBmsMode 0 "STANDBY Mode" 1 "SNA" 2 "SNA" 3 "WORKING Mode" ;
